VERSION ""

NS_ :

BS_:

BU_: WPC2 PSB SHVU_RR vHS_B2 FCS EMCU SLB GW_APSU GW_DLBCU RCM ARS CGW_CCU vDummy_HS_B GW_RLPSU ATS RLHV SGU PFSU GW_RRPSU ALBCU DSAU SWRC SHVU_FR RCS GW_DPSU BLTN_CAM SCM OHCL RWPC RRHV WPC HOD ASAU

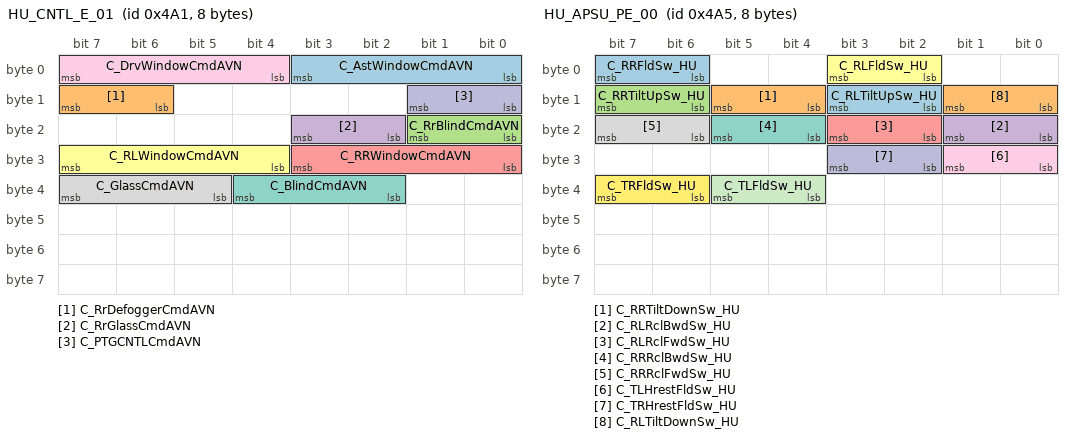
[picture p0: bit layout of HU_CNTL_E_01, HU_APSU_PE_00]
BO_ 1185 HU_CNTL_E_01: 8 CGW_CCU
 SG_ C_AstWindowCmdAVN : 0|4@1+ (1,0) [0|0] ""  Vector__XXX
 SG_ C_RrDefoggerCmdAVN : 14|2@1+ (1,0) [0|0] ""  Vector__XXX
 SG_ C_RrBlindCmdAVN : 16|2@1+ (1,0) [0|0] ""  RCM
 SG_ C_RrGlassCmdAVN : 18|2@1+ (1,0) [0|0] ""  RCM
 SG_ C_RRWindowCmdAVN : 24|4@1+ (1,0) [0|0] ""  Vector__XXX
 SG_ C_RLWindowCmdAVN : 28|4@1+ (1,0) [0|0] ""  Vector__XXX
 SG_ C_BlindCmdAVN : 34|3@1+ (1,0) [0|0] ""  RCM
 SG_ C_GlassCmdAVN : 37|3@1+ (1,0) [0|0] ""  RCM
 SG_ C_DrvWindowCmdAVN : 4|4@1+ (1,0) [0|0] ""  Vector__XXX
 SG_ C_PTGCNTLCmdAVN : 8|2@1+ (1,0) [0|0] ""  Vector__XXX

BO_ 1189 HU_APSU_PE_00: 8 CGW_CCU
 SG_ C_RLTiltUpSw_HU : 10|2@1+ (1,0) [0|0] ""  GW_APSU,GW_RLPSU,GW_RRPSU
 SG_ C_RRTiltDownSw_HU : 12|2@1+ (1,0) [0|0] ""  GW_APSU,GW_RRPSU
 SG_ C_RRTiltUpSw_HU : 14|2@1+ (1,0) [0|0] ""  GW_APSU,GW_RRPSU
 SG_ C_RLRclBwdSw_HU : 16|2@1+ (1,0) [0|0] ""  GW_APSU,GW_RLPSU,GW_RRPSU
 SG_ C_RLRclFwdSw_HU : 18|2@1+ (1,0) [0|0] ""  GW_APSU,GW_RLPSU,GW_RRPSU
 SG_ C_RLFldSw_HU : 2|2@1+ (1,0) [0|0] ""  GW_RLPSU
 SG_ C_RRRclBwdSw_HU : 20|2@1+ (1,0) [0|0] ""  GW_APSU,GW_RRPSU
 SG_ C_RRRclFwdSw_HU : 22|2@1+ (1,0) [0|0] ""  GW_APSU,GW_RRPSU
 SG_ C_TLHrestFldSw_HU : 24|2@1+ (1,0) [0|0] ""  PFSU
 SG_ C_TRHrestFldSw_HU : 26|2@1+ (1,0) [0|0] ""  PFSU
 SG_ C_TLFldSw_HU : 36|2@1+ (1,0) [0|0] ""  PFSU
 SG_ C_TRFldSw_HU : 38|2@1+ (1,0) [0|0] ""  PFSU
 SG_ C_RRFldSw_HU : 6|2@1+ (1,0) [0|0] ""  GW_RRPSU
 SG_ C_RLTiltDownSw_HU : 8|2@1+ (1,0) [0|0] ""  GW_APSU,GW_RLPSU,GW_RRPSU

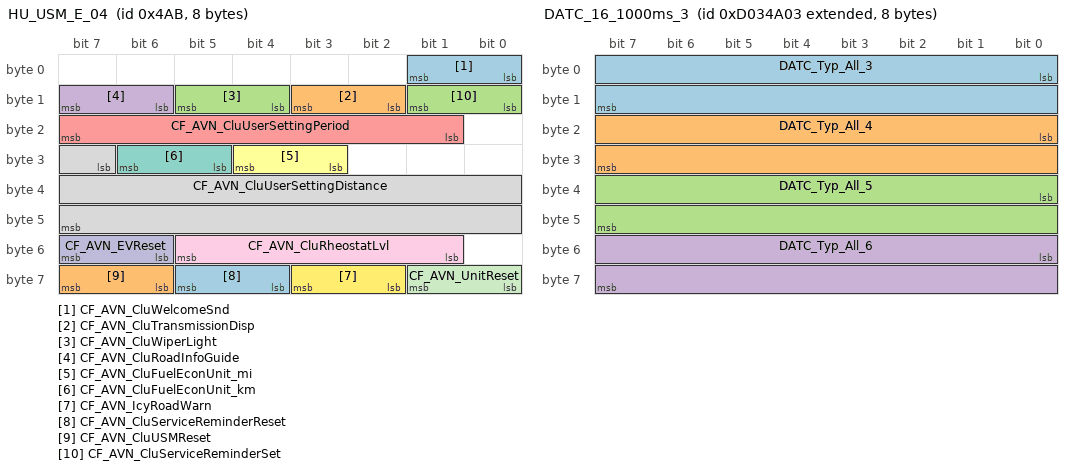
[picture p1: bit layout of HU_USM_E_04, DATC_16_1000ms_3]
BO_ 1195 HU_USM_E_04: 8 CGW_CCU
 SG_ CF_AVN_CluWelcomeSnd : 0|2@1+ (1,0) [0|0] ""  Vector__XXX
 SG_ CF_AVN_CluTransmissionDisp : 10|2@1+ (1,0) [0|0] ""  Vector__XXX
 SG_ CF_AVN_CluWiperLight : 12|2@1+ (1,0) [0|0] ""  Vector__XXX
 SG_ CF_AVN_CluRoadInfoGuide : 14|2@1+ (1,0) [0|0] ""  Vector__XXX
 SG_ CF_AVN_CluUserSettingPeriod : 17|7@1+ (1,0) [0|0] ""  Vector__XXX
 SG_ CF_AVN_CluFuelEconUnit_mi : 27|2@1+ (1,0) [0|0] ""  Vector__XXX
 SG_ CF_AVN_CluFuelEconUnit_km : 29|2@1+ (1,0) [0|0] ""  Vector__XXX
 SG_ CF_AVN_CluUserSettingDistance : 31|17@1+ (1,0) [0|0] ""  Vector__XXX
 SG_ CF_AVN_CluRheostatLvl : 49|5@1+ (1,0) [0|0] ""  Vector__XXX
 SG_ CF_AVN_EVReset : 54|2@1+ (1,0) [0|0] ""  Vector__XXX
 SG_ CF_AVN_UnitReset : 56|2@1+ (1,0) [0|0] ""  Vector__XXX
 SG_ CF_AVN_IcyRoadWarn : 58|2@1+ (1,0) [0|0] ""  Vector__XXX
 SG_ CF_AVN_CluServiceReminderReset : 60|2@1+ (1,0) [0|0] ""  Vector__XXX
 SG_ CF_AVN_CluUSMReset : 62|2@1+ (1,0) [0|0] ""  ALBCU,ARS,ASAU,ATS,BLTN_CAM,DSAU,GW_APSU,GW_DLBCU,GW_DPSU,GW_RLPSU,GW_RRPSU,PFSU,RCM,RLHV,RRHV,RWPC,SGU,SHVU_FR,SHVU_RR,SLB,WPC,WPC2
 SG_ CF_AVN_CluServiceReminderSet : 8|2@1+ (1,0) [0|0] ""  Vector__XXX

BO_ 1193 HU_USM_E_02: 8 CGW_CCU
 SG_ C_PTGMNValueSet : 0|2@1+ (1,0) [0|0] ""  Vector__XXX
 SG_ CF_AVN_PSMNValueSet : 10|3@1+ (1,0) [0|0] ""  GW_DPSU
 SG_ C_HfreeTrunkTgNValueSet : 13|3@1+ (1,0) [0|0] ""  Vector__XXX
 SG_ CF_AVN_TrfChgSet : 17|2@1+ (1,0) [0|0] ""  Vector__XXX
 SG_ CF_AVN_SCMNValueSet : 19|2@1+ (1,0) [0|0] ""  Vector__XXX
 SG_ CF_AVN_ADrUNValueSet : 2|3@1+ (1,0) [0|0] ""  Vector__XXX
 SG_ CF_AVN_OTTurnNValueSet : 21|3@1+ (1,0) [0|0] ""  Vector__XXX
 SG_ CF_Gway_WPCNValueSet : 24|2@1+ (1,0) [0|0] ""  WPC,WPC2
 SG_ C_AVN_RearWiperNValueSet : 26|2@1+ (1,0) [0|0] ""  Vector__XXX
 SG_ C_UnlockWelocomeNValueSet : 28|2@1+ (1,0) [0|0] ""  Vector__XXX
 SG_ C_SmartWelocomeNValueSet : 30|2@1+ (1,0) [0|0] ""  Vector__XXX
 SG_ CF_AVN_PTGSpeedNValueSet : 32|2@1+ (1,0) [0|0] ""  Vector__XXX
 SG_ CR_Datc_DRSeatWheel_USM_Set : 34|2@1+ (1,0) [0|0] ""  Vector__XXX
 SG_ CF_AVN_TTUnlockNValueSet : 38|2@1+ (1,0) [0|0] ""  Vector__XXX
 SG_ CF_Gway_RWPCNValueSet : 40|2@1+ (1,0) [0|0] ""  RWPC
 SG_ CF_Avn_HAPTICWARNINGNValueSet : 49|3@1+ (1,0) [0|0] ""  Vector__XXX
 SG_ CR_Datc_DRSeatHeat_USM_Set : 52|2@1+ (1,0) [0|0] ""  Vector__XXX
 SG_ C_WALNValueSet : 54|2@1+ (1,0) [0|0] ""  Vector__XXX
 SG_ C_ApprUnlockNValue : 56|2@1+ (1,0) [0|0] ""  Vector__XXX
 SG_ CF_AVN_EscortHLNValueSet : 8|2@1+ (1,0) [0|0] ""  Vector__XXX

BO_ 2365803012 DATC_16_1000ms_4: 8 CGW_CCU
 SG_ DATC_Opt_Sys : 0|32@1+ (1,0) [0|0] ""  Vector__XXX
 SG_ DATC_Opt_Func : 32|32@1+ (1,0) [0|0] ""  Vector__XXX

BO_ 2365803011 DATC_16_1000ms_3: 8 CGW_CCU
 SG_ DATC_Typ_All_3 : 0|16@1+ (1,0) [0|0] ""  Vector__XXX
 SG_ DATC_Typ_All_4 : 16|16@1+ (1,0) [0|0] ""  Vector__XXX
 SG_ DATC_Typ_All_5 : 32|16@1+ (1,0) [0|0] ""  Vector__XXX
 SG_ DATC_Typ_All_6 : 48|16@1+ (1,0) [0|0] ""  Vector__XXX

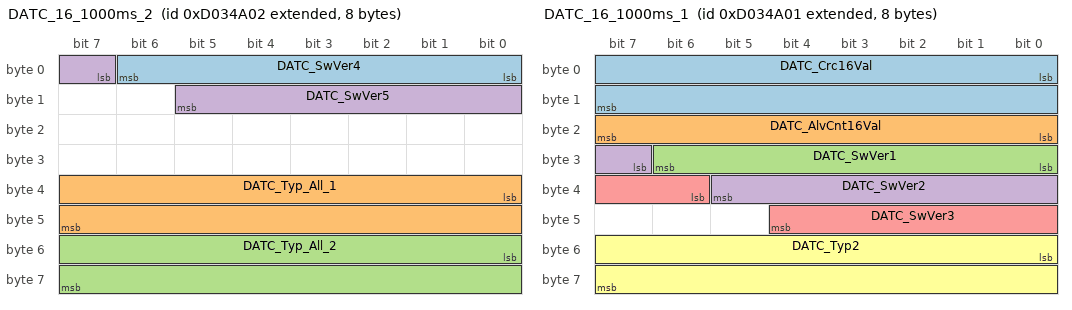
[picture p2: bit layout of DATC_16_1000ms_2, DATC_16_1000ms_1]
BO_ 2365803010 DATC_16_1000ms_2: 8 CGW_CCU
 SG_ DATC_SwVer4 : 0|7@1+ (1,0) [0|0] ""  Vector__XXX
 SG_ DATC_Typ_All_1 : 32|16@1+ (1,0) [0|0] ""  Vector__XXX
 SG_ DATC_Typ_All_2 : 48|16@1+ (1,0) [0|0] ""  Vector__XXX
 SG_ DATC_SwVer5 : 7|7@1+ (1,0) [0|0] ""  Vector__XXX

BO_ 2365803009 DATC_16_1000ms_1: 8 CGW_CCU
 SG_ DATC_Crc16Val : 0|16@1+ (1,0) [0|0] ""  Vector__XXX
 SG_ DATC_AlvCnt16Val : 16|8@1+ (1,0) [0|0] ""  Vector__XXX
 SG_ DATC_SwVer1 : 24|7@1+ (1,0) [0|0] ""  Vector__XXX
 SG_ DATC_SwVer2 : 31|7@1+ (1,0) [0|0] ""  Vector__XXX
 SG_ DATC_SwVer3 : 38|7@1+ (1,0) [0|0] ""  Vector__XXX
 SG_ DATC_Typ2 : 48|16@1+ (1,0) [0|0] ""  ATS

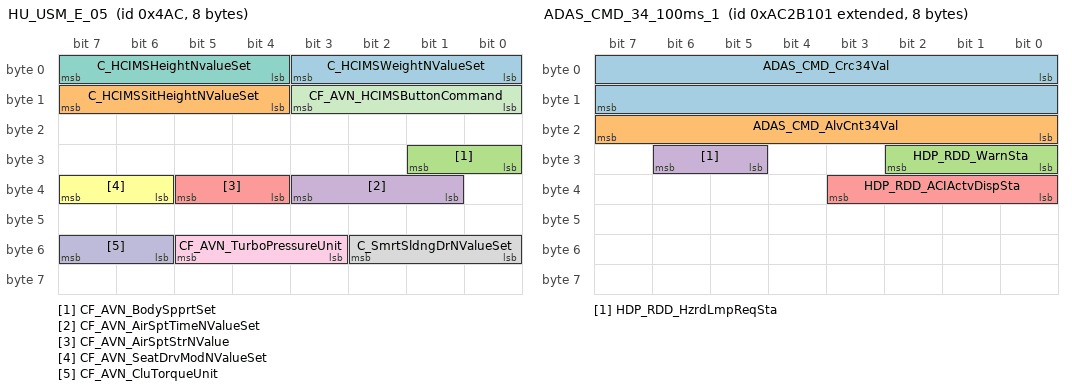
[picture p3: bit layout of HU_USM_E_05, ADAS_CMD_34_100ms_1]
BO_ 1196 HU_USM_E_05: 8 CGW_CCU
 SG_ C_HCIMSWeightNValueSet : 0|4@1+ (1,0) [0|0] ""  GW_DPSU
 SG_ C_HCIMSSitHeightNValueSet : 12|4@1+ (1,0) [0|0] ""  GW_DPSU
 SG_ CF_AVN_BodySpprtSet : 24|2@1+ (1,0) [0|0] ""  DSAU,GW_DLBCU,GW_DPSU
 SG_ CF_AVN_AirSptTimeNValueSet : 33|3@1+ (1,0) [0|0] ""  GW_DLBCU
 SG_ CF_AVN_AirSptStrNValue : 36|2@1+ (1,0) [0|0] ""  GW_DLBCU
 SG_ CF_AVN_SeatDrvModNValueSet : 38|2@1+ (1,0) [0|0] ""  DSAU,GW_DLBCU,GW_DPSU
 SG_ C_HCIMSHeightNvalueSet : 4|4@1+ (1,0) [0|0] ""  GW_DPSU
 SG_ C_SmrtSldngDrNValueSet : 48|3@1+ (1,0) [0|0] ""  Vector__XXX
 SG_ CF_AVN_TurboPressureUnit : 51|3@1+ (1,0) [0|0] ""  Vector__XXX
 SG_ CF_AVN_CluTorqueUnit : 54|2@1+ (1,0) [0|0] ""  Vector__XXX
 SG_ CF_AVN_HCIMSButtonCommand : 8|4@1+ (1,0) [0|0] ""  GW_DPSU

BO_ 2328015108 ADAS_CMD_34_100ms_4: 8 CGW_CCU

BO_ 255 BCM_20_200ms: 8 CGW_CCU
 SG_ BCM_Crc20Val : 0|8@1+ (1,0) [0|0] ""  RCM
 SG_ Window_BuffetRdctnActvSta : 10|2@1+ (1,0) [0|0] ""  Vector__XXX
 SG_ BCM_AlvCnt20Val : 12|4@1+ (1,0) [0|0] ""  RCM
 SG_ BckGls_RrGlsHtdOnCmd : 16|2@1+ (1,0) [0|0] ""  Vector__XXX
 SG_ Wndshld_FrtGlsHtdOnCmd : 18|2@1+ (1,0) [0|0] ""  Vector__XXX
 SG_ Mirror_MirFldOpt : 20|2@1+ (1,0) [0|0] ""  Vector__XXX
 SG_ Window_AsstPwrWdwSunroofEnblSta : 22|2@1+ (1,0) [0|0] ""  RCM
 SG_ Window_RrPwrWdwEnblSta : 24|2@1+ (1,0) [0|0] ""  RCM
 SG_ Window_RrPwrWdwLkInd : 26|2@1+ (1,0) [0|0] ""  Vector__XXX
 SG_ Window_DrvPwrWdwCmd : 28|2@1+ (1,0) [0|0] ""  Vector__XXX
 SG_ Window_AsstPwrWdwCmd : 30|2@1+ (1,0) [0|0] ""  Vector__XXX
 SG_ Window_RrLftPwrWdwCmd : 32|2@1+ (1,0) [0|0] ""  Vector__XXX
 SG_ Window_RrRtPwrWdwCmd : 34|2@1+ (1,0) [0|0] ""  Vector__XXX
 SG_ Mirror_FldUnfldCmd : 36|2@1+ (1,0) [0|0] ""  Vector__XXX
 SG_ Mirror_FldCtrlSta : 38|2@1+ (1,0) [0|0] ""  Vector__XXX
 SG_ Mirror_UnFldCtrlSta : 40|2@1+ (1,0) [0|0] ""  Vector__XXX
 SG_ Mirror_PosMnlCmd : 42|3@1+ (1,0) [0|0] ""  Vector__XXX
 SG_ Mirror_SelSwIndCmd : 45|3@1+ (1,0) [0|0] ""  Vector__XXX
 SG_ BCM_SafetyWdwOptTyp2 : 49|3@1+ (1,0) [0|0] ""  Vector__XXX
 SG_ Mirror_LHOSMirPlyBckSta : 52|4@1+ (1,0) [0|0] ""  GW_DPSU
 SG_ Mirror_RHOSMirPlyBckSta : 56|4@1+ (1,0) [0|0] ""  GW_DPSU
 SG_ Mirror_SelSwSta : 60|3@1+ (1,0) [0|0] ""  Vector__XXX
 SG_ BckGls_RrGlsHtdOpt : 8|2@1+ (1,0) [0|0] ""  Vector__XXX

BO_ 2328015105 ADAS_CMD_34_100ms_1: 8 CGW_CCU
 SG_ ADAS_CMD_Crc34Val : 0|16@1+ (1,0) [0|0] ""  Vector__XXX
 SG_ ADAS_CMD_AlvCnt34Val : 16|8@1+ (1,0) [0|0] ""  Vector__XXX
 SG_ HDP_RDD_WarnSta : 24|3@1+ (1,0) [0|0] ""  HOD,PSB
 SG_ HDP_RDD_HzrdLmpReqSta : 29|2@1+ (1,0) [0|0] ""  Vector__XXX
 SG_ HDP_RDD_ACIActvDispSta : 32|4@1+ (1,0) [0|0] ""  Vector__XXX

BO_ 2328015106 ADAS_CMD_34_100ms_2: 8 CGW_CCU
 SG_ HDP_RDD_EMStbltActvReqSta : 8|3@1+ (1,0) [0|0] ""  PSB

BO_ 2328015107 ADAS_CMD_34_100ms_3: 8 CGW_CCU

BO_ 273 ARS_04_00ms: 8 ARS
 SG_ ARS_RrCurtainBtn : 0|2@1+ (1,0) [0|0] ""  Vector__XXX

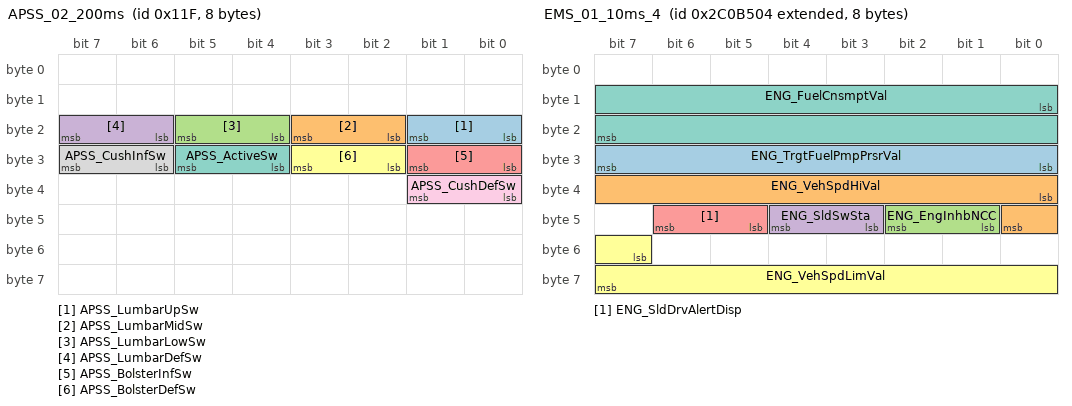
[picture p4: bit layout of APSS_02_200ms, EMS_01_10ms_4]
BO_ 287 APSS_02_200ms: 8 GW_APSU
 SG_ APSS_LumbarUpSw : 16|2@1+ (1,0) [0|0] ""  ALBCU,CGW_CCU
 SG_ APSS_LumbarMidSw : 18|2@1+ (1,0) [0|0] ""  ALBCU,CGW_CCU
 SG_ APSS_LumbarLowSw : 20|2@1+ (1,0) [0|0] ""  ALBCU,CGW_CCU
 SG_ APSS_LumbarDefSw : 22|2@1+ (1,0) [0|0] ""  ALBCU,CGW_CCU
 SG_ APSS_BolsterInfSw : 24|2@1+ (1,0) [0|0] ""  ALBCU,CGW_CCU
 SG_ APSS_BolsterDefSw : 26|2@1+ (1,0) [0|0] ""  ALBCU,CGW_CCU
 SG_ APSS_ActiveSw : 28|2@1+ (1,0) [0|0] ""  ALBCU
 SG_ APSS_CushInfSw : 30|2@1+ (1,0) [0|0] ""  ALBCU
 SG_ APSS_CushDefSw : 32|2@1+ (1,0) [0|0] ""  ALBCU

BO_ 2193667332 EMS_01_10ms_4: 8 CGW_CCU
 SG_ ENG_TrgtFuelPmpPrsrVal : 24|8@1+ (3.137254902,0) [0|0] "kPa"  Vector__XXX
 SG_ ENG_VehSpdHiVal : 32|9@1+ (1,0) [0|0] "km/h"  Vector__XXX
 SG_ ENG_EngInhbNCC : 41|2@1+ (1,0) [0|0] ""  Vector__XXX
 SG_ ENG_SldSwSta : 43|2@1+ (1,0) [0|0] ""  Vector__XXX
 SG_ ENG_SldDrvAlertDisp : 45|2@1+ (1,0) [0|0] ""  Vector__XXX
 SG_ ENG_VehSpdLimVal : 55|9@1+ (1,0) [0|0] "km/h"  Vector__XXX
 SG_ ENG_FuelCnsmptVal : 8|16@1+ (0.128,0) [0|0] "ul"  Vector__XXX

BO_ 2193667331 EMS_01_10ms_3: 8 CGW_CCU
 SG_ ENG_TrgtIdleRpmVal : 0|8@1+ (10,0) [0|0] "rpm"  Vector__XXX
 SG_ ENG_GearShftDnDis : 10|2@1+ (1,0) [0|0] ""  Vector__XXX
 SG_ ENG_DsrGearPosDis : 12|4@1+ (1,0) [0|0] ""  Vector__XXX
 SG_ ENG_SldFuncSta : 16|2@1+ (1,0) [0|0] ""  Vector__XXX
 SG_ ENG_SldActnSta : 18|2@1+ (1,0) [0|0] ""  Vector__XXX
 SG_ ENG_FuelTnkPrsrSta : 20|2@1+ (1,0) [0|0] ""  Vector__XXX
 SG_ ENG_IsgBzrReq : 22|2@1+ (1,0) [0|0] ""  Vector__XXX
 SG_ ENG_IsgFuelCnsmptDis : 24|2@1+ (1,0) [0|0] ""  Vector__XXX
 SG_ ENG_FuelCapOpnSta : 26|2@1+ (1,0) [0|0] ""  Vector__XXX
 SG_ ENG_EcoDrvActvSta : 28|2@1+ (1,0) [0|0] ""  Vector__XXX
 SG_ ENG_EngRunSta : 30|2@1+ (1,0) [0|0] ""  Vector__XXX
 SG_ ENG_Isg2Sta : 32|2@1+ (2,0) [0|0] ""  Vector__XXX
 SG_ ENG_IgnOnSta : 34|2@1+ (1,0) [0|0] ""  Vector__XXX
 SG_ ENG_Ack4TcsSta : 36|2@1+ (1,0) [0|0] ""  Vector__XXX
 SG_ ENG_FuelCutOffSta : 38|2@1+ (1,0) [0|0] ""  Vector__XXX
 SG_ ENG_CrctTqSta : 40|2@1+ (1,0) [0|0] ""  Vector__XXX
 SG_ ENG_AirCompRlySta : 42|2@1+ (1,0) [0|0] ""  Vector__XXX
 SG_ ENG_LnchCntrlSta : 45|3@1+ (1,0) [0|0] ""  Vector__XXX
 SG_ ENG_EngSpdVal : 48|16@1+ (0.25,0) [0|0] "rpm"  EMCU
 SG_ ENG_GearShftUpDis : 8|2@1+ (1,0) [0|0] ""  Vector__XXX

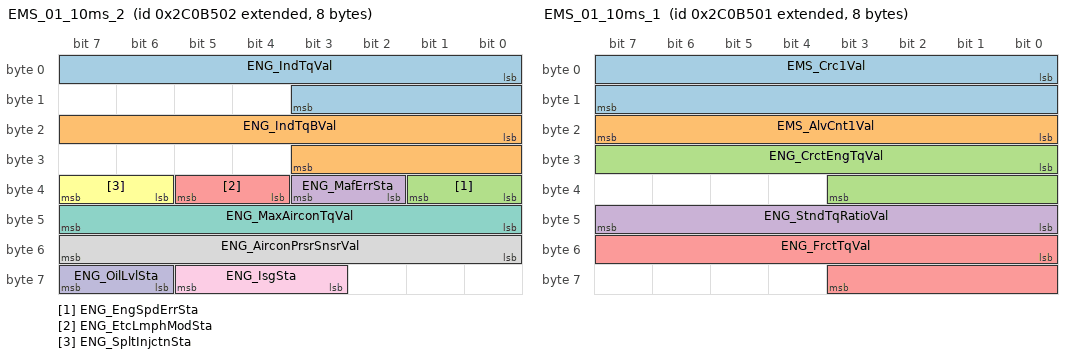
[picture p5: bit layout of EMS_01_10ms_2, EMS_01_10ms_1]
BO_ 2193667330 EMS_01_10ms_2: 8 CGW_CCU
 SG_ ENG_IndTqVal : 0|12@1- (1,0) [0|0] "Nm"  Vector__XXX
 SG_ ENG_IndTqBVal : 16|12@1- (1,0) [0|0] "Nm"  Vector__XXX
 SG_ ENG_EngSpdErrSta : 32|2@1+ (1,0) [0|0] ""  Vector__XXX
 SG_ ENG_MafErrSta : 34|2@1+ (1,0) [0|0] ""  Vector__XXX
 SG_ ENG_EtcLmphModSta : 36|2@1+ (1,0) [0|0] ""  Vector__XXX
 SG_ ENG_SpltInjctnSta : 38|2@1+ (1,0) [0|0] ""  Vector__XXX
 SG_ ENG_MaxAirconTqVal : 40|8@1+ (0.2,0) [0|0] "Nm"  Vector__XXX
 SG_ ENG_AirconPrsrSnsrVal : 48|8@1+ (125,0) [0|0] "hPa"  Vector__XXX
 SG_ ENG_IsgSta : 59|3@1+ (1,0) [0|0] ""  EMCU,GW_APSU,GW_DPSU,GW_RLPSU,GW_RRPSU,RLHV,RRHV,SHVU_FR,SHVU_RR
 SG_ ENG_OilLvlSta : 62|2@1+ (1,0) [0|0] ""  Vector__XXX

BO_ 2193667329 EMS_01_10ms_1: 8 CGW_CCU
 SG_ EMS_Crc1Val : 0|16@1+ (1,0) [0|0] ""  Vector__XXX
 SG_ EMS_AlvCnt1Val : 16|8@1+ (1,0) [0|0] ""  Vector__XXX
 SG_ ENG_CrctEngTqVal : 24|12@1- (1,0) [0|0] "Nm"  Vector__XXX
 SG_ ENG_StndTqRatioVal : 40|8@1+ (0.0078,0) [0|0] ""  Vector__XXX
 SG_ ENG_FrctTqVal : 48|12@1- (1,0) [0|0] "Nm"  Vector__XXX

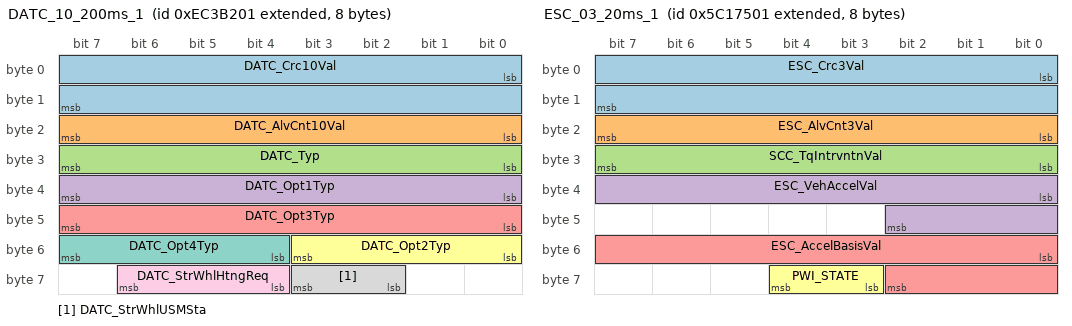
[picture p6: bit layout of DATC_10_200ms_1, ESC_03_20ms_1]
BO_ 2395189761 DATC_10_200ms_1: 8 CGW_CCU
 SG_ DATC_Crc10Val : 0|16@1+ (1,0) [0|0] ""  Vector__XXX
 SG_ DATC_AlvCnt10Val : 16|8@1+ (1,0) [0|0] ""  Vector__XXX
 SG_ DATC_Typ : 24|8@1+ (1,0) [0|0] ""  ATS,RLHV,RRHV,SHVU_FR,SHVU_RR
 SG_ DATC_Opt1Typ : 32|8@1+ (1,0) [0|0] ""  ATS
 SG_ DATC_Opt3Typ : 40|8@1+ (1,0) [0|0] ""  ATS
 SG_ DATC_Opt2Typ : 48|4@1+ (1,0) [0|0] ""  ATS
 SG_ DATC_Opt4Typ : 52|4@1+ (1,0) [0|0] ""  ATS
 SG_ DATC_StrWhlUSMSta : 58|2@1+ (1,0) [0|0] ""  GW_APSU
 SG_ DATC_StrWhlHtngReq : 60|3@1+ (1,0) [0|0] ""  Vector__XXX

BO_ 2244048129 ESC_03_20ms_1: 8 CGW_CCU
 SG_ ESC_Crc3Val : 0|16@1+ (1,0) [0|0] ""  Vector__XXX
 SG_ ESC_AlvCnt3Val : 16|8@1+ (1,0) [0|0] ""  Vector__XXX
 SG_ SCC_TqIntrvntnVal : 24|8@1+ (0.390625,0) [0|0] "%"  Vector__XXX
 SG_ ESC_VehAccelVal : 32|11@1+ (0.01,-10.23) [0|0] "m/s^2"  Vector__XXX
 SG_ ESC_AccelBasisVal : 48|11@1+ (0.01,-10.23) [0|0] "m/s^2"  Vector__XXX
 SG_ PWI_STATE : 59|2@1+ (1,0) [0|0] ""  Vector__XXX

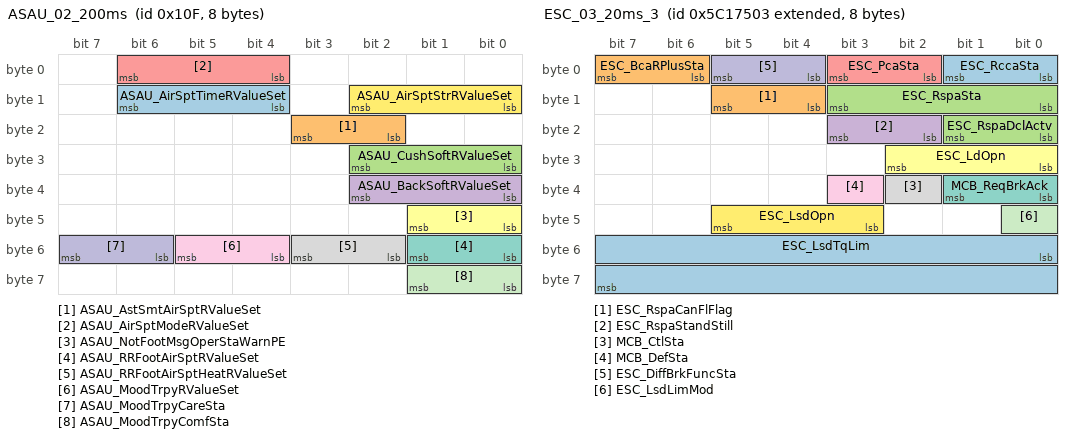
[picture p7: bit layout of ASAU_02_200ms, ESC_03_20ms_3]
BO_ 271 ASAU_02_200ms: 8 ASAU
 SG_ ASAU_AirSptTimeRValueSet : 12|3@1+ (1,0) [0|0] ""  CGW_CCU
 SG_ ASAU_AstSmtAirSptRValueSet : 18|2@1+ (1,0) [0|0] ""  CGW_CCU
 SG_ ASAU_CushSoftRValueSet : 24|3@1+ (1,0) [0|0] ""  CGW_CCU
 SG_ ASAU_BackSoftRValueSet : 32|3@1+ (1,0) [0|0] ""  Vector__XXX
 SG_ ASAU_AirSptModeRValueSet : 4|3@1+ (1,0) [0|0] ""  CGW_CCU
 SG_ ASAU_NotFootMsgOperStaWarnPE : 40|2@1+ (1,0) [0|0] ""  ATS
 SG_ ASAU_RRFootAirSptRValueSet : 48|2@1+ (1,0) [0|0] ""  ATS
 SG_ ASAU_RRFootAirSptHeatRValueSet : 50|2@1+ (1,0) [0|0] ""  ATS
 SG_ ASAU_MoodTrpyRValueSet : 52|2@1+ (1,0) [0|0] ""  CGW_CCU
 SG_ ASAU_MoodTrpyCareSta : 54|2@1+ (1,0) [0|0] ""  CGW_CCU
 SG_ ASAU_MoodTrpyComfSta : 56|2@1+ (1,0) [0|0] ""  CGW_CCU
 SG_ ASAU_AirSptStrRValueSet : 8|3@1+ (1,0) [0|0] ""  CGW_CCU

BO_ 2244048131 ESC_03_20ms_3: 8 CGW_CCU
 SG_ ESC_RccaSta : 0|2@1+ (1,0) [0|0] ""  Vector__XXX
 SG_ ESC_RspaCanFlFlag : 12|2@1+ (1,0) [0|0] ""  Vector__XXX
 SG_ ESC_RspaDclActv : 16|2@1+ (1,0) [0|0] ""  Vector__XXX
 SG_ ESC_RspaStandStill : 18|2@1+ (1,0) [0|0] ""  Vector__XXX
 SG_ ESC_PcaSta : 2|2@1+ (1,0) [0|0] ""  Vector__XXX
 SG_ ESC_LdOpn : 24|3@1+ (1,0) [0|0] ""  Vector__XXX
 SG_ MCB_ReqBrkAck : 32|2@1+ (1,0) [0|0] ""  Vector__XXX
 SG_ MCB_CtlSta : 34|1@1+ (1,0) [0|0] ""  Vector__XXX
 SG_ MCB_DefSta : 35|1@1+ (1,0) [0|0] ""  Vector__XXX
 SG_ ESC_DiffBrkFuncSta : 4|2@1+ (1,0) [0|0] ""  Vector__XXX
 SG_ ESC_LsdLimMod : 40|1@1+ (1,0) [0|0] ""  Vector__XXX
 SG_ ESC_LsdOpn : 43|3@1+ (1,0) [0|0] ""  Vector__XXX
 SG_ ESC_LsdTqLim : 48|16@1+ (1,0) [0|0] "Nm"  Vector__XXX
 SG_ ESC_BcaRPlusSta : 6|2@1+ (1,0) [0|0] ""  Vector__XXX
 SG_ ESC_RspaSta : 8|4@1+ (1,0) [0|0] ""  Vector__XXX

BO_ 2244048130 ESC_03_20ms_2: 8 CGW_CCU
 SG_ SCC_OptTyp : 0|2@1+ (1,0) [0|0] ""  Vector__XXX
 SG_ ESC_BrkLtReq : 10|2@1+ (1,0) [0|0] ""  Vector__XXX
 SG_ ESC_DclEnblReq : 12|2@1+ (1,0) [0|0] ""  Vector__XXX
 SG_ ESC_DrvOvrdSta : 16|2@1+ (1,0) [0|0] ""  Vector__XXX
 SG_ ESC_DrvBrkSta : 18|2@1+ (1,0) [0|0] ""  Vector__XXX
 SG_ SCC_EnblReq : 2|2@1+ (1,0) [0|0] ""  Vector__XXX
 SG_ ESC_DrvBrkActvSta : 20|2@1+ (1,0) [0|0] ""  Vector__XXX
 SG_ ESC_PrkBrkActvSta : 22|2@1+ (1,0) [0|0] ""  Vector__XXX
 SG_ ESC_HDP_FltMonSta : 24|3@1+ (1,0) [0|0] ""  PSB
 SG_ ESC_HDPSpprtSWVer : 27|5@1+ (1,0) [0|0] ""  Vector__XXX
 SG_ FCA_EquipSta : 32|2@1+ (1,0) [0|0] ""  Vector__XXX
 SG_ FCA_AvlblSta : 34|2@1+ (1,0) [0|0] ""  Vector__XXX
 SG_ ESC_FCA_ActvSta : 36|2@1+ (1,0) [0|0] ""  Vector__XXX
 SG_ ESC_DBS_ActvSta : 38|2@1+ (1,0) [0|0] ""  Vector__XXX
 SG_ SCC_TqReq : 4|2@1+ (1,0) [0|0] ""  Vector__XXX
 SG_ ESC_HDP_EgSta : 40|3@1+ (1,0) [0|0] ""  PSB
 SG_ ESC_HDP_EnblReq : 43|3@1+ (1,0) [0|0] ""  Vector__XXX
 SG_ CSC_Sta : 48|2@1+ (1,0) [0|0] ""  Vector__XXX
 SG_ CSC_WrngSta : 50|2@1+ (1,0) [0|0] ""  Vector__XXX
 SG_ ESC_BrkdFltStndstill : 56|2@1+ (1,0) [0|0] ""  Vector__XXX
 SG_ SCC_ReqLimSta : 6|2@1+ (1,0) [0|0] ""  Vector__XXX
 SG_ ESC_StdStillVal : 8|2@1+ (1,0) [0|0] ""  Vector__XXX

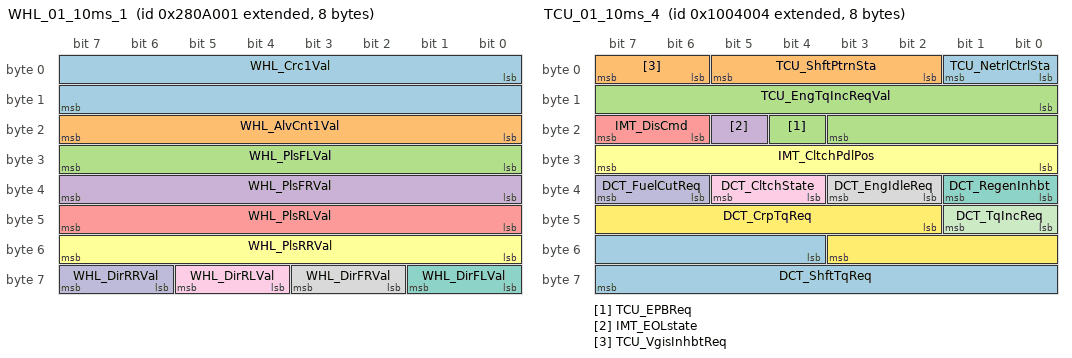
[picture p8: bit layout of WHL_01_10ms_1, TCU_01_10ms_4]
BO_ 2189467649 WHL_01_10ms_1: 8 CGW_CCU
 SG_ WHL_Crc1Val : 0|16@1+ (1,0) [0|0] ""  Vector__XXX
 SG_ WHL_AlvCnt1Val : 16|8@1+ (1,0) [0|0] ""  Vector__XXX
 SG_ WHL_PlsFLVal : 24|8@1+ (0.5,0) [0|0] "pulse count"  Vector__XXX
 SG_ WHL_PlsFRVal : 32|8@1+ (0.5,0) [0|0] "pulse count"  Vector__XXX
 SG_ WHL_PlsRLVal : 40|8@1+ (0.5,0) [0|0] "pulse count"  Vector__XXX
 SG_ WHL_PlsRRVal : 48|8@1+ (0.5,0) [0|0] "pulse count"  Vector__XXX
 SG_ WHL_DirFLVal : 56|2@1+ (1,0) [0|0] ""  Vector__XXX
 SG_ WHL_DirFRVal : 58|2@1+ (1,0) [0|0] ""  Vector__XXX
 SG_ WHL_DirRLVal : 60|2@1+ (1,0) [0|0] ""  Vector__XXX
 SG_ WHL_DirRRVal : 62|2@1+ (1,0) [0|0] ""  Vector__XXX

BO_ 2164277252 TCU_01_10ms_4: 8 CGW_CCU
 SG_ TCU_NetrlCtrlSta : 0|2@1+ (1,0) [0|0] ""  Vector__XXX
 SG_ TCU_ShftPtrnSta : 2|4@1+ (1,0) [0|0] ""  Vector__XXX
 SG_ TCU_EPBReq : 20|1@1+ (1,0) [0|0] ""  Vector__XXX
 SG_ IMT_EOLstate : 21|1@1+ (1,0) [0|0] ""  Vector__XXX
 SG_ IMT_DisCmd : 22|2@1+ (1,0) [0|0] ""  Vector__XXX
 SG_ IMT_CltchPdlPos : 24|8@1+ (0.390625,0) [0|0] "%"  Vector__XXX
 SG_ DCT_RegenInhbt : 32|2@1+ (1,0) [0|0] ""  Vector__XXX
 SG_ DCT_EngIdleReq : 34|2@1+ (1,0) [0|0] ""  Vector__XXX
 SG_ DCT_CltchState : 36|2@1+ (1,0) [0|0] ""  Vector__XXX
 SG_ DCT_FuelCutReq : 38|2@1+ (1,0) [0|0] ""  Vector__XXX
 SG_ DCT_TqIncReq : 40|2@1+ (1,0) [0|0] ""  Vector__XXX
 SG_ DCT_CrpTqReq : 42|10@1+ (1,-512) [0|0] "Nm"  Vector__XXX
 SG_ DCT_ShftTqReq : 52|12@1- (1,0) [0|0] "Nm"  Vector__XXX
 SG_ TCU_VgisInhbtReq : 6|2@1+ (1,0) [0|0] ""  Vector__XXX
 SG_ TCU_EngTqIncReqVal : 8|12@1- (1,0) [0|0] "Nm"  Vector__XXX

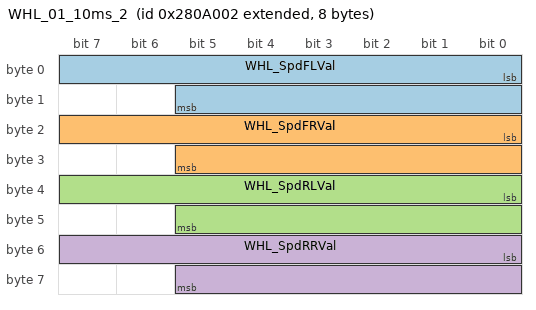
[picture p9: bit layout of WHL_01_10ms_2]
BO_ 2189467650 WHL_01_10ms_2: 8 CGW_CCU
 SG_ WHL_SpdFLVal : 0|14@1+ (0.03125,0) [0|0] "km^h"  PSB
 SG_ WHL_SpdFRVal : 16|14@1+ (0.03125,0) [0|0] "km^h"  PSB
 SG_ WHL_SpdRLVal : 32|14@1+ (0.03125,0) [0|0] "km^h"  GW_APSU,PSB
 SG_ WHL_SpdRRVal : 48|14@1+ (0.03125,0) [0|0] "km^h"  GW_APSU,PSB

BO_ 2189467651 WHL_01_10ms_3: 8 CGW_CCU
 SG_ WHL_SpdCalParmtr : 8|9@1+ (0.5,200) [0|0] "mm"  Vector__XXX

CM_ BO_ 2328015105 "[P] Periodic";
CM_ SG_ 2328015105 ADAS_CMD_Crc34Val "ADAS_CMD_CyclicRedundancyCheck34Value";
CM_ SG_ 2328015105 ADAS_CMD_AlvCnt34Val "ADAS_CMD_AliveCounter34Value";
CM_ SG_ 2328015105 HDP_RDD_WarnSta "HDP_RDD Warning State";
CM_ SG_ 2328015105 HDP_RDD_HzrdLmpReqSta "HDP_RDD Hazard Lamp Request State";
CM_ SG_ 2328015105 HDP_RDD_ACIActvDispSta "HDP_RDD AngleControlInterface Active Display State";
CM_ BO_ 2328015106 "[P] Periodic";
CM_ SG_ 2328015106 HDP_RDD_EMStbltActvReqSta "HDP_RDD EM Seatbelt Activate Request State";
CM_ BO_ 2328015107 "[P] Periodic";
CM_ BO_ 2328015108 "[P] Periodic";
CM_ BO_ 287 "[PE] Periodic and On Event";
CM_ SG_ 287 APSS_LumbarUpSw "APSS_LumbarUpMoveSwitch";
CM_ SG_ 287 APSS_LumbarMidSw "APSS_LumbarMiddleSwitch";
CM_ SG_ 287 APSS_LumbarLowSw "APSS_LumbarLowerSwitch";
CM_ SG_ 287 APSS_LumbarDefSw "APSS_LumbarDeflationSwitch";
CM_ SG_ 287 APSS_BolsterInfSw "APSS_BolsterInflationSwitch";
CM_ SG_ 287 APSS_BolsterDefSw "APSS_BolsterDeflationSwitch";
CM_ SG_ 287 APSS_ActiveSw "APSS_ActiveSwitch";
CM_ SG_ 287 APSS_CushInfSw "APSS_Cush Support Inflation Switch";
CM_ SG_ 287 APSS_CushDefSw "APSS_Cush Support Deflation Switch";
CM_ BO_ 273 "[EC] On Event and On Change";
CM_ SG_ 273 ARS_RrCurtainBtn "Rear Curtain Button";
CM_ BO_ 271 "[PE] Periodic and On Event";
CM_ SG_ 271 ASAU_AirSptTimeRValueSet "Air Support Time(Massage Time) USM R Value";
CM_ SG_ 271 ASAU_AstSmtAirSptRValueSet "Seat Smart Air Support Function USM R Value";
CM_ SG_ 271 ASAU_CushSoftRValueSet "Cushion Soft R Value";
CM_ SG_ 271 ASAU_BackSoftRValueSet "Back Soft USM R Value";
CM_ SG_ 271 ASAU_AirSptModeRValueSet "Air Support Mode(Massage Mode) USM R Value";
CM_ SG_ 271 ASAU_NotFootMsgOperStaWarnPE "Passenger Foot Massage Operation Disable Mode";
CM_ SG_ 271 ASAU_RRFootAirSptRValueSet "Foot Air Support USM R Value";
CM_ SG_ 271 ASAU_RRFootAirSptHeatRValueSet "Foot Air Support Heat USM R Value";
CM_ SG_ 271 ASAU_MoodTrpyRValueSet "Passenger Seat Mood Therapy R Value";
CM_ SG_ 271 ASAU_MoodTrpyCareSta "Passenger Seat Mood Therapy Care Mode R Value";
CM_ SG_ 271 ASAU_MoodTrpyComfSta "Passenger Seat Mood Therapy Comfort Mode R Value";
CM_ SG_ 271 ASAU_AirSptStrRValueSet "Air Support Strenth(Massage Strenth) USM R Value";
CM_ BO_ 255 "[PE] Periodic and On Event";
CM_ SG_ 255 BCM_Crc20Val "BCM_CyclicRedundancyCheck20Value";
CM_ SG_ 255 BCM_AlvCnt20Val "BCM_AliveCounter20Value";
CM_ SG_ 255 Mirror_MirFldOpt "Outside Mirror Electric Fold Option Signal";
CM_ SG_ 255 Mirror_FldUnfldCmd "Mirror Folding Unfolding Command";
CM_ SG_ 255 Mirror_FldCtrlSta "Mirror Fold and Folding Control State";
CM_ SG_ 255 Mirror_UnFldCtrlSta "Mirror Unfold and Unfolding Control State";
CM_ SG_ 255 Mirror_PosMnlCmd "Mirror Positioning Command";
CM_ SG_ 255 Mirror_SelSwIndCmd "Mirror Select Switch Indicator Command";
CM_ SG_ 255 Mirror_LHOSMirPlyBckSta "This siganl indicates Left O/S Mirror moving state for IMS From BDC";
CM_ SG_ 255 Mirror_RHOSMirPlyBckSta "This siganl indicates Right O/S Mirror moving state for IMS From BDC";
CM_ SG_ 255 Mirror_SelSwSta "Outside Mirror Select Button Status";
CM_ SG_ 255 BckGls_RrGlsHtdOpt "Back Glass_Rear Glass Heated Option Signal";
CM_ BO_ 2395189761 "[PE] Periodic and On Event";
CM_ SG_ 2395189761 DATC_Crc10Val "DATC_CyclicRedundancyCheck10Value";
CM_ SG_ 2395189761 DATC_AlvCnt10Val "DATC_AliveCounter10Value";
CM_ SG_ 2395189761 DATC_Typ "DATC_Type";
CM_ SG_ 2395189761 DATC_Opt1Typ "DATC_Option1Type";
CM_ SG_ 2395189761 DATC_Opt3Typ "DATC_Option3Type";
CM_ SG_ 2395189761 DATC_Opt2Typ "DATC_Option2Type";
CM_ SG_ 2395189761 DATC_Opt4Typ "HTR CONTROL OPTION";
CM_ SG_ 2395189761 DATC_StrWhlUSMSta "DATC_SteeringWheelUSMState";
CM_ SG_ 2395189761 DATC_StrWhlHtngReq "DATC_SteeringWheelHeatReq";
CM_ BO_ 2365803009 "[P] Periodic";
CM_ SG_ 2365803009 DATC_Crc16Val "DATC_CyclicRedundancyCheck16Value";
CM_ SG_ 2365803009 DATC_AlvCnt16Val "DATC_AliveCounter16Value";
CM_ SG_ 2365803009 DATC_SwVer1 "this signal indicates DATC Software Version to display on H_U";
CM_ SG_ 2365803009 DATC_SwVer2 "This signal indicates DATC software vertion to display on H_U";
CM_ SG_ 2365803009 DATC_Typ2 "DATC_Type2";
CM_ BO_ 2365803010 "[P] Periodic";
CM_ SG_ 2365803010 DATC_SwVer4 "this signal indicates DATC Detail Software Version";
CM_ SG_ 2365803010 DATC_Typ_All_1 "This signal indicate Climate Control System Type information. (Replace of DATC_Typ/Typ2, DATC_Opt1~5Typ signal)";
CM_ SG_ 2365803010 DATC_Typ_All_2 "This signal indicate Climate Control System Type information  (Replace of DATC_Typ/Typ2, DATC_Opt1~5Typ signal)";
CM_ SG_ 2365803010 DATC_SwVer5 "this signal indicates DATC Detail Software Version";
CM_ BO_ 2365803011 "[P] Periodic";
CM_ SG_ 2365803011 DATC_Typ_All_3 "This signal indicate Climate Control System Type information  (Replace of DATC_Typ/Typ2, DATC_Opt1~5Typ signal)";
CM_ SG_ 2365803011 DATC_Typ_All_4 "This signal indicate Climate Control System Type information. (Replace of DATC_Typ/Typ2, DATC_Opt1~5Typ signal)";
CM_ SG_ 2365803011 DATC_Typ_All_5 "This signal indicate Climate Control System Type information. (Replace of DATC_Typ/Typ2, DATC_Opt1~5Typ signal)";
CM_ SG_ 2365803011 DATC_Typ_All_6 "This signal indicate Climate Control System Type information. (Replace of DATC_Typ/Typ2, DATC_Opt1~5Typ signal)";
CM_ BO_ 2365803012 "[P] Periodic";
CM_ SG_ 2365803012 DATC_Opt_Sys "This signal indicate System Option information for Climate Control. (Replace of DATC_Typ/Typ2, DATC_Opt1~5Typ signal)";
CM_ SG_ 2365803012 DATC_Opt_Func "This signal indicate Function Option for Climate Control. (Replace of DATC_Typ/Typ2, DATC_Opt1~5Typ signal)";
CM_ BO_ 2193667329 "[P] Periodic";
CM_ SG_ 2193667329 EMS_Crc1Val "EMS_CyclicRedundancyCheck1Value";
CM_ SG_ 2193667329 EMS_AlvCnt1Val "EMS_AliveCounter1Value";
CM_ SG_ 2193667329 ENG_CrctEngTqVal "ENG_CorrectedEngineTorqueValue ##2G##EMS - EMS11 - TQI_ACOR";
CM_ SG_ 2193667329 ENG_StndTqRatioVal "ENG_StandardTorqueRatioValue ##2G##EMS - EMS11 - RATIO_TQI_BAS_MAX_STND";
CM_ SG_ 2193667329 ENG_FrctTqVal "ENG_FrictionTorqueValue ##2G##EMS - EMS11 - TQFR";
CM_ BO_ 2193667330 "[P] Periodic";
CM_ SG_ 2193667330 ENG_IndTqVal "ENG_IndicatedTorqueValue ##2G##EMS - EMS11 - TQI";
CM_ SG_ 2193667330 ENG_IndTqBVal "ENG_IndicatedTorqueBValue ##2G##EMS - EMS_H12 - TQI_B";
CM_ SG_ 2193667330 ENG_EngSpdErrSta "ENG_EngineSpeedErrorStatus ##2G##EMS - EMS11 - F_N_ENG";
CM_ SG_ 2193667330 ENG_MafErrSta "ENG_MassAirFlowErrorStatus ##2G##EMS - EMS11 - F_SUB_TQI";
CM_ SG_ 2193667330 ENG_EtcLmphModSta "ENG_EtcLimphomeModeStatus ##2G##EMS - EMS_H12 - CF_Ems_EtcLimpMod";
CM_ SG_ 2193667330 ENG_SpltInjctnSta "ENG_SplitInjectionStatus";
CM_ SG_ 2193667330 ENG_MaxAirconTqVal "ENG_MaximumAirconTorqueValue ##2G##EMS - EMS_H12 - R_TqAcnApvC";
CM_ SG_ 2193667330 ENG_AirconPrsrSnsrVal "ENG_AirconPressureSensorValue ##2G##EMS - EMS_H12 - R_PAcnC";
CM_ SG_ 2193667330 ENG_IsgSta "ENG_IsgStatus ##2G##EMS - EMS_H12 - CF_Ems_IsgStat";
CM_ SG_ 2193667330 ENG_OilLvlSta "ENG_OilLevelStatus ##2G##EMS - EMS_H12 - CF_Ems_OilChg";
CM_ BO_ 2193667331 "[P] Periodic";
CM_ SG_ 2193667331 ENG_TrgtIdleRpmVal "ENG_TargetIdleRpmValue ##2G##EMS - EMS_H12 - R_NEngIdlTgC";
CM_ SG_ 2193667331 ENG_GearShftDnDis "ENG_GearShiftDownDisplay ##2G##EMS - EMS_H12 - CF_Ems_DownTarGr";
CM_ SG_ 2193667331 ENG_DsrGearPosDis "ENG_DesirableGearPositionDisplay ##2G##EMS - EMS_H12 - CF_Ems_DesCurGr";
CM_ SG_ 2193667331 ENG_SldFuncSta "ENG_SpeedLimitFunctionStatus ##2G##EMS - EMS_H12 - CF_Ems_SldAct";
CM_ SG_ 2193667331 ENG_SldActnSta "ENG_SpeedLimitActionStatus ##2G##EMS - EMS_H12 - CF_Ems_SldPosAct";
CM_ SG_ 2193667331 ENG_FuelTnkPrsrSta "ENG_FuelTankPressureStatus ##2G##EMS - EMS_H12 - CF_Ems_HPresStat";
CM_ SG_ 2193667331 ENG_IsgBzrReq "ENG_IsgBuzzerRequest ##2G##EMS - EMS_H12 - CF_Ems_IsgBuz";
CM_ SG_ 2193667331 ENG_IsgFuelCnsmptDis "ENG_IsgFuelConsumptionDisplay ##2G##EMS - EMS_H12 - CF_Ems_IdlStpFCO";
CM_ SG_ 2193667331 ENG_FuelCapOpnSta "ENG_FuelCapOpenStatus ##2G##EMS - EMS_H12 - CF_Ems_FCopen";
CM_ SG_ 2193667331 ENG_EcoDrvActvSta "ENG_EcoDriveActiveStatus ##2G##EMS - EMS_H12 - CF_Ems_ActEcoAct";
CM_ SG_ 2193667331 ENG_EngRunSta "ENG_EngineRunningStatus ##2G##EMS - EMS_H12 - CF_Ems_EngRunNorm";
CM_ SG_ 2193667331 ENG_Isg2Sta "ENG_Isg2Status ##2G##EMS - EMS_H12 - CF_Ems_IsgStat2";
CM_ SG_ 2193667331 ENG_IgnOnSta "ENG_IgnitionOnStatus ##2G##EMS - EMS11 - SWI_IGK";
CM_ SG_ 2193667331 ENG_Ack4TcsSta "ENG_AcknowledgeForTcsStatus ##2G##EMS - EMS11 - ACK_TCS";
CM_ SG_ 2193667331 ENG_FuelCutOffSta "ENG_FuelCutOffStatus ##2G##EMS - EMS11 - PUC_STAT";
CM_ SG_ 2193667331 ENG_CrctTqSta "ENG_CorrectedTorqueStatus ##2G##EMS - EMS11 - TQ_COR_STAT";
CM_ SG_ 2193667331 ENG_AirCompRlySta "ENG_AirCompressorRelayStatus ##2G##EMS - EMS11 - RLY_AC";
CM_ SG_ 2193667331 ENG_LnchCntrlSta "ENG_LaunchControlStatus";
CM_ SG_ 2193667331 ENG_EngSpdVal "ENG_EngineSpeedValue ##2G##EMS - EMS11 - N";
CM_ SG_ 2193667331 ENG_GearShftUpDis "ENG_GearShiftUpDisplay ##2G##EMS - EMS_H12 - CF_Ems_UpTarGr";
CM_ BO_ 2193667332 "[P] Periodic";
CM_ SG_ 2193667332 ENG_TrgtFuelPmpPrsrVal "ENG_TargetFuelPumpPressureValue ##2G##EMS - EMS20 - CF_Ems_PumpTPres";
CM_ SG_ 2193667332 ENG_VehSpdHiVal "ENG_VehicleSpeedHighValue";
CM_ SG_ 2193667332 ENG_EngInhbNCC "This signal indicates the Inhibition of NCC MODE";
CM_ SG_ 2193667332 ENG_SldSwSta "The status of Speed limiter function.";
CM_ SG_ 2193667332 ENG_SldDrvAlertDisp "The status of No Sld Engaged or Sld Disengaged.";
CM_ SG_ 2193667332 ENG_VehSpdLimVal "ENG_VehicleSpeedLimitValue ##2G##EMS - EMS_H12 - SLD_VS, EMS20-SLD_VS_EXT";
CM_ SG_ 2193667332 ENG_FuelCnsmptVal "ENG_FuelConsumptionValue ##2G##EMS - EMS20 - FCO";
CM_ BO_ 2244048129 "[P] Periodic";
CM_ SG_ 2244048129 ESC_Crc3Val "ESC_CyclicRedundancyCheck3Value";
CM_ SG_ 2244048129 ESC_AlvCnt3Val "ESC_AliveCounter3Value";
CM_ SG_ 2244048129 SCC_TqIntrvntnVal "SCC_TorqueInterventionValue ##2G##ESC - TCS13 - TQI_ACC";
CM_ SG_ 2244048129 ESC_VehAccelVal "ESC_VehicleAccelerationValue ##2G##ESC - TCS13 - ACCEL_REF_ACC";
CM_ SG_ 2244048129 ESC_AccelBasisVal "ESC_AccelerationBasisValue ##2G##ESC - TCS13 - aBasis";
CM_ BO_ 2244048130 "[P] Periodic";
CM_ SG_ 2244048130 SCC_OptTyp "SCC_OptionType ##2G##ESC - TCS13 - ACC_EQUIP";
CM_ SG_ 2244048130 ESC_BrkLtReq "ESC_BrakeLightRequest ##2G##ESC - TCS13 - BrakeLight";
CM_ SG_ 2244048130 ESC_DclEnblReq "ESC_DecelerationEnableRequest ##2G##ESC - TCS13 - DCEnable";
CM_ SG_ 2244048130 ESC_DrvOvrdSta "ESC_OverrideRequest ##2G##ESC - TCS13 - DriverOverride";
CM_ SG_ 2244048130 ESC_DrvBrkSta "ESC_DriverBrakingStatus ##2G##ESC - TCS13 - CF_DriBkeStat";
CM_ SG_ 2244048130 SCC_EnblReq "SCC_EnableRequest ##2G##ESC - TCS13 - ACCEnable";
CM_ SG_ 2244048130 ESC_DrvBrkActvSta "ESC_DriverBrakingActiveStatus ##2G##ESC - TCS13 - DriverBraking";
CM_ SG_ 2244048130 ESC_PrkBrkActvSta "ESC_ParkingBrakeActiveStatus ##2G##ESC - TCS13 - PBRAKE_ACT";
CM_ SG_ 2244048130 ESC_HDP_FltMonSta "ESC_HDP_FaultStatus";
CM_ SG_ 2244048130 ESC_HDPSpprtSWVer "IEB/RCU - HDP Support Software Version";
CM_ SG_ 2244048130 FCA_EquipSta "FCA_EquipmentStatus ##2G##ESC - TCS13 - FCA_EQUIP";
CM_ SG_ 2244048130 FCA_AvlblSta "VSM_AvailableStatus ##2G##ESC - TCS13 - CF_VSM_Avail";
CM_ SG_ 2244048130 ESC_FCA_ActvSta "Status of control for FCA control request flag";
CM_ SG_ 2244048130 ESC_DBS_ActvSta "ESC_DBS_ActvSta ##2G## ESC - TCS11 - DBS_ACK";
CM_ SG_ 2244048130 SCC_TqReq "SCC_TorqueRequest ##2G##ESC - TCS13 - ACC_REQ";
CM_ SG_ 2244048130 ESC_HDP_EgSta "ESC_HDP_EngagedStatus";
CM_ SG_ 2244048130 ESC_HDP_EnblReq "ESC_HDP_EnableRequest";
CM_ SG_ 2244048130 ESC_BrkdFltStndstill "Detect Indication of braked, flatland and standstill state";
CM_ SG_ 2244048130 SCC_ReqLimSta "SCC_RequestLimitedStatus ##2G##ESC - TCS13 - ACCReqLim";
CM_ SG_ 2244048130 ESC_StdStillVal "ESC_StandStillValue ##2G##ESC - TCS13 - StandStill";
CM_ BO_ 2244048131 "[P] Periodic";
CM_ SG_ 2244048131 ESC_RccaSta "ESC_RccaStatus ##2G##ESC - ESP11 - ESP_RCCA_STAT";
CM_ SG_ 2244048131 ESC_RspaCanFlFlag "##2G##ESC - ESP11 - ESC_RspaCanfailflag";
CM_ SG_ 2244048131 ESC_RspaDclActv "##2G##ESC - ESP11 - ESC_RSPA_DEC_ACT";
CM_ SG_ 2244048131 ESC_RspaStandStill "##2G##ESC - ESP11 - ESC_RSPA_STANDSTILL";
CM_ SG_ 2244048131 ESC_PcaSta "ESC_PcaStatus";
CM_ SG_ 2244048131 ESC_LdOpn "This signal indicates the command for eLD lock/unlock mode.";
CM_ SG_ 2244048131 MCB_ReqBrkAck "Acknowledge Status for MCB Brake Request";
CM_ SG_ 2244048131 MCB_CtlSta "Status for MCB Activation";
CM_ SG_ 2244048131 MCB_DefSta "Status for MCB defect";
CM_ SG_ 2244048131 ESC_DiffBrkFuncSta "ESC_DifferentialBrakeFunctionStatus ##2G##ESC - TCS13 - DF_BF_STAT";
CM_ SG_ 2244048131 ESC_LsdLimMod "eLSD torque limit mode ##2G##ESC - ESP_LSD11 - LSD_LIM_MODE";
CM_ SG_ 2244048131 ESC_LsdOpn "eLSD clutch open mode ##2G##ESC - ESP_LSD11 - LSD_OPEN";
CM_ SG_ 2244048131 ESC_LsdTqLim "value of the torquel limit of eLSD ##2G##ESC - ESP_LSD11 - LSD_TQC_LIM";
CM_ SG_ 2244048131 ESC_BcaRPlusSta "ESC_BcaRPlusStatus";
CM_ SG_ 2244048131 ESC_RspaSta "ESC_RspaStatus ##2G##ESC - ESP11 - ESP_RSPA_STAT";
CM_ BO_ 1189 "[PE] Periodic and On Event";
CM_ SG_ 1189 C_RLTiltUpSw_HU "2nd Left side seat Moving control : Tilt Up";
CM_ SG_ 1189 C_RRTiltDownSw_HU "2nd Right side seat Moving control : Tilt Down";
CM_ SG_ 1189 C_RRTiltUpSw_HU "2nd Right side seat Moving control : Tilt Up";
CM_ SG_ 1189 C_RLRclBwdSw_HU "2nd Left side seat Moving control :Recline Backward";
CM_ SG_ 1189 C_RLRclFwdSw_HU "2nd Left side seat Moving control : Recline Forward";
CM_ SG_ 1189 C_RLFldSw_HU "2nd Left side seat folding control : Folding";
CM_ SG_ 1189 C_RRRclBwdSw_HU "2nd Right side seat Moving control :Recline Backward";
CM_ SG_ 1189 C_RRRclFwdSw_HU "2nd Right side seat Moving control :Recline Forward";
CM_ SG_ 1189 C_TLHrestFldSw_HU "3rdLeft side seat Headrest folding control : Folding";
CM_ SG_ 1189 C_TRHrestFldSw_HU "3rd Right side seat Headrest folding control : Folding";
CM_ SG_ 1189 C_TLFldSw_HU "3rd Left side seat folding control : Folding";
CM_ SG_ 1189 C_TRFldSw_HU "3rd Right side seat folding control : Folding";
CM_ SG_ 1189 C_RRFldSw_HU "2nd Right side seat folding control : Folding";
CM_ SG_ 1189 C_RLTiltDownSw_HU "2nd Left side seat Moving control : Tilt Down";
CM_ BO_ 1185 "[EC] On Event and On Change";
CM_ SG_ 1185 C_AstWindowCmdAVN "This signal indicates AST Window Open/Close Command";
CM_ SG_ 1185 C_RrDefoggerCmdAVN "This signal indicates Rear Defogger Button Command";
CM_ SG_ 1185 C_RRWindowCmdAVN "This signal indicates RR Window Open/Close Command";
CM_ SG_ 1185 C_RLWindowCmdAVN "This signal indicates RL Window Open/Close Command";
CM_ SG_ 1185 C_BlindCmdAVN "This signal indicates Sunroof Blind Open/Close Command";
CM_ SG_ 1185 C_GlassCmdAVN "This signal indicates Sunroof Glass Open/Close Command";
CM_ SG_ 1185 C_DrvWindowCmdAVN "This signal indicates DRV Window Open/Close Command";
CM_ SG_ 1185 C_PTGCNTLCmdAVN "This signal indicates PowerTailgate Open/Close  Command";
CM_ BO_ 1193 "[EC] On Event and On Change";
CM_ SG_ 1193 C_PTGMNValueSet "Request to set PTGM Mode";
CM_ SG_ 1193 CF_AVN_PSMNValueSet "This signal is used for a request to set the value of UMS Menus. This signal requests to set Seat Easy Access Mode. When this signal change, the message is sent 3 times.";
CM_ SG_ 1193 C_HfreeTrunkTgNValueSet "Request to set Smart Trunk/Tailgate Mode";
CM_ SG_ 1193 CF_AVN_TrfChgSet "This signal is used for a request to set the value of UMS Menus. This signal requests to set Traffic Change Mode. When this signal change, the message is sent 3 times.";
CM_ SG_ 1193 CF_AVN_SCMNValueSet "Request to set Steering Easy Access mode";
CM_ SG_ 1193 CF_AVN_ADrUNValueSet "Request to set Auto Door Unlock Mode";
CM_ SG_ 1193 CF_AVN_OTTurnNValueSet "This signal is used for a request current setting value of USM Menus. When this signal change, the message is sent 3 times.";
CM_ SG_ 1193 CF_Gway_WPCNValueSet "Request to set Wireless Phone Charging mode";
CM_ SG_ 1193 C_AVN_RearWiperNValueSet "Request to set Rear Wiper operation in reverse";
CM_ SG_ 1193 C_UnlockWelocomeNValueSet "Request to set Door Unlock Welcome Setting Option";
CM_ SG_ 1193 C_SmartWelocomeNValueSet "Request to set Smart Key Welcome Setting Option";
CM_ SG_ 1193 CF_AVN_PTGSpeedNValueSet "Setting Value For Power Tailgate Speed";
CM_ SG_ 1193 CR_Datc_DRSeatWheel_USM_Set "SteeringWheel USM Set";
CM_ SG_ 1193 CF_AVN_TTUnlockNValueSet "Setting Value for Two Turn Unlock";
CM_ SG_ 1193 CF_Gway_RWPCNValueSet "Rear Wireless Phone Charger ON/OFF Request";
CM_ SG_ 1193 CF_Avn_HAPTICWARNINGNValueSet "USM request for Steering Wheel Haptic Warning";
CM_ SG_ 1193 CR_Datc_DRSeatHeat_USM_Set "Driver Seat Heat/Ventl USM Set";
CM_ SG_ 1193 C_WALNValueSet "USM Function for Walk Away Lock(WAL)";
CM_ SG_ 1193 C_ApprUnlockNValue "USM request for Approach Unlock";
CM_ SG_ 1193 CF_AVN_EscortHLNValueSet "Request to set Head Lamp Escort Option";
CM_ BO_ 1195 "[EC] On Event and On Change";
CM_ SG_ 1195 CF_AVN_CluWelcomeSnd "Request to set CLU welcome soun";
CM_ SG_ 1195 CF_AVN_CluTransmissionDisp "Request to set CLU transmission display";
CM_ SG_ 1195 CF_AVN_CluWiperLight "Request to set CLU wiper & light mode";
CM_ SG_ 1195 CF_AVN_CluRoadInfoGuide "Request to set CLU road info guidance";
CM_ SG_ 1195 CF_AVN_CluUserSettingPeriod "Request to set CLU sservice period set by user";
CM_ SG_ 1195 CF_AVN_CluFuelEconUnit_mi "Cluster setting status for cluster Fuel Economy Unit (mile)";
CM_ SG_ 1195 CF_AVN_CluFuelEconUnit_km "Cluster setting status for cluster Fuel Economy unit (km)";
CM_ SG_ 1195 CF_AVN_CluUserSettingDistance "Request to set CLU service distance set by user";
CM_ SG_ 1195 CF_AVN_CluRheostatLvl "Request to set CLU rheostat level";
CM_ SG_ 1195 CF_AVN_EVReset "Request to reset EV Service (0x1 : EV USM Reset)";
CM_ SG_ 1195 CF_AVN_UnitReset "Request to reset Unit setting";
CM_ SG_ 1195 CF_AVN_IcyRoadWarn "Request to set CLU icy road warning";
CM_ SG_ 1195 CF_AVN_CluServiceReminderReset "Request to reset CLU service reminder";
CM_ SG_ 1195 CF_AVN_CluUSMReset "Request to reset all USM service";
CM_ SG_ 1195 CF_AVN_CluServiceReminderSet "Request to set CLU service notification";
CM_ BO_ 1196 "[EC] On Event and On Change";
CM_ SG_ 1196 C_HCIMSWeightNValueSet "This signal is used for Healthcare IMS to input user's weight";
CM_ SG_ 1196 C_HCIMSSitHeightNValueSet "This signal is used for Healthcare IMS to input user's sitting height";
CM_ SG_ 1196 CF_AVN_BodySpprtSet "This signal is for the seat body support USM";
CM_ SG_ 1196 CF_AVN_AirSptTimeNValueSet "This signal is for the seat massage function time setting";
CM_ SG_ 1196 CF_AVN_AirSptStrNValue "This signal is for the seat massage intensity USM";
CM_ SG_ 1196 CF_AVN_SeatDrvModNValueSet "This signal is for the auto seat-drivemode user setting menu";
CM_ SG_ 1196 C_HCIMSHeightNvalueSet "This signal is used for Healthcare IMS to input user's height";
CM_ SG_ 1196 CF_AVN_HCIMSButtonCommand "User's input value in healthcare IMS mode";
CM_ BO_ 2164277252 "[P] Periodic";
CM_ SG_ 2164277252 TCU_NetrlCtrlSta "TCU_NeutralControlStatus";
CM_ SG_ 2164277252 TCU_ShftPtrnSta "TCU_ShiftPatternStatus";
CM_ SG_ 2164277252 TCU_EPBReq "EPB Request signal for prevent P-D Shock on hill";
CM_ SG_ 2164277252 IMT_EOLstate "Gear Display for EOL mode to cluster. This signal is for IMT system only.";
CM_ SG_ 2164277252 IMT_DisCmd "Gear Display type command to cluster . this signal is for IMT system only.";
CM_ SG_ 2164277252 IMT_CltchPdlPos "Clutch Pedal Position. This signal is for IMT system only.";
CM_ SG_ 2164277252 DCT_RegenInhbt "The regen inhibit request from TCU";
CM_ SG_ 2164277252 DCT_EngIdleReq "Engine Idle Request";
CM_ SG_ 2164277252 DCT_CltchState "DCT clutch status";
CM_ SG_ 2164277252 DCT_FuelCutReq "TCU require ECU to perform ¡®Fuel Cut¡¯";
CM_ SG_ 2164277252 DCT_TqIncReq "Request for Torque Increase";
CM_ SG_ 2164277252 DCT_CrpTqReq "Pre-control torque for creeping";
CM_ SG_ 2164277252 DCT_ShftTqReq "Pre-control torque for shifting";
CM_ SG_ 2164277252 TCU_VgisInhbtReq "TCU_VgisInhibitionRequest";
CM_ SG_ 2164277252 TCU_EngTqIncReqVal "TCU_EngineTorqueIncreaseReqValue";
CM_ BO_ 2189467649 "[P] Periodic";
CM_ SG_ 2189467649 WHL_Crc1Val "WHL_CyclicRedundancyCheck1Value";
CM_ SG_ 2189467649 WHL_AlvCnt1Val "WHL_AliveCounter1Value";
CM_ SG_ 2189467649 WHL_PlsFLVal "WHL_PulseFrontLeftValue ##2G##ESC - WHL_PUL11 - WHL_PUL_FL";
CM_ SG_ 2189467649 WHL_PlsFRVal "WHL_PulseFrontRightValue ##2G##ESC - WHL_PUL11 - WHL_PUL_FR";
CM_ SG_ 2189467649 WHL_PlsRLVal "WHL_PulseRearLeftValue ##2G##ESC - WHL_PUL11 - WHL_PUL_RL";
CM_ SG_ 2189467649 WHL_PlsRRVal "WHL_PulseRearRightValue ##2G##ESC - WHL_PUL11 - WHL_PUL_RR";
CM_ SG_ 2189467649 WHL_DirFLVal "WHL_DirectionFrontLeftValue ##2G##ESC - WHL_PUL11 - WHL_DIR_FL";
CM_ SG_ 2189467649 WHL_DirFRVal "WHL_DirectionFrontRightValue ##2G##ESC - WHL_PUL11 - WHL_DIR_FR";
CM_ SG_ 2189467649 WHL_DirRLVal "WHL_DirectionRearLeftValue ##2G##ESC - WHL_PUL11 - WHL_DIR_RL";
CM_ SG_ 2189467649 WHL_DirRRVal "WHL_DirectionRearRightValue ##2G##ESC - WHL_PUL11 - WHL_DIR_RR";
CM_ BO_ 2189467650 "[P] Periodic";
CM_ SG_ 2189467650 WHL_SpdFLVal "WHL_SpeedFrontLeftValue ##2G##ESC - WHL_SPD11 - WHL_SPD_FL";
CM_ SG_ 2189467650 WHL_SpdFRVal "WHL_SpeedFrontRightValue ##2G##ESC - WHL_SPD11 - WHL_SPD_FR";
CM_ SG_ 2189467650 WHL_SpdRLVal "WHL_SpeedRearLeftValue ##2G##ESC - WHL_SPD11 - WHL_SPD_RL";
CM_ SG_ 2189467650 WHL_SpdRRVal "WHL_SpeedRearRightValue ##2G##ESC - WHL_SPD11 - WHL_SPD_RR";
CM_ BO_ 2189467651 "[P] Periodic";
CM_ SG_ 2189467651 WHL_SpdCalParmtr "WHL_SpeedCalculationParameter";
BA_DEF_ BO_ "DiagState" ENUM "No","Yes" ;
BA_DEF_ BO_ "DiagResponse" ENUM "No","Yes" ;
BA_DEF_ BO_ "DiagRequest" ENUM "No","Yes" ;
BA_DEF_ BO_ "TpMessage" ENUM "No","Yes" ;
BA_DEF_ BO_ "UsrMsgIDSforwardDeviation" INT 0 100 ;
BA_DEF_ BO_ "UsrMsgIDSbackwardDeviation" INT 50 1000 ;
BA_DEF_ BO_ "GenMsgCycleTime" INT 0 2000 ;
BA_DEF_ BO_ "GenMsgStartDelayTime" INT 0 2000 ;
BA_DEF_ BO_ "GenMsgSendType" ENUM "Cyclic","NoMsgSendType" ;
BA_DEF_ BO_ "GenMsgCycleTimeFast" INT 0 500 ;
BA_DEF_ BO_ "GenMsgDelayTime" INT 0 20 ;
BA_DEF_ BO_ "GenMsgILSupport" ENUM "No","Yes" ;
BA_DEF_ BO_ "GenMsgNrOfRepetition" INT 0 3 ;
BA_DEF_ BO_ "NmMessage" ENUM "No","Yes" ;
BA_DEF_ BO_ "NWM-Botschaft" ENUM "No","Yes" ;
BA_DEF_ BO_ "TpTxIndex" INT 0 65535 ;
BA_DEF_ BO_ "VFrameFormat" ENUM "StandardCAN","ExtendedCAN","reserved","reserved","reserved","reserved","reserved","reserved","reserved","reserved","reserved","reserved","reserved","reserved","StandardCAN_FD","ExtendedCAN_FD" ;
BA_DEF_ SG_ "UserSigValidity" ENUM "B+","ACC","IG","IG1","IG2","IG3","IG1 or IG2","IG1 or IG3","Undef" ;
BA_DEF_ SG_ "TimeoutValue" STRING ;
BA_DEF_ SG_ "UsrSigPurpose" ENUM "Undef","FN","DIAG","DIAG(Req)","DIAG(Res)","DIAG(Phy)","DEV","CCP(Req)","CCP(Res)","NM","TP" ;
BA_DEF_ SG_ "GenSigStartValue" INT 0 1215752192 ;
BA_DEF_ SG_ "NetworkRequest" ENUM "Yes","No" ;
BA_DEF_ SG_ "NetworkRequestHoldingTime" INT 0 65535 ;
BA_DEF_ SG_ "Description" STRING ;
BA_DEF_ SG_ "Version" STRING ;
BA_DEF_ SG_ "GenSigEnvVarType" ENUM "Int","Float","Undef" ;
BA_DEF_ SG_ "GenSigSendType" ENUM "Cyclic","OnWrite","OnWriteWithRepetition","OnChange","OnChangeWithRepetition","IfActive","IfActiveWithRepetition","NoSigSendType","OnChangeAndIfActive","OnChangeAndIfActiveWithRepetition" ;
BA_DEF_ SG_ "GwSigLatencyTime" INT 0 65536 ;
BA_DEF_ SG_ "GwSigMissingSourceType" ENUM "Undef","OldValue","DefaultValue","InitialValue" ;
BA_DEF_ SG_ "NWM-WakeupAllowed" ENUM "<n.a.>" ;
BA_DEF_ SG_ "RoutingFactor" INT 1 1215752192 ;
BA_DEF_REL_ BU_SG_REL_ "GenSigTimeoutTime" INT 0 7000 ;
BA_DEF_DEF_ "DiagState" "No" ;
BA_DEF_DEF_ "DiagResponse" "No" ;
BA_DEF_DEF_ "DiagRequest" "No" ;
BA_DEF_DEF_ "TpMessage" "No" ;
BA_DEF_DEF_ "UsrMsgIDSforwardDeviation" 10 ;
BA_DEF_DEF_ "UsrMsgIDSbackwardDeviation" 100 ;
BA_DEF_DEF_ "GenMsgCycleTime" 200 ;
BA_DEF_DEF_ "GenMsgStartDelayTime" 0 ;
BA_DEF_DEF_ "GenMsgSendType" "NoMsgSendType" ;
BA_DEF_DEF_ "GenMsgCycleTimeFast" 40 ;
BA_DEF_DEF_ "GenMsgDelayTime" 20 ;
BA_DEF_DEF_ "GenMsgILSupport" "Yes" ;
BA_DEF_DEF_ "GenMsgNrOfRepetition" 3 ;
BA_DEF_DEF_ "NmMessage" "No" ;
BA_DEF_DEF_ "NWM-Botschaft" "No" ;
BA_DEF_DEF_ "TpTxIndex" 0 ;
BA_DEF_DEF_ "VFrameFormat" "StandardCAN" ;
BA_DEF_DEF_ "UserSigValidity" "IG" ;
BA_DEF_DEF_ "TimeoutValue" "" ;
BA_DEF_DEF_ "UsrSigPurpose" "FN" ;
BA_DEF_DEF_ "GenSigStartValue" 0 ;
BA_DEF_DEF_ "NetworkRequest" "No" ;
BA_DEF_DEF_ "NetworkRequestHoldingTime" 0 ;
BA_DEF_DEF_ "Description" "" ;
BA_DEF_DEF_ "Version" "" ;
BA_DEF_DEF_ "GenSigEnvVarType" "Undef" ;
BA_DEF_DEF_ "GenSigSendType" "NoSigSendType" ;
BA_DEF_DEF_ "GwSigLatencyTime" 40 ;
BA_DEF_DEF_ "GwSigMissingSourceType" "Undef" ;
BA_DEF_DEF_ "NWM-WakeupAllowed" "<n.a.>" ;
BA_DEF_DEF_ "RoutingFactor" 1 ;
BA_DEF_DEF_REL_ "GenSigTimeoutTime" 500 ;
BA_ "GenMsgSendType" BO_ 2328015105 0;
BA_ "GenMsgCycleTimeFast" BO_ 2328015105 0;
BA_ "GenMsgNrOfRepetition" BO_ 2328015105 0;
BA_ "VFrameFormat" BO_ 2328015105 1;
BA_ "Description" SG_ 2328015105 ADAS_CMD_Crc34Val "The data area for CRC calculation is based on the data length (DLC) of the message DB.

The CRC shall be calculated over the entire data block (excluding the CRC bytes) including the user data, alive counter and Data ID



- CRC Polynomial (0x1021) , Initial Value : 0xFFFF, XOR value : 0x0000, Data ID : Message ID + 0xF800 

- The initial value is for CRC calculation and the message should be sent with the calculated result value. 

- The mathematical expression to 16 bit CRC polynomial is given here. G(x) = x16 + x12 + x5 + 1



<For CRC calculation of CAN-FD Msg for HS CAN domain ECUs>



- HS-CAN Messages that routed from CAN-FD domain are using 29 bit Extended CAN ID and splitted into 8 Byte Messages.

(from 1 to 4 Msgs, depending on source CAN-FD Msg¡¯s DLC)

- For splitted CAN-FD Msgs¡¯ CRC calculation, HS CAN ECUs should use source CAN-FD Msg¡¯s original STD ID. 

- The original STD ID can be read from Ext ID¡¯s 4~6th Byte.

Eg. STD 0x6AA : EXT SPLT 0x1A8[6AA]01 / 0x1A8[6AA]02 / 0x1A8[6AA]03 / 0x1A8[6AA]04 

(2~4th splitited Msgs can be omitted depending on source CAN-FD Msg¡¯s DLC)

- Aslo, HS-CAN ECUs should use merged data block (from whole splitted Msg) for CRC calculation.";
BA_ "GenSigStartValue" SG_ 2328015105 ADAS_CMD_Crc34Val 65535;
BA_ "UserSigValidity" SG_ 2328015105 ADAS_CMD_Crc34Val 3;
BA_ "RoutingFactor" SG_ 2328015105 ADAS_CMD_Crc34Val 2;
BA_ "Version" SG_ 2328015105 ADAS_CMD_Crc34Val "21.09.03";
BA_ "Description" SG_ 2328015105 ADAS_CMD_AlvCnt34Val "For the first transmission request for a data element the counter shall be initialized with 0 and shall be incremented by 1 for every subsequent send request. 

When the counter reaches the maximum value(0xFF), then it shall restart with 0 for the next send request";
BA_ "UserSigValidity" SG_ 2328015105 ADAS_CMD_AlvCnt34Val 3;
BA_ "RoutingFactor" SG_ 2328015105 ADAS_CMD_AlvCnt34Val 2;
BA_ "Version" SG_ 2328015105 ADAS_CMD_AlvCnt34Val "21.09.03";
BA_ "Description" SG_ 2328015105 HDP_RDD_WarnSta "Request CLU to activate the corresponding warning device(s) according to the HDP redundancy MRM warning level.";
BA_ "UserSigValidity" SG_ 2328015105 HDP_RDD_WarnSta 0;
BA_REL_ "GenSigTimeoutTime" BU_SG_REL_ HOD SG_ 2328015105 HDP_RDD_WarnSta 1500;
BA_REL_ "GenSigTimeoutTime" BU_SG_REL_ PSB SG_ 2328015105 HDP_RDD_WarnSta 1500;
BA_ "RoutingFactor" SG_ 2328015105 HDP_RDD_WarnSta 2;
BA_ "Version" SG_ 2328015105 HDP_RDD_WarnSta "22.05.00";
BA_ "Description" SG_ 2328015105 HDP_RDD_HzrdLmpReqSta "This signal indicates the requestion of the hazard lamp lightning from FR_CMR.";
BA_ "UserSigValidity" SG_ 2328015105 HDP_RDD_HzrdLmpReqSta 3;
BA_ "RoutingFactor" SG_ 2328015105 HDP_RDD_HzrdLmpReqSta 2;
BA_ "Version" SG_ 2328015105 HDP_RDD_HzrdLmpReqSta "21.04.02";
BA_ "Description" SG_ 2328015105 HDP_RDD_ACIActvDispSta "State for angle control";
BA_ "UserSigValidity" SG_ 2328015105 HDP_RDD_ACIActvDispSta 3;
BA_ "RoutingFactor" SG_ 2328015105 HDP_RDD_ACIActvDispSta 2;
BA_ "Version" SG_ 2328015105 HDP_RDD_ACIActvDispSta "21.04.00";
BA_ "GenMsgSendType" BO_ 2328015106 0;
BA_ "GenMsgCycleTimeFast" BO_ 2328015106 0;
BA_ "GenMsgNrOfRepetition" BO_ 2328015106 0;
BA_ "VFrameFormat" BO_ 2328015106 1;
BA_ "Description" SG_ 2328015106 HDP_RDD_EMStbltActvReqSta "Depending on the driving situation, EM tells PSB to release(no alert), retract or pull the seat belt for occupant protection or warning.";
BA_ "UserSigValidity" SG_ 2328015106 HDP_RDD_EMStbltActvReqSta 3;
BA_REL_ "GenSigTimeoutTime" BU_SG_REL_ PSB SG_ 2328015106 HDP_RDD_EMStbltActvReqSta 1500;
BA_ "RoutingFactor" SG_ 2328015106 HDP_RDD_EMStbltActvReqSta 2;
BA_ "Version" SG_ 2328015106 HDP_RDD_EMStbltActvReqSta "21.04.00";
BA_ "GenMsgSendType" BO_ 2328015107 0;
BA_ "GenMsgCycleTimeFast" BO_ 2328015107 0;
BA_ "GenMsgNrOfRepetition" BO_ 2328015107 0;
BA_ "VFrameFormat" BO_ 2328015107 1;
BA_ "GenMsgSendType" BO_ 2328015108 0;
BA_ "GenMsgCycleTimeFast" BO_ 2328015108 0;
BA_ "GenMsgNrOfRepetition" BO_ 2328015108 0;
BA_ "VFrameFormat" BO_ 2328015108 1;
BA_ "GenMsgSendType" BO_ 287 0;
BA_ "Description" SG_ 287 APSS_LumbarUpSw "APSS_LumbarUpMoveSwitch";
BA_ "GenSigSendType" SG_ 287 APSS_LumbarUpSw 4;
BA_ "UserSigValidity" SG_ 287 APSS_LumbarUpSw 0;
BA_REL_ "GenSigTimeoutTime" BU_SG_REL_ ALBCU SG_ 287 APSS_LumbarUpSw 1500;
BA_REL_ "GenSigTimeoutTime" BU_SG_REL_ CGW_CCU SG_ 287 APSS_LumbarUpSw 1500;
BA_ "NetworkRequest" SG_ 287 APSS_LumbarUpSw 0;
BA_ "NetworkRequestHoldingTime" SG_ 287 APSS_LumbarUpSw 5000;
BA_ "Version" SG_ 287 APSS_LumbarUpSw "19.11.06";
BA_ "Description" SG_ 287 APSS_LumbarMidSw "APSS_LumbarMiddleSwitch";
BA_ "GenSigSendType" SG_ 287 APSS_LumbarMidSw 4;
BA_ "UserSigValidity" SG_ 287 APSS_LumbarMidSw 0;
BA_REL_ "GenSigTimeoutTime" BU_SG_REL_ ALBCU SG_ 287 APSS_LumbarMidSw 1500;
BA_REL_ "GenSigTimeoutTime" BU_SG_REL_ CGW_CCU SG_ 287 APSS_LumbarMidSw 1500;
BA_ "NetworkRequest" SG_ 287 APSS_LumbarMidSw 0;
BA_ "NetworkRequestHoldingTime" SG_ 287 APSS_LumbarMidSw 5000;
BA_ "Version" SG_ 287 APSS_LumbarMidSw "19.11.06";
BA_ "Description" SG_ 287 APSS_LumbarLowSw "APSS_LumbarLowerSwitch";
BA_ "GenSigSendType" SG_ 287 APSS_LumbarLowSw 4;
BA_ "UserSigValidity" SG_ 287 APSS_LumbarLowSw 0;
BA_REL_ "GenSigTimeoutTime" BU_SG_REL_ ALBCU SG_ 287 APSS_LumbarLowSw 1500;
BA_REL_ "GenSigTimeoutTime" BU_SG_REL_ CGW_CCU SG_ 287 APSS_LumbarLowSw 1500;
BA_ "NetworkRequest" SG_ 287 APSS_LumbarLowSw 0;
BA_ "NetworkRequestHoldingTime" SG_ 287 APSS_LumbarLowSw 5000;
BA_ "Version" SG_ 287 APSS_LumbarLowSw "19.11.06";
BA_ "Description" SG_ 287 APSS_LumbarDefSw "APSS_LumbarDeflationSwitch";
BA_ "GenSigSendType" SG_ 287 APSS_LumbarDefSw 4;
BA_ "UserSigValidity" SG_ 287 APSS_LumbarDefSw 0;
BA_REL_ "GenSigTimeoutTime" BU_SG_REL_ ALBCU SG_ 287 APSS_LumbarDefSw 1500;
BA_REL_ "GenSigTimeoutTime" BU_SG_REL_ CGW_CCU SG_ 287 APSS_LumbarDefSw 1500;
BA_ "NetworkRequest" SG_ 287 APSS_LumbarDefSw 0;
BA_ "NetworkRequestHoldingTime" SG_ 287 APSS_LumbarDefSw 5000;
BA_ "Version" SG_ 287 APSS_LumbarDefSw "19.11.06";
BA_ "Description" SG_ 287 APSS_BolsterInfSw "APSS_BolsterInflationSwitch";
BA_ "GenSigSendType" SG_ 287 APSS_BolsterInfSw 4;
BA_ "UserSigValidity" SG_ 287 APSS_BolsterInfSw 0;
BA_REL_ "GenSigTimeoutTime" BU_SG_REL_ ALBCU SG_ 287 APSS_BolsterInfSw 1500;
BA_REL_ "GenSigTimeoutTime" BU_SG_REL_ CGW_CCU SG_ 287 APSS_BolsterInfSw 1500;
BA_ "NetworkRequest" SG_ 287 APSS_BolsterInfSw 0;
BA_ "NetworkRequestHoldingTime" SG_ 287 APSS_BolsterInfSw 5000;
BA_ "Version" SG_ 287 APSS_BolsterInfSw "19.11.06";
BA_ "Description" SG_ 287 APSS_BolsterDefSw "APSS_BolsterDeflationSwitch";
BA_ "GenSigSendType" SG_ 287 APSS_BolsterDefSw 4;
BA_ "UserSigValidity" SG_ 287 APSS_BolsterDefSw 0;
BA_REL_ "GenSigTimeoutTime" BU_SG_REL_ ALBCU SG_ 287 APSS_BolsterDefSw 1500;
BA_REL_ "GenSigTimeoutTime" BU_SG_REL_ CGW_CCU SG_ 287 APSS_BolsterDefSw 1500;
BA_ "NetworkRequest" SG_ 287 APSS_BolsterDefSw 0;
BA_ "NetworkRequestHoldingTime" SG_ 287 APSS_BolsterDefSw 5000;
BA_ "Version" SG_ 287 APSS_BolsterDefSw "19.11.06";
BA_ "Description" SG_ 287 APSS_ActiveSw "Passenger seat cushion bolster adjustment switch";
BA_ "GenSigSendType" SG_ 287 APSS_ActiveSw 4;
BA_ "UserSigValidity" SG_ 287 APSS_ActiveSw 0;
BA_REL_ "GenSigTimeoutTime" BU_SG_REL_ ALBCU SG_ 287 APSS_ActiveSw 1500;
BA_ "NetworkRequest" SG_ 287 APSS_ActiveSw 0;
BA_ "NetworkRequestHoldingTime" SG_ 287 APSS_ActiveSw 5000;
BA_ "Version" SG_ 287 APSS_ActiveSw "23.01.00";
BA_ "Description" SG_ 287 APSS_CushInfSw "Passenger seat cushion air cell inflation switch";
BA_ "GenSigSendType" SG_ 287 APSS_CushInfSw 4;
BA_ "UserSigValidity" SG_ 287 APSS_CushInfSw 0;
BA_REL_ "GenSigTimeoutTime" BU_SG_REL_ ALBCU SG_ 287 APSS_CushInfSw 1500;
BA_ "NetworkRequest" SG_ 287 APSS_CushInfSw 0;
BA_ "NetworkRequestHoldingTime" SG_ 287 APSS_CushInfSw 5000;
BA_ "Version" SG_ 287 APSS_CushInfSw "23.01.00";
BA_ "Description" SG_ 287 APSS_CushDefSw "Passenger seat cushion air cell deflation switch";
BA_ "GenSigSendType" SG_ 287 APSS_CushDefSw 4;
BA_ "UserSigValidity" SG_ 287 APSS_CushDefSw 0;
BA_REL_ "GenSigTimeoutTime" BU_SG_REL_ ALBCU SG_ 287 APSS_CushDefSw 1500;
BA_ "NetworkRequest" SG_ 287 APSS_CushDefSw 0;
BA_ "NetworkRequestHoldingTime" SG_ 287 APSS_CushDefSw 5000;
BA_ "Version" SG_ 287 APSS_CushDefSw "23.01.00";
BA_ "GenMsgCycleTime" BO_ 273 0;
BA_ "Description" SG_ 273 ARS_RrCurtainBtn "Rear Curtain Button";
BA_ "GenSigSendType" SG_ 273 ARS_RrCurtainBtn 4;
BA_ "UserSigValidity" SG_ 273 ARS_RrCurtainBtn 3;
BA_ "NetworkRequest" SG_ 273 ARS_RrCurtainBtn 0;
BA_ "NetworkRequestHoldingTime" SG_ 273 ARS_RrCurtainBtn 5000;
BA_ "Version" SG_ 273 ARS_RrCurtainBtn "22.02.05";
BA_ "GenMsgSendType" BO_ 271 0;
BA_ "Description" SG_ 271 ASAU_AirSptTimeRValueSet "Air Support Time(Massage Time) USM R Value";
BA_ "GenSigSendType" SG_ 271 ASAU_AirSptTimeRValueSet 4;
BA_ "UserSigValidity" SG_ 271 ASAU_AirSptTimeRValueSet 3;
BA_REL_ "GenSigTimeoutTime" BU_SG_REL_ CGW_CCU SG_ 271 ASAU_AirSptTimeRValueSet 1500;
BA_ "NetworkRequest" SG_ 271 ASAU_AirSptTimeRValueSet 0;
BA_ "NetworkRequestHoldingTime" SG_ 271 ASAU_AirSptTimeRValueSet 5000;
BA_ "Version" SG_ 271 ASAU_AirSptTimeRValueSet "19.11.06";
BA_ "Description" SG_ 271 ASAU_AstSmtAirSptRValueSet "Seat Smart Air Support Function USM R Value";
BA_ "GenSigSendType" SG_ 271 ASAU_AstSmtAirSptRValueSet 4;
BA_ "UserSigValidity" SG_ 271 ASAU_AstSmtAirSptRValueSet 3;
BA_REL_ "GenSigTimeoutTime" BU_SG_REL_ CGW_CCU SG_ 271 ASAU_AstSmtAirSptRValueSet 1500;
BA_ "NetworkRequest" SG_ 271 ASAU_AstSmtAirSptRValueSet 0;
BA_ "NetworkRequestHoldingTime" SG_ 271 ASAU_AstSmtAirSptRValueSet 5000;
BA_ "Version" SG_ 271 ASAU_AstSmtAirSptRValueSet "19.12.00";
BA_ "Description" SG_ 271 ASAU_CushSoftRValueSet "Cushion Soft R Value";
BA_ "GenSigSendType" SG_ 271 ASAU_CushSoftRValueSet 4;
BA_ "UserSigValidity" SG_ 271 ASAU_CushSoftRValueSet 3;
BA_REL_ "GenSigTimeoutTime" BU_SG_REL_ CGW_CCU SG_ 271 ASAU_CushSoftRValueSet 1500;
BA_ "NetworkRequest" SG_ 271 ASAU_CushSoftRValueSet 0;
BA_ "NetworkRequestHoldingTime" SG_ 271 ASAU_CushSoftRValueSet 5000;
BA_ "Version" SG_ 271 ASAU_CushSoftRValueSet "20.04.02";
BA_ "Description" SG_ 271 ASAU_BackSoftRValueSet "Back Soft USM R Value";
BA_ "GenSigSendType" SG_ 271 ASAU_BackSoftRValueSet 4;
BA_ "UserSigValidity" SG_ 271 ASAU_BackSoftRValueSet 3;
BA_ "NetworkRequest" SG_ 271 ASAU_BackSoftRValueSet 0;
BA_ "NetworkRequestHoldingTime" SG_ 271 ASAU_BackSoftRValueSet 5000;
BA_ "Version" SG_ 271 ASAU_BackSoftRValueSet "20.04.02";
BA_ "Description" SG_ 271 ASAU_AirSptModeRValueSet "Air Support Mode(Massage Mode) USM R Value";
BA_ "GenSigSendType" SG_ 271 ASAU_AirSptModeRValueSet 4;
BA_ "UserSigValidity" SG_ 271 ASAU_AirSptModeRValueSet 3;
BA_REL_ "GenSigTimeoutTime" BU_SG_REL_ CGW_CCU SG_ 271 ASAU_AirSptModeRValueSet 1500;
BA_ "NetworkRequest" SG_ 271 ASAU_AirSptModeRValueSet 0;
BA_ "NetworkRequestHoldingTime" SG_ 271 ASAU_AirSptModeRValueSet 5000;
BA_ "Version" SG_ 271 ASAU_AirSptModeRValueSet "19.11.06";
BA_ "Description" SG_ 271 ASAU_NotFootMsgOperStaWarnPE "Passenger Foot Massage Operation Disable Mode";
BA_ "GenSigSendType" SG_ 271 ASAU_NotFootMsgOperStaWarnPE 4;
BA_ "UserSigValidity" SG_ 271 ASAU_NotFootMsgOperStaWarnPE 3;
BA_REL_ "GenSigTimeoutTime" BU_SG_REL_ ATS SG_ 271 ASAU_NotFootMsgOperStaWarnPE 1500;
BA_ "NetworkRequest" SG_ 271 ASAU_NotFootMsgOperStaWarnPE 0;
BA_ "NetworkRequestHoldingTime" SG_ 271 ASAU_NotFootMsgOperStaWarnPE 5000;
BA_ "Version" SG_ 271 ASAU_NotFootMsgOperStaWarnPE "20.08.00";
BA_ "Description" SG_ 271 ASAU_RRFootAirSptRValueSet "Foot Air Support USM R Value";
BA_ "GenSigSendType" SG_ 271 ASAU_RRFootAirSptRValueSet 4;
BA_ "UserSigValidity" SG_ 271 ASAU_RRFootAirSptRValueSet 3;
BA_REL_ "GenSigTimeoutTime" BU_SG_REL_ ATS SG_ 271 ASAU_RRFootAirSptRValueSet 1500;
BA_ "NetworkRequest" SG_ 271 ASAU_RRFootAirSptRValueSet 0;
BA_ "NetworkRequestHoldingTime" SG_ 271 ASAU_RRFootAirSptRValueSet 5000;
BA_ "Version" SG_ 271 ASAU_RRFootAirSptRValueSet "19.12.00";
BA_ "Description" SG_ 271 ASAU_RRFootAirSptHeatRValueSet "Foot Air Support Heat USM R Value";
BA_ "GenSigSendType" SG_ 271 ASAU_RRFootAirSptHeatRValueSet 4;
BA_ "UserSigValidity" SG_ 271 ASAU_RRFootAirSptHeatRValueSet 3;
BA_REL_ "GenSigTimeoutTime" BU_SG_REL_ ATS SG_ 271 ASAU_RRFootAirSptHeatRValueSet 1500;
BA_ "NetworkRequest" SG_ 271 ASAU_RRFootAirSptHeatRValueSet 0;
BA_ "NetworkRequestHoldingTime" SG_ 271 ASAU_RRFootAirSptHeatRValueSet 5000;
BA_ "Version" SG_ 271 ASAU_RRFootAirSptHeatRValueSet "20.01.02";
BA_ "Description" SG_ 271 ASAU_MoodTrpyRValueSet "Passenger Seat Mood Therapy R Value";
BA_ "GenSigSendType" SG_ 271 ASAU_MoodTrpyRValueSet 4;
BA_ "UserSigValidity" SG_ 271 ASAU_MoodTrpyRValueSet 3;
BA_REL_ "GenSigTimeoutTime" BU_SG_REL_ CGW_CCU SG_ 271 ASAU_MoodTrpyRValueSet 1500;
BA_ "NetworkRequest" SG_ 271 ASAU_MoodTrpyRValueSet 0;
BA_ "NetworkRequestHoldingTime" SG_ 271 ASAU_MoodTrpyRValueSet 5000;
BA_ "Version" SG_ 271 ASAU_MoodTrpyRValueSet "20.07.03";
BA_ "Description" SG_ 271 ASAU_MoodTrpyCareSta "Passenger Seat Mood Therapy Care Mode R Value";
BA_ "GenSigSendType" SG_ 271 ASAU_MoodTrpyCareSta 4;
BA_ "UserSigValidity" SG_ 271 ASAU_MoodTrpyCareSta 3;
BA_REL_ "GenSigTimeoutTime" BU_SG_REL_ CGW_CCU SG_ 271 ASAU_MoodTrpyCareSta 1500;
BA_ "NetworkRequest" SG_ 271 ASAU_MoodTrpyCareSta 0;
BA_ "NetworkRequestHoldingTime" SG_ 271 ASAU_MoodTrpyCareSta 5000;
BA_ "Version" SG_ 271 ASAU_MoodTrpyCareSta "20.07.12";
BA_ "Description" SG_ 271 ASAU_MoodTrpyComfSta "Passenger Seat Mood Therapy Comfort Mode R Value";
BA_ "GenSigSendType" SG_ 271 ASAU_MoodTrpyComfSta 4;
BA_ "UserSigValidity" SG_ 271 ASAU_MoodTrpyComfSta 3;
BA_REL_ "GenSigTimeoutTime" BU_SG_REL_ CGW_CCU SG_ 271 ASAU_MoodTrpyComfSta 1500;
BA_ "NetworkRequest" SG_ 271 ASAU_MoodTrpyComfSta 0;
BA_ "NetworkRequestHoldingTime" SG_ 271 ASAU_MoodTrpyComfSta 5000;
BA_ "Version" SG_ 271 ASAU_MoodTrpyComfSta "20.07.12";
BA_ "Description" SG_ 271 ASAU_AirSptStrRValueSet "Air Support Strenth(Massage Strenth) USM R Value";
BA_ "GenSigSendType" SG_ 271 ASAU_AirSptStrRValueSet 4;
BA_ "UserSigValidity" SG_ 271 ASAU_AirSptStrRValueSet 3;
BA_REL_ "GenSigTimeoutTime" BU_SG_REL_ CGW_CCU SG_ 271 ASAU_AirSptStrRValueSet 1500;
BA_ "NetworkRequest" SG_ 271 ASAU_AirSptStrRValueSet 0;
BA_ "NetworkRequestHoldingTime" SG_ 271 ASAU_AirSptStrRValueSet 5000;
BA_ "Version" SG_ 271 ASAU_AirSptStrRValueSet "20.07.11";
BA_ "GenMsgSendType" BO_ 255 0;
BA_ "Description" SG_ 255 BCM_Crc20Val "The data area for CRC calculation is based on the data length (DLC) of the message DB.

The CRC shall be calculated over the entire data block (excluding the CRC bytes) including the user data, alive counter and Data ID 

 

- CRC Polynomial (0x1D) , Initial Value : 0x00, XOR value : 0xFF, Data ID Mode : Both, Data ID : Message ID + 0xF800 

- The initial value is for CRC calculation and the message should be sent with the calculated result value. 

The mathematical expression to 8 bit CRC polynomial is given here. G(x) = x8 + x4 + x3 + x2 + 1";
BA_ "GenSigSendType" SG_ 255 BCM_Crc20Val 4;
BA_ "UserSigValidity" SG_ 255 BCM_Crc20Val 0;
BA_REL_ "GenSigTimeoutTime" BU_SG_REL_ RCM SG_ 255 BCM_Crc20Val 1500;
BA_ "Version" SG_ 255 BCM_Crc20Val "21.09.03";
BA_ "Description" SG_ 255 Window_BuffetRdctnActvSta "Power Window Buffetting Reduction Logic Activated Status (MV)";
BA_ "GenSigSendType" SG_ 255 Window_BuffetRdctnActvSta 4;
BA_ "UserSigValidity" SG_ 255 Window_BuffetRdctnActvSta 3;
BA_ "NetworkRequest" SG_ 255 Window_BuffetRdctnActvSta 0;
BA_ "NetworkRequestHoldingTime" SG_ 255 Window_BuffetRdctnActvSta 5000;
BA_ "Version" SG_ 255 Window_BuffetRdctnActvSta "23.10.03";
BA_ "Description" SG_ 255 BCM_AlvCnt20Val "For the first transmission request for a data element the counter shall be initialized with 0 and shall be incremented by 1

for every subsequent send request. When the counter reaches the maximum value(0xE), then it shall restart with 0 for the next send request";
BA_ "GenSigSendType" SG_ 255 BCM_AlvCnt20Val 4;
BA_ "UserSigValidity" SG_ 255 BCM_AlvCnt20Val 0;
BA_REL_ "GenSigTimeoutTime" BU_SG_REL_ RCM SG_ 255 BCM_AlvCnt20Val 1500;
BA_ "Version" SG_ 255 BCM_AlvCnt20Val "21.09.03";
BA_ "Description" SG_ 255 BckGls_RrGlsHtdOnCmd "Rear Glass Heated Command";
BA_ "GenSigSendType" SG_ 255 BckGls_RrGlsHtdOnCmd 4;
BA_ "UserSigValidity" SG_ 255 BckGls_RrGlsHtdOnCmd 0;
BA_ "NetworkRequest" SG_ 255 BckGls_RrGlsHtdOnCmd 0;
BA_ "NetworkRequestHoldingTime" SG_ 255 BckGls_RrGlsHtdOnCmd 5000;
BA_ "Version" SG_ 255 BckGls_RrGlsHtdOnCmd "21.09.05";
BA_ "Description" SG_ 255 Wndshld_FrtGlsHtdOnCmd "Front Heated Glass Command";
BA_ "GenSigSendType" SG_ 255 Wndshld_FrtGlsHtdOnCmd 4;
BA_ "UserSigValidity" SG_ 255 Wndshld_FrtGlsHtdOnCmd 0;
BA_ "NetworkRequest" SG_ 255 Wndshld_FrtGlsHtdOnCmd 0;
BA_ "NetworkRequestHoldingTime" SG_ 255 Wndshld_FrtGlsHtdOnCmd 5000;
BA_ "Version" SG_ 255 Wndshld_FrtGlsHtdOnCmd "20.08.02";
BA_ "Description" SG_ 255 Mirror_MirFldOpt "Outside Mirror Electric Fold Option Signal";
BA_ "GenSigSendType" SG_ 255 Mirror_MirFldOpt 4;
BA_ "UserSigValidity" SG_ 255 Mirror_MirFldOpt 0;
BA_ "NetworkRequest" SG_ 255 Mirror_MirFldOpt 0;
BA_ "NetworkRequestHoldingTime" SG_ 255 Mirror_MirFldOpt 5000;
BA_ "Version" SG_ 255 Mirror_MirFldOpt "21.04.00";
BA_ "Description" SG_ 255 Window_AsstPwrWdwSunroofEnblSta "Assist Power Window And Sunroof Enable";
BA_ "GenSigSendType" SG_ 255 Window_AsstPwrWdwSunroofEnblSta 4;
BA_ "UserSigValidity" SG_ 255 Window_AsstPwrWdwSunroofEnblSta 0;
BA_REL_ "GenSigTimeoutTime" BU_SG_REL_ RCM SG_ 255 Window_AsstPwrWdwSunroofEnblSta 1500;
BA_ "NetworkRequest" SG_ 255 Window_AsstPwrWdwSunroofEnblSta 0;
BA_ "NetworkRequestHoldingTime" SG_ 255 Window_AsstPwrWdwSunroofEnblSta 5000;
BA_ "Version" SG_ 255 Window_AsstPwrWdwSunroofEnblSta "20.08.02";
BA_ "Description" SG_ 255 Window_RrPwrWdwEnblSta "Rear Power Window Enable";
BA_ "GenSigSendType" SG_ 255 Window_RrPwrWdwEnblSta 4;
BA_ "UserSigValidity" SG_ 255 Window_RrPwrWdwEnblSta 0;
BA_REL_ "GenSigTimeoutTime" BU_SG_REL_ RCM SG_ 255 Window_RrPwrWdwEnblSta 1500;
BA_ "NetworkRequest" SG_ 255 Window_RrPwrWdwEnblSta 0;
BA_ "NetworkRequestHoldingTime" SG_ 255 Window_RrPwrWdwEnblSta 5000;
BA_ "Version" SG_ 255 Window_RrPwrWdwEnblSta "20.08.02";
BA_ "Description" SG_ 255 Window_RrPwrWdwLkInd "RearPpower Window Lock Indicator Command";
BA_ "GenSigSendType" SG_ 255 Window_RrPwrWdwLkInd 4;
BA_ "UserSigValidity" SG_ 255 Window_RrPwrWdwLkInd 0;
BA_ "NetworkRequest" SG_ 255 Window_RrPwrWdwLkInd 0;
BA_ "NetworkRequestHoldingTime" SG_ 255 Window_RrPwrWdwLkInd 5000;
BA_ "Version" SG_ 255 Window_RrPwrWdwLkInd "20.08.02";
BA_ "Description" SG_ 255 Window_DrvPwrWdwCmd "Driver Power Window Command";
BA_ "GenSigSendType" SG_ 255 Window_DrvPwrWdwCmd 4;
BA_ "UserSigValidity" SG_ 255 Window_DrvPwrWdwCmd 0;
BA_ "NetworkRequest" SG_ 255 Window_DrvPwrWdwCmd 0;
BA_ "NetworkRequestHoldingTime" SG_ 255 Window_DrvPwrWdwCmd 5000;
BA_ "Version" SG_ 255 Window_DrvPwrWdwCmd "21.01.06";
BA_ "Description" SG_ 255 Window_AsstPwrWdwCmd "Assist Power Window Command";
BA_ "GenSigSendType" SG_ 255 Window_AsstPwrWdwCmd 4;
BA_ "UserSigValidity" SG_ 255 Window_AsstPwrWdwCmd 0;
BA_ "NetworkRequest" SG_ 255 Window_AsstPwrWdwCmd 0;
BA_ "NetworkRequestHoldingTime" SG_ 255 Window_AsstPwrWdwCmd 5000;
BA_ "Version" SG_ 255 Window_AsstPwrWdwCmd "21.03.00";
BA_ "Description" SG_ 255 Window_RrLftPwrWdwCmd "Rear Left Power Window Command";
BA_ "GenSigSendType" SG_ 255 Window_RrLftPwrWdwCmd 4;
BA_ "UserSigValidity" SG_ 255 Window_RrLftPwrWdwCmd 0;
BA_ "NetworkRequest" SG_ 255 Window_RrLftPwrWdwCmd 0;
BA_ "NetworkRequestHoldingTime" SG_ 255 Window_RrLftPwrWdwCmd 5000;
BA_ "Version" SG_ 255 Window_RrLftPwrWdwCmd "21.03.00";
BA_ "Description" SG_ 255 Window_RrRtPwrWdwCmd "Rear Right Power Window Command";
BA_ "GenSigSendType" SG_ 255 Window_RrRtPwrWdwCmd 4;
BA_ "UserSigValidity" SG_ 255 Window_RrRtPwrWdwCmd 0;
BA_ "NetworkRequest" SG_ 255 Window_RrRtPwrWdwCmd 0;
BA_ "NetworkRequestHoldingTime" SG_ 255 Window_RrRtPwrWdwCmd 5000;
BA_ "Version" SG_ 255 Window_RrRtPwrWdwCmd "21.03.00";
BA_ "Description" SG_ 255 Mirror_FldUnfldCmd "Mirror Folding Unfolding Command";
BA_ "GenSigSendType" SG_ 255 Mirror_FldUnfldCmd 4;
BA_ "UserSigValidity" SG_ 255 Mirror_FldUnfldCmd 0;
BA_ "NetworkRequest" SG_ 255 Mirror_FldUnfldCmd 0;
BA_ "NetworkRequestHoldingTime" SG_ 255 Mirror_FldUnfldCmd 5000;
BA_ "Version" SG_ 255 Mirror_FldUnfldCmd "21.03.00";
BA_ "Description" SG_ 255 Mirror_FldCtrlSta "Mirror Fold and Folding Control State";
BA_ "GenSigSendType" SG_ 255 Mirror_FldCtrlSta 4;
BA_ "UserSigValidity" SG_ 255 Mirror_FldCtrlSta 0;
BA_ "NetworkRequest" SG_ 255 Mirror_FldCtrlSta 0;
BA_ "NetworkRequestHoldingTime" SG_ 255 Mirror_FldCtrlSta 5000;
BA_ "Version" SG_ 255 Mirror_FldCtrlSta "21.03.00";
BA_ "Description" SG_ 255 Mirror_UnFldCtrlSta "Mirror Unfold and Unfolding Control State";
BA_ "GenSigSendType" SG_ 255 Mirror_UnFldCtrlSta 4;
BA_ "UserSigValidity" SG_ 255 Mirror_UnFldCtrlSta 0;
BA_ "NetworkRequest" SG_ 255 Mirror_UnFldCtrlSta 0;
BA_ "NetworkRequestHoldingTime" SG_ 255 Mirror_UnFldCtrlSta 5000;
BA_ "Version" SG_ 255 Mirror_UnFldCtrlSta "21.03.00";
BA_ "Description" SG_ 255 Mirror_PosMnlCmd "Mirror Positioning Command";
BA_ "GenSigSendType" SG_ 255 Mirror_PosMnlCmd 4;
BA_ "UserSigValidity" SG_ 255 Mirror_PosMnlCmd 0;
BA_ "NetworkRequest" SG_ 255 Mirror_PosMnlCmd 0;
BA_ "NetworkRequestHoldingTime" SG_ 255 Mirror_PosMnlCmd 5000;
BA_ "Version" SG_ 255 Mirror_PosMnlCmd "21.10.04";
BA_ "Description" SG_ 255 Mirror_SelSwIndCmd "Mirror Select Switch Indicator Command";
BA_ "GenSigSendType" SG_ 255 Mirror_SelSwIndCmd 4;
BA_ "UserSigValidity" SG_ 255 Mirror_SelSwIndCmd 0;
BA_ "NetworkRequest" SG_ 255 Mirror_SelSwIndCmd 0;
BA_ "NetworkRequestHoldingTime" SG_ 255 Mirror_SelSwIndCmd 5000;
BA_ "Version" SG_ 255 Mirror_SelSwIndCmd "21.03.00";
BA_ "Description" SG_ 255 BCM_SafetyWdwOptTyp2 "Option Signal for Safety Window System";
BA_ "GenSigSendType" SG_ 255 BCM_SafetyWdwOptTyp2 4;
BA_ "UserSigValidity" SG_ 255 BCM_SafetyWdwOptTyp2 0;
BA_ "NetworkRequest" SG_ 255 BCM_SafetyWdwOptTyp2 0;
BA_ "NetworkRequestHoldingTime" SG_ 255 BCM_SafetyWdwOptTyp2 5000;
BA_ "Version" SG_ 255 BCM_SafetyWdwOptTyp2 "20.08.05";
BA_ "Description" SG_ 255 Mirror_LHOSMirPlyBckSta "This siganl indicates Left O/S Mirror moving state for IMS From BDC";
BA_ "GenSigSendType" SG_ 255 Mirror_LHOSMirPlyBckSta 4;
BA_ "UserSigValidity" SG_ 255 Mirror_LHOSMirPlyBckSta 0;
BA_REL_ "GenSigTimeoutTime" BU_SG_REL_ GW_DPSU SG_ 255 Mirror_LHOSMirPlyBckSta 1500;
BA_ "NetworkRequest" SG_ 255 Mirror_LHOSMirPlyBckSta 0;
BA_ "NetworkRequestHoldingTime" SG_ 255 Mirror_LHOSMirPlyBckSta 5000;
BA_ "Version" SG_ 255 Mirror_LHOSMirPlyBckSta "21.03.00";
BA_ "Description" SG_ 255 Mirror_RHOSMirPlyBckSta "This siganl indicates Right O/S Mirror moving state for IMS From BDC";
BA_ "GenSigSendType" SG_ 255 Mirror_RHOSMirPlyBckSta 4;
BA_ "UserSigValidity" SG_ 255 Mirror_RHOSMirPlyBckSta 0;
BA_REL_ "GenSigTimeoutTime" BU_SG_REL_ GW_DPSU SG_ 255 Mirror_RHOSMirPlyBckSta 1500;
BA_ "NetworkRequest" SG_ 255 Mirror_RHOSMirPlyBckSta 0;
BA_ "NetworkRequestHoldingTime" SG_ 255 Mirror_RHOSMirPlyBckSta 5000;
BA_ "Version" SG_ 255 Mirror_RHOSMirPlyBckSta "21.03.00";
BA_ "Description" SG_ 255 Mirror_SelSwSta "Outside Mirror Select Button Status";
BA_ "GenSigSendType" SG_ 255 Mirror_SelSwSta 4;
BA_ "UserSigValidity" SG_ 255 Mirror_SelSwSta 0;
BA_ "NetworkRequest" SG_ 255 Mirror_SelSwSta 0;
BA_ "NetworkRequestHoldingTime" SG_ 255 Mirror_SelSwSta 5000;
BA_ "Version" SG_ 255 Mirror_SelSwSta "20.12.00";
BA_ "Description" SG_ 255 BckGls_RrGlsHtdOpt "Back Glass_Rear Glass Heated Option Signal";
BA_ "GenSigSendType" SG_ 255 BckGls_RrGlsHtdOpt 4;
BA_ "UserSigValidity" SG_ 255 BckGls_RrGlsHtdOpt 0;
BA_ "Version" SG_ 255 BckGls_RrGlsHtdOpt "21.06.08";
BA_ "GenMsgSendType" BO_ 2395189761 0;
BA_ "VFrameFormat" BO_ 2395189761 1;
BA_ "Description" SG_ 2395189761 DATC_Crc10Val "The data area for CRC calculation is based on the data length (DLC) of the message DB.

The CRC shall be calculated over the entire data block (excluding the CRC bytes) including the user data, alive counter and Data ID



- CRC Polynomial (0x1021) , Initial Value : 0xFFFF, XOR value : 0x0000, Data ID : Message ID + 0xF800 

- The initial value is for CRC calculation and the message should be sent with the calculated result value. 

- The mathematical expression to 16 bit CRC polynomial is given here. G(x) = x16 + x12 + x5 + 1



<For CRC calculation of CAN-FD Msg for HS CAN domain ECUs>



- HS-CAN Messages that routed from CAN-FD domain are using 29 bit Extended CAN ID and splitted into 8 Byte Messages.

(from 1 to 4 Msgs, depending on source CAN-FD Msg¡¯s DLC)

- For splitted CAN-FD Msgs¡¯ CRC calculation, HS CAN ECUs should use source CAN-FD Msg¡¯s original STD ID. 

- The original STD ID can be read from Ext ID¡¯s 4~6th Byte.

Eg. STD 0x6AA : EXT SPLT 0x1A8[6AA]01 / 0x1A8[6AA]02 / 0x1A8[6AA]03 / 0x1A8[6AA]04 

(2~4th splitited Msgs can be omitted depending on source CAN-FD Msg¡¯s DLC)

- Aslo, HS-CAN ECUs should use merged data block (from whole splitted Msg) for CRC calculation.";
BA_ "GenSigSendType" SG_ 2395189761 DATC_Crc10Val 4;
BA_ "GenSigStartValue" SG_ 2395189761 DATC_Crc10Val 65535;
BA_ "UserSigValidity" SG_ 2395189761 DATC_Crc10Val 3;
BA_ "Version" SG_ 2395189761 DATC_Crc10Val "21.09.03";
BA_ "Description" SG_ 2395189761 DATC_AlvCnt10Val "For the first transmission request for a data element the counter shall be initialized with 0 and shall be incremented by 1 for every subsequent send request. 

When the counter reaches the maximum value(0xFF), then it shall restart with 0 for the next send request";
BA_ "GenSigSendType" SG_ 2395189761 DATC_AlvCnt10Val 4;
BA_ "UserSigValidity" SG_ 2395189761 DATC_AlvCnt10Val 3;
BA_ "Version" SG_ 2395189761 DATC_AlvCnt10Val "21.09.03";
BA_ "Description" SG_ 2395189761 DATC_Typ "HTR CONTROL TYPE

Bit0 (FR Control) : 0 ? ATC / 1 ? MTC

Bit1~2 (Temp) : 0 ? Single / 1 ? Dual / 2 ? 3Zone / 3 ? 4Zone

Bit3~4 (Mode) : 0 ? Single / 1 ? Dual / 2 ? 3Zone / 3 ? 4Zone

Bit5 (Rear Control) : 0 ? None or MTC / 1- ATC

Bit6 (RHD) : 0 ? LHD / 1 ? RHD

Bit7 (EU) : 0 ? Others / 1 ? EU";
BA_ "GenSigSendType" SG_ 2395189761 DATC_Typ 4;
BA_ "UserSigValidity" SG_ 2395189761 DATC_Typ 3;
BA_REL_ "GenSigTimeoutTime" BU_SG_REL_ ATS SG_ 2395189761 DATC_Typ 1500;
BA_REL_ "GenSigTimeoutTime" BU_SG_REL_ RLHV SG_ 2395189761 DATC_Typ 1500;
BA_REL_ "GenSigTimeoutTime" BU_SG_REL_ RRHV SG_ 2395189761 DATC_Typ 1500;
BA_REL_ "GenSigTimeoutTime" BU_SG_REL_ SHVU_FR SG_ 2395189761 DATC_Typ 1500;
BA_REL_ "GenSigTimeoutTime" BU_SG_REL_ SHVU_RR SG_ 2395189761 DATC_Typ 1500;
BA_ "Version" SG_ 2395189761 DATC_Typ "20.03.01";
BA_ "Description" SG_ 2395189761 DATC_Opt1Typ "Bit0 : (ADS) : 0 - Non ADS / 1 - ADS

Bit1 : (AQS) : 0 - Non AQS / 1 ? AQS

Bit2 : (MAX AC) : 0 - Non MAX AC / 1 - MAX AC

Bit3 : (SYNC) : 0 - Non SYNC / 1 - SYNC

Bit4 : (DUST) : 0 - Non AIR PURIFIER / 1 - AIR PURIFIER

Bit5 : (Smart_Vent) : 0 - Non SMART VENT / 1 ? SMART VENT

Bit6 : (CO2) : 0 - Non CO2 / 1 - CO2

Bit7 : (REAR LOCK) : 0 - NON REAR LOCK / 1 - REAR LOCK

HTR CONTROL OPTION";
BA_ "GenSigSendType" SG_ 2395189761 DATC_Opt1Typ 4;
BA_ "UserSigValidity" SG_ 2395189761 DATC_Opt1Typ 3;
BA_REL_ "GenSigTimeoutTime" BU_SG_REL_ ATS SG_ 2395189761 DATC_Opt1Typ 1500;
BA_ "Version" SG_ 2395189761 DATC_Opt1Typ "18.05.00";
BA_ "Description" SG_ 2395189761 DATC_Opt3Typ "This signal indicates Option of HTR Control.



Bit0~1 (Button Type)  : 0 ? Not Display in AVN /

                              1 ? Single (Blower-Temp-Mode) /

                              2 ? Single (Temp-Mode-Blower) / 

                              3 ? Dual ¡¤ 3zone ¡¤ 4zone / 

Bit2 : 0 - Defogging USM Not Apply / 1 - Defogging USM Apply 

Bit3 : 0 - Automatic Ventilation USM Not Apply / 1 - Automatic Ventilation USM Apply

Bit4 : 0 ? Auto AirCleaningSystem USM Not Apply / 1 - Auto AirCleaningSystem USM Apply

Bit5 : 0 ? Washer fluid Control USM Not Apply / 1 - Washer fluid Control USM Apply

Bit6~7 : 0 - Haptic Intensity USM Not Apply 

              1 - Haptic Intensity USM Apply (3-Level)

              2 - Haptic Intensity USM Apply (5-Level)

              3 - Reserved

0xFF : Invalid";
BA_ "GenSigSendType" SG_ 2395189761 DATC_Opt3Typ 4;
BA_ "UserSigValidity" SG_ 2395189761 DATC_Opt3Typ 3;
BA_REL_ "GenSigTimeoutTime" BU_SG_REL_ ATS SG_ 2395189761 DATC_Opt3Typ 1500;
BA_ "Version" SG_ 2395189761 DATC_Opt3Typ "18.11.00";
BA_ "Description" SG_ 2395189761 DATC_Opt2Typ "Bit0 : (FRONT BLOWER) : 0 - SINGLE BLOWER / 1 ? DUAL BLOWER

Bit1 : (FRONT AUTO ZONE) : 0 - SINGLE AUTO / 1 - DUAL AUTO

Bit2 : (LCD / NON LCD TYPE) : 0 - NON LCD /  1 - LCD TYPE

Bit3 : (INDIRECT VENT) : 0 - NON INDIRECT VENT /  1 - INDIRECT VENT

HTR CONTROL OPTION";
BA_ "GenSigSendType" SG_ 2395189761 DATC_Opt2Typ 4;
BA_ "UserSigValidity" SG_ 2395189761 DATC_Opt2Typ 3;
BA_REL_ "GenSigTimeoutTime" BU_SG_REL_ ATS SG_ 2395189761 DATC_Opt2Typ 1500;
BA_ "Version" SG_ 2395189761 DATC_Opt2Typ "19.04.06";
BA_ "Description" SG_ 2395189761 DATC_Opt4Typ "This signal indicates Option of HTR Control.



Bit0 (Driver Only Button) :  0 ? NOT Apply / 1 ? Apply

Bit1 (HEAT Button) :  0 ? NOT Apply / 1 ? Apply

Bit2 (Multi-Air Mode) : 0 ? Not Apply / 1 - Apply

Bit3 : (Scheduled Ventilation) : 0 ? Not Apply / 1 ? Apply

0xF : invalid";
BA_ "GenSigSendType" SG_ 2395189761 DATC_Opt4Typ 4;
BA_ "UserSigValidity" SG_ 2395189761 DATC_Opt4Typ 7;
BA_REL_ "GenSigTimeoutTime" BU_SG_REL_ ATS SG_ 2395189761 DATC_Opt4Typ 1500;
BA_ "Version" SG_ 2395189761 DATC_Opt4Typ "19.08.08";
BA_ "Description" SG_ 2395189761 DATC_StrWhlUSMSta "DATC and Steering Wheel heat Control Display request signal";
BA_ "GenSigSendType" SG_ 2395189761 DATC_StrWhlUSMSta 4;
BA_ "UserSigValidity" SG_ 2395189761 DATC_StrWhlUSMSta 3;
BA_REL_ "GenSigTimeoutTime" BU_SG_REL_ GW_APSU SG_ 2395189761 DATC_StrWhlUSMSta 1500;
BA_ "Version" SG_ 2395189761 DATC_StrWhlUSMSta "18.03.05";
BA_ "Description" SG_ 2395189761 DATC_StrWhlHtngReq "Steering Wheel heat function on/off request";
BA_ "GenSigSendType" SG_ 2395189761 DATC_StrWhlHtngReq 4;
BA_ "UserSigValidity" SG_ 2395189761 DATC_StrWhlHtngReq 3;
BA_ "Version" SG_ 2395189761 DATC_StrWhlHtngReq "18.01.07";
BA_ "GenMsgSendType" BO_ 2365803009 0;
BA_ "GenMsgCycleTime" BO_ 2365803009 1000;
BA_ "GenMsgCycleTimeFast" BO_ 2365803009 0;
BA_ "GenMsgNrOfRepetition" BO_ 2365803009 0;
BA_ "VFrameFormat" BO_ 2365803009 1;
BA_ "Description" SG_ 2365803009 DATC_Crc16Val "The data area for CRC calculation is based on the data length (DLC) of the message DB.

The CRC shall be calculated over the entire data block (excluding the CRC bytes) including the user data, alive counter and Data ID



- CRC Polynomial (0x1021) , Initial Value : 0xFFFF, XOR value : 0x0000, Data ID : Message ID + 0xF800 

- The initial value is for CRC calculation and the message should be sent with the calculated result value. 

- The mathematical expression to 16 bit CRC polynomial is given here. G(x) = x16 + x12 + x5 + 1



<For CRC calculation of CAN-FD Msg for HS CAN domain ECUs>



- HS-CAN Messages that routed from CAN-FD domain are using 29 bit Extended CAN ID and splitted into 8 Byte Messages.

(from 1 to 4 Msgs, depending on source CAN-FD Msg¡¯s DLC)

- For splitted CAN-FD Msgs¡¯ CRC calculation, HS CAN ECUs should use source CAN-FD Msg¡¯s original STD ID. 

- The original STD ID can be read from Ext ID¡¯s 4~6th Byte.

Eg. STD 0x6AA : EXT SPLT 0x1A8[6AA]01 / 0x1A8[6AA]02 / 0x1A8[6AA]03 / 0x1A8[6AA]04 

(2~4th splitited Msgs can be omitted depending on source CAN-FD Msg¡¯s DLC)

- Aslo, HS-CAN ECUs should use merged data block (from whole splitted Msg) for CRC calculation.";
BA_ "GenSigStartValue" SG_ 2365803009 DATC_Crc16Val 65535;
BA_ "UserSigValidity" SG_ 2365803009 DATC_Crc16Val 7;
BA_ "Version" SG_ 2365803009 DATC_Crc16Val "21.09.03";
BA_ "Description" SG_ 2365803009 DATC_AlvCnt16Val "For the first transmission request for a data element the counter shall be initialized with 0 and shall be incremented by 1 for every subsequent send request. 

When the counter reaches the maximum value(0xFF), then it shall restart with 0 for the next send request";
BA_ "UserSigValidity" SG_ 2365803009 DATC_AlvCnt16Val 7;
BA_ "Version" SG_ 2365803009 DATC_AlvCnt16Val "21.09.03";
BA_ "Description" SG_ 2365803009 DATC_SwVer1 "This signal idnicates DATC Software Version to display on H_U



Change it to an ASCII code value.";
BA_ "GenSigStartValue" SG_ 2365803009 DATC_SwVer1 127;
BA_ "UserSigValidity" SG_ 2365803009 DATC_SwVer1 7;
BA_ "Version" SG_ 2365803009 DATC_SwVer1 "19.09.02";
BA_ "Description" SG_ 2365803009 DATC_SwVer2 "This signal indicates DATC Software Version to display on H_U



Change it to an ASCII code value.";
BA_ "GenSigStartValue" SG_ 2365803009 DATC_SwVer2 127;
BA_ "UserSigValidity" SG_ 2365803009 DATC_SwVer2 7;
BA_ "Version" SG_ 2365803009 DATC_SwVer2 "19.09.02";
BA_ "Description" SG_ 2365803009 DATC_SwVer3 "This signal indicates DATC Software Version to display on H_U



Change it to an ASCII code value.";
BA_ "GenSigStartValue" SG_ 2365803009 DATC_SwVer3 127;
BA_ "UserSigValidity" SG_ 2365803009 DATC_SwVer3 7;
BA_ "Version" SG_ 2365803009 DATC_SwVer3 "19.09.02";
BA_ "Description" SG_ 2365803009 DATC_Typ2 "Bit0: (AVN Controllable) :  0 ? NOT Apply / 1 ? Apply

Bit1~2 (Multi Auto Indicator) : 0 ? Front & Rear Not Applied (F/R 1step) / 1 ? Front 3 Step & Rear Not Applied (F 3step & R 1step) / 2 ? Front 3 Step & Rear 3 Step (F/R 3step)  / 3 ? Reserved

Bit3~5 (Front Mode Type) : 0 ? 4 MODE / 1 ? 6MODE / 2 ? 7MODE  / 3 ~ 7 ? Reserved

Bit6 (Fine Dust Sensor) : 0 - Fine Dust Sensor Not Applied / 1 - Fine Dust Sensor Applied.

Bit7~8 (Multi Auto Text) : 0 - Multi Auto State Text Not Applied / 1 - Multi Auto State Text Display Only Applied / 2 - Multi Auto State Text Display & Control Applied / 3 ? Reserved

Bit9 (Mode Def Type) : 0 ? Symbol Type / 1 ? Arrow Type

Bit10 : (AIR PURIFIER Button Type) : 0 ? According to the ¡®Controllable(H_U)¡¯ or ¡®Air Purify (Phone App)¡¯  Bit / 1 ? Air Purifier Button Not Applied

Bit11~15 : Reserved";
BA_ "UserSigValidity" SG_ 2365803009 DATC_Typ2 7;
BA_REL_ "GenSigTimeoutTime" BU_SG_REL_ ATS SG_ 2365803009 DATC_Typ2 5000;
BA_ "Version" SG_ 2365803009 DATC_Typ2 "22.02.02";
BA_ "GenMsgSendType" BO_ 2365803010 0;
BA_ "GenMsgCycleTime" BO_ 2365803010 1000;
BA_ "GenMsgCycleTimeFast" BO_ 2365803010 0;
BA_ "GenMsgNrOfRepetition" BO_ 2365803010 0;
BA_ "VFrameFormat" BO_ 2365803010 1;
BA_ "Description" SG_ 2365803010 DATC_SwVer4 "This signal idnicates DATC Detail Software Version



Change it to an ASCII code value.";
BA_ "GenSigStartValue" SG_ 2365803010 DATC_SwVer4 127;
BA_ "UserSigValidity" SG_ 2365803010 DATC_SwVer4 7;
BA_ "Version" SG_ 2365803010 DATC_SwVer4 "21.10.05";
BA_ "Description" SG_ 2365803010 DATC_Typ_All_1 "This signal have to be used together with DATC_Typ_All_1~n signals.



Bit0~1 (Front Control Type) : 0 ? None / 1 ? MTC / 2 ? ATC / 3 ? (Reserved)

Bit2~3 (2nd Rear Control Type) : 0 ? None /  1 ? MTC / 2 ? ATC / 3 ? (Reserved)

Bit4~5 (3rd Rear Control Type) : 0 ? None /  1 ? MTC / 2 ? ATC / 3 ? (Reserved)

Bit6~9 (LCD TYPE) :   0- None / 1 - NON LCD /  2 - Mono SEG TYPE / 3 ? Color SEG TYPE / 4 - TFT LCD TYPE / 5~15 ? Reserved

Bit10 (Climate Controller Drive Type ) : 0 ? LHD Type  /  1 ? RHD Type

Bit11 (Mode Def Type) : 0 ? Symbol Type / 1 ? Arrow Type

Bit12~14 (Front Mode Type) : 0 ? 4 MODE / 1 ? 6MODE / 2 ? 7MODE  / 3 ~ 7 ? Reserved

Bit15 : Reserved";
BA_ "UserSigValidity" SG_ 2365803010 DATC_Typ_All_1 7;
BA_ "Version" SG_ 2365803010 DATC_Typ_All_1 "22.06.05";
BA_ "Description" SG_ 2365803010 DATC_Typ_All_2 "This signal have to be used together with DATC_Typ_All_1~n signals.



Bit0~1 (Front Mode Button Type) : 0 - 1button / 1 - 2button / 2 - 3button / 3 ? Reserved

Bit2 (Blower Button Type) : 0 - Blower down type / 1 - blower down off type

Bit3 (Front SYNC Button): 0 ? None / 1 ? Apply

Bit4 (2nd Rear SYNC Button): 0 ? None / 1 ? Apply

Bit5 (3rd Rear SYNC Button): 0 ? None / 1 ? Apply

Bit6 (Driver Only Button) :  0 ? None / 1 ? Apply

Bit7 (HEAT Button) :  0 ? None / 1 ? Apply

Bit8 : (REAR LOCK Button) : 0 ? None / 1 ? Apply

Bit9 : (AirClean Button) : 0 ? According to the ¡®Controllable(H_U)¡¯ or ¡®Air Purify (Phone App)¡¯  Bit / 1 ? Air Purifier Button Deleted

Bit10 : (2nd A/C Button) : 0 - None / 1 - Apply 

Bit11 : (3rd A/C Button) : 0 - None / 1 - Apply 

Bit12 : (Front On Button) : 0 ? None / 1 ? Apply

Bit13 : (2nd Rear On Button) : 0 ? None / 1 ? Apply

Bit14 : (3rd Rear On Button) : 0 ? None / 1 ? Apply

Bit15 (Eco Zone Button) :? 0 ? None / 1 ? Apply";
BA_ "UserSigValidity" SG_ 2365803010 DATC_Typ_All_2 7;
BA_ "Version" SG_ 2365803010 DATC_Typ_All_2 "24.01.04";
BA_ "Description" SG_ 2365803010 DATC_SwVer5 "This signal idnicates DATC Detail Software Version



Change it to an ASCII code value.";
BA_ "GenSigStartValue" SG_ 2365803010 DATC_SwVer5 127;
BA_ "UserSigValidity" SG_ 2365803010 DATC_SwVer5 7;
BA_ "Version" SG_ 2365803010 DATC_SwVer5 "21.10.05";
BA_ "GenMsgSendType" BO_ 2365803011 0;
BA_ "GenMsgCycleTime" BO_ 2365803011 1000;
BA_ "GenMsgCycleTimeFast" BO_ 2365803011 0;
BA_ "GenMsgNrOfRepetition" BO_ 2365803011 0;
BA_ "VFrameFormat" BO_ 2365803011 1;
BA_ "Description" SG_ 2365803011 DATC_Typ_All_3 "This signal have to be used together with DATC_Typ_All_1~6 signals.



Bit0~1 (Front Mode Control): 0 ? None / 1 ? Single / 2 - Dual / 3 ? (Reserved) 

Bit2~3 (2nd Rear Mode Control): 0 ? None / 1 ? Single / 2 - Dual / 3 ? (Reserved) 

Bit4~5 (3rd Rear Mode Control): 0 ? None / 1 ? Single / 2 - Dual / 3 ? (Reserved) 

Bit6~7 (Front Blower Control): 0 ? None / 1 ? Single / 2 - Dual / 3 ? (Reserved)

Bit8~9 (2nd Rear Blower Control): 0 ? None / 1 ? Single / 2 - Dual / 3 ? (Reserved)

Bit10~11 (3rd Rear Blower Control): 0 ? None / 1 ? Single / 2 - Dual / 3 ? (Reserved)

Bit12~15 : Reserved";
BA_ "UserSigValidity" SG_ 2365803011 DATC_Typ_All_3 7;
BA_ "Version" SG_ 2365803011 DATC_Typ_All_3 "22.06.05";
BA_ "Description" SG_ 2365803011 DATC_Typ_All_4 "This signal have to be used together with DATC_Typ_All_1~6 signals.



Bit0~1 (Front Temp Control): 0 ? None / 1 ? Single / 2 - Dual / 3 ? (Reserved)

Bit2~3 (2nd Rear Temp Control): 0 ? None / 1 ? Single / 2 - Dual / 3 ? (Reserved) 

Bit4~5 (3rd Rear Temp Control): 0 ? None / 1 ? Single / 2 - Dual / 3 ? (Reserved) 

Bit6~7 (Front Auto Control): 0 ? None / 1 ? Single / 2 - Dual / 3 ? (Reserved) 

Bit8~9 (2nd Rear Auto Control): 0 ? None / 1 ? Single / 2 - Dual / 3 ? (Reserved)  

Bit10~11 (3rd Rear Auto Control): 0 ? None / 1 ? Single / 2 - Dual / 3 ? (Reserved) 

Bit12 (AVN Front Controllable): 0 ? None / 1 ? Controllable Apply

Bit13 (AVN 2nd Rear Controllable): 0 ? None / 1 ? Controllable Apply

Bit14 (AVN 3rd Rear Controllable): 0 ? None / 1 ? Controllable Apply

Bit15 : Reserved";
BA_ "UserSigValidity" SG_ 2365803011 DATC_Typ_All_4 7;
BA_ "Version" SG_ 2365803011 DATC_Typ_All_4 "22.07.02";
BA_ "Description" SG_ 2365803011 DATC_Typ_All_5 "This signal have to be used together with DATC_Typ_All_1~n signals.



Bit0~1 (FR DR Auto Step): 0 ? None / 1 ? Single(On/Off) / 2 ? 2 Step (High/Low/Off) / 3 ? 3 Step (High/Medium/Low/Off)

Bit2~3 (FR PS Auto Step): 0 ? None / 1 ? Single(On/Off) / 2 ? 2 Step (High/Low/Off) / 3 ? 3 Step (High/Medium/Low/Off)

Bit4~5 (2nd Rear Auto Step): 0 ? None / 1 ? Single(On/Off) / 2 ? 2 Step (High/Low/Off) / 3 ? 3 Step (High/Medium/Low/Off)

Bit6~7 (3rd Rear Auto Step): 0 ? None / 1 ? Single(On/Off) / 2 ? 2 Step (High/Low/Off) / 3 ? 3 Step (High/Medium/Low/Off)

Bit8~9 (FR DR Multi Auto Text) : 0 - Not Applied / 1 - Display Only / 2 - Display & Control / 3 ? Reserved

Bit10~11 (FR PS Multi Auto Text) : 0 - Not Applied / 1 - Display Only / 2 -Display & Control / 3 ? Reserved

Bit12~13 (2nd Multi Auto Text) : 0 - Not Applied / 1 - Display Only / 2 - Display & Control / 3 ? Reserved

Bit14~15 (3rd Multi Auto Text) : 0 - Not Applied / 1 - Display Only / 2 - Display & Control / 3 ? Reserved";
BA_ "UserSigValidity" SG_ 2365803011 DATC_Typ_All_5 7;
BA_ "Version" SG_ 2365803011 DATC_Typ_All_5 "22.06.05";
BA_ "Description" SG_ 2365803011 DATC_Typ_All_6 "This signal have to be used together with DATC_Typ_All_1~n signals.



Bit0~1 : (Climate OSD UI Type RQMT) : 0 ? None (Basic UI Type) / 1 ? (TEMP - Blower - Mode ? [Temp]) UI  / 2 ? (Temp - Mode - Blower ? [Temp]) UI / 3 ? Reserved ¡Ø If Dual Temp Type, [Temp] will be applied

Bit2~13 : Reserved

Bit14~15 (2nd Rear PS Auto Step): 0 ? None / 1 ? Single(On/Off) / 2 ? 2 Step (High/Low/Off) / 3 ? 3 Step (High/Medium/Low/Off)";
BA_ "UserSigValidity" SG_ 2365803011 DATC_Typ_All_6 7;
BA_ "Version" SG_ 2365803011 DATC_Typ_All_6 "23.11.06";
BA_ "GenMsgSendType" BO_ 2365803012 0;
BA_ "GenMsgCycleTime" BO_ 2365803012 1000;
BA_ "GenMsgCycleTimeFast" BO_ 2365803012 0;
BA_ "GenMsgNrOfRepetition" BO_ 2365803012 0;
BA_ "VFrameFormat" BO_ 2365803012 1;
BA_ "Description" SG_ 2365803012 DATC_Opt_Sys "Bit0 (ADS)  : 0 - Non ADS / 1 - ADS

Bit1 (Fine Dust Sensor) : 0 - Fine Dust Sensor Not Applied / 1 - Fine Dust Sensor Applied.

Bit2 : (INDIRECT VENT) :   0- NON INDIRECT VENT /  1- INDIRECT VENT

Bit3 : (Multi-Air Mode) : 0 ? Not Apply / 1 ? Apply

Bit4 : (Fragrance) : 0 ? Fragrance System Not Applied / 1 ? Fragrance System Applied

Bit5~6 (Haptic Intensity USM) : 0 ?Not Apply / 1 - Apply (3 Level) / 2 - Apply (5 Level) / 3 ? Reserved

Bit7 (Rear A/C) : 0 ? Rear A/C Not Applied / 1 ? Rear A/C Applied

Bit8 (Electric Vent, DR CTR) : 0 ? Not Apply / 1 ? Apply

Bit9 (Electric Vent, PS CTR) : 0 ? Not Apply / 1 ? Apply

Bit10 (Electric Vent, DR SD) : 0 ? Not Apply / 1 ? Apply

Bit11 (Electric Vent, PS SD) : 0 ? Not Apply / 1 ? Apply

Bit12 (Electric Vent, RL CTR) : 0 ? Not Apply / 1 ? Apply

Bit13 (Electric Vent, RR CTR) : 0 ? Not Apply / 1 ? Apply

Bit14 ~ 31  : Reserved";
BA_ "UserSigValidity" SG_ 2365803012 DATC_Opt_Sys 7;
BA_ "Version" SG_ 2365803012 DATC_Opt_Sys "23.10.11";
BA_ "Description" SG_ 2365803012 DATC_Opt_Func "Bit0 (AirPurify) : 0 - Non AIR PURIFIER /  1 - AIR PURIFIER 

Bit1 (Smart_Vent) : 0 - Non SMART VENT / 1 ? SMART VENT

Bit2 (Defaog USM) : 0 - Not Apply / 1 - Apply 

Bit3 (Auto Fresh USM) : 0 - Not Apply / 1 ? Apply

Bit4 (Auto AirClean USM - China) : 0 ? Not Apply / 1 -  Apply

Bit5 (Washer fluid Control USM) : 0 ?Not Apply / 1 ? Apply

Bit6 (Scheduled Blower) : 0 - Not Apply / 1 ? Apply

Bit7 (After Blow) : 0 - After Blow Not Applied / 1 - After Blow Applied

Bit8 (Rear Climate Auto Off) : 0 - Rear Climate Auto Off Not Applied / 1 - Rear Climate Auto Off Applied

Bit9 (AutoWashMode) : 0 - AutoWashMode Not Applied / 1 - AutoWashMode Applied

Bit10~31 : Reserved";
BA_ "UserSigValidity" SG_ 2365803012 DATC_Opt_Func 7;
BA_ "Version" SG_ 2365803012 DATC_Opt_Func "24.01.06";
BA_ "GenMsgSendType" BO_ 2193667329 0;
BA_ "GenMsgCycleTime" BO_ 2193667329 50;
BA_ "GenMsgCycleTimeFast" BO_ 2193667329 0;
BA_ "GenMsgNrOfRepetition" BO_ 2193667329 0;
BA_ "VFrameFormat" BO_ 2193667329 1;
BA_ "Description" SG_ 2193667329 EMS_Crc1Val "The data area for CRC calculation is based on the data length (DLC) of the message DB.

The CRC shall be calculated over the entire data block (excluding the CRC bytes) including the user data, alive counter and Data ID



- CRC Polynomial (0x1021) , Initial Value : 0xFFFF, XOR value : 0x0000, Data ID : Message ID + 0xF800 

- The initial value is for CRC calculation and the message should be sent with the calculated result value. 

- The mathematical expression to 16 bit CRC polynomial is given here. G(x) = x16 + x12 + x5 + 1



<For CRC calculation of CAN-FD Msg for HS CAN domain ECUs>



- HS-CAN Messages that routed from CAN-FD domain are using 29 bit Extended CAN ID and splitted into 8 Byte Messages.

(from 1 to 4 Msgs, depending on source CAN-FD Msg¡¯s DLC)

- For splitted CAN-FD Msgs¡¯ CRC calculation, HS CAN ECUs should use source CAN-FD Msg¡¯s original STD ID. 

- The original STD ID can be read from Ext ID¡¯s 4~6th Byte.

Eg. STD 0x6AA : EXT SPLT 0x1A8[6AA]01 / 0x1A8[6AA]02 / 0x1A8[6AA]03 / 0x1A8[6AA]04 

(2~4th splitited Msgs can be omitted depending on source CAN-FD Msg¡¯s DLC)

- Aslo, HS-CAN ECUs should use merged data block (from whole splitted Msg) for CRC calculation.";
BA_ "GenSigStartValue" SG_ 2193667329 EMS_Crc1Val 65535;
BA_ "UserSigValidity" SG_ 2193667329 EMS_Crc1Val 3;
BA_ "RoutingFactor" SG_ 2193667329 EMS_Crc1Val 5;
BA_ "Version" SG_ 2193667329 EMS_Crc1Val "21.09.03";
BA_ "Description" SG_ 2193667329 EMS_AlvCnt1Val "For the first transmission request for a data element the counter shall be initialized with 0 and shall be incremented by 1 for every subsequent send request. 

When the counter reaches the maximum value(0xFF), then it shall restart with 0 for the next send request";
BA_ "UserSigValidity" SG_ 2193667329 EMS_AlvCnt1Val 3;
BA_ "RoutingFactor" SG_ 2193667329 EMS_AlvCnt1Val 5;
BA_ "Version" SG_ 2193667329 EMS_AlvCnt1Val "21.09.03";
BA_ "Description" SG_ 2193667329 ENG_CrctEngTqVal "This signal comprises the actual indicated engine torque (determined by calculation within the engine management system) (lambda control, knock control, catalyst overheating prevention function, temperature influences, TCS, TCU torque intervention etc. being taken into account).



If MSB is 1, this signal is - value.

else, this signal is +value.

0~10bit is used for absolute value.";
BA_ "UserSigValidity" SG_ 2193667329 ENG_CrctEngTqVal 3;
BA_ "RoutingFactor" SG_ 2193667329 ENG_CrctEngTqVal 5;
BA_ "Version" SG_ 2193667329 ENG_CrctEngTqVal "18.01.03";
BA_ "Description" SG_ 2193667329 ENG_StndTqRatioVal "This factor is calculated inside the ECU to express the long-term changes of the engine torque capabilities due to special operating conditions. It takes into consideration mainly the ambient pressure, the ambient air temperature, and the fuel quality. It is defined as follows :



Torque reduction factor = Possible indicated torque for current conditions / Possible indicated torque at standard conditions 



It is used by the TCU to adapt the gearshift strategy.";
BA_ "GenSigStartValue" SG_ 2193667329 ENG_StndTqRatioVal 127;
BA_ "UserSigValidity" SG_ 2193667329 ENG_StndTqRatioVal 3;
BA_ "RoutingFactor" SG_ 2193667329 ENG_StndTqRatioVal 5;
BA_ "Version" SG_ 2193667329 ENG_StndTqRatioVal "17.12.00";
BA_ "Description" SG_ 2193667329 ENG_FrctTqVal "This signal identifies the current engine friction loss torque. It is stored as a function of 'EngClntTempVal' and 'EngSpdVal' (FrctTqVal = f(EngClntTempVal, EngSpdVal)) in terms of an index table.

The index table is corrected depending on the current load under idle conditions.

The signal comprises the following influencing variables:

- Engine friction = f(EngClntTempVal, EngSpdVal, m)

- m= friction coefficient = f(oil,...)

- Charge cycle work

- Valve actuator

- Air conditioner compressor - interference compensation (intermittent)

- Accessories (e.g. water pump, generator, power-steering pump).

The engine friction losses are dominant in conjunction with the following influencing variables.

Peak loads are not included in the calculation.

Consequently, the engine output torque (flywheel torque) is calculated as follows:

TQ = CrctEngTqVal - FrctTqVal



If MSB is 1, this signal is - value.

else, this signal is +value.

0~10bit is used for absolute value.";
BA_ "UserSigValidity" SG_ 2193667329 ENG_FrctTqVal 3;
BA_ "RoutingFactor" SG_ 2193667329 ENG_FrctTqVal 5;
BA_ "Version" SG_ 2193667329 ENG_FrctTqVal "18.01.01";
BA_ "GenMsgSendType" BO_ 2193667330 0;
BA_ "GenMsgCycleTime" BO_ 2193667330 50;
BA_ "GenMsgCycleTimeFast" BO_ 2193667330 0;
BA_ "GenMsgNrOfRepetition" BO_ 2193667330 0;
BA_ "VFrameFormat" BO_ 2193667330 1;
BA_ "Description" SG_ 2193667330 ENG_IndTqVal "1) In cars equipped with gasoline engines with ETC system, the signal TQI is determined on the driver¡¯s demand including cruise control and other functions and corresponds to the theoretical

engine torque. The signal comprises influences, such as the ambient temperature, the atmospheric pressure, knock control, the catalyst overheating prevention function and other corrections but it does not depend on TCS/ESC and TCU interventions realised due to reduction of airflow into the

engine cylinders and due to ignition angle adjustment or injection/cylinder shut off.



TQI = f (drivers demand [with the influence of cruise control and other functions without the

influence of TCS/ESC and TCU interventions], ignition angle [without the influence of TCS/

ESC and TCU interventions])



2) In cars equipped with gasoline engines without ETC system, the signal TQI is determined on the basis of the measured air mass flow (MAF) which corresponds to the theoretical engine. The signal comprises influences, such as the ambient temperature, atmospheric pressure, knock control, the catalyst overheating prevention function and other corrections but it does not depend on TCS/ESC and TCU interventions realised due to ignition angle adjustment or injection/cylinder shut off.



TQI = f (MAF, ignition angle [without the influence of TCS/ESC and TCU interventions])



3) In cars equipped with Diesel engines, the signal TQI is determined on the basis of the

driver¡¯s demanding injected Diesel amount including cruise control and other functions but does not including the influence of TCS/ESC and TCU interventions. It corresponds to the theoretical engine torque and comprises influences such as the ambient temperature, the atmospheric pressure and

other corrections.



TQI = f (injected Diesel amount [without TCS/ESC and TCU interventions])



In case of failures of the load signal (either MAF error or other errors depending on the system configuration), a backup value is generated from specific index tables. The backup value mode is identified by the signal F_SUB_TQI.



There is a specific phase relationship between the signals TQI and F_SUB_TQI.



If MSB is 1, this signal is - value.

else, this signal is +value.

0~10bit is used for absolute value.";
BA_ "UserSigValidity" SG_ 2193667330 ENG_IndTqVal 3;
BA_ "RoutingFactor" SG_ 2193667330 ENG_IndTqVal 5;
BA_ "Version" SG_ 2193667330 ENG_IndTqVal "18.01.01";
BA_ "Description" SG_ 2193667330 ENG_IndTqBVal "TQI_B = f (actual torque + with the influence of TCS/ESC [without the influence of TCU interventions])

In cars equipped with gasoline engines with ETC system, the signal TQI is determined on actual torque.

The signal comprises influences, such as the ambient temperature, the atmospheric pressure, knock control, the catalyst overheating prevention function and other corrections but it does not include TCU interventions realised due to reduction of airflow into the engine cylinders and due to ignition angle adjustment or injection/cylinder shut off. But the signal does include TCS/ESC interventions.



If MSB is 1, this signal is - value.

else, this signal is +value.

0~10bit is used for absolute value.";
BA_ "UserSigValidity" SG_ 2193667330 ENG_IndTqBVal 3;
BA_ "RoutingFactor" SG_ 2193667330 ENG_IndTqBVal 5;
BA_ "Version" SG_ 2193667330 ENG_IndTqBVal "18.01.01";
BA_ "Description" SG_ 2193667330 ENG_EngSpdErrSta "This signal identifies an error on searching for a long tooth or on engine speed sensing.

Note : in some cases a limp-home function can be activated in the ECU (the engine speed signal is then based on the camshaft signal), and the engine may run even if an error is present on the crankshaft signal.



There is a specific phase relationship between the signals EngSpdVal and EngSpdErrSta.";
BA_ "UserSigValidity" SG_ 2193667330 ENG_EngSpdErrSta 3;
BA_ "RoutingFactor" SG_ 2193667330 ENG_EngSpdErrSta 5;
BA_ "Version" SG_ 2193667330 ENG_EngSpdErrSta "17.12.00";
BA_ "Description" SG_ 2193667330 ENG_MafErrSta "This signal indicates error on MAF signal";
BA_ "UserSigValidity" SG_ 2193667330 ENG_MafErrSta 3;
BA_ "RoutingFactor" SG_ 2193667330 ENG_MafErrSta 5;
BA_ "Version" SG_ 2193667330 ENG_MafErrSta "17.12.00";
BA_ "Description" SG_ 2193667330 ENG_EtcLmphModSta "When ETC Mal-function occurred, EMS requests Cluster to indicate limphome mode driving and inform driver to go to AS center as soon as possible.

- In case of ETC malfunction, EMS finishes ETC control so that a vehicle goes to limphome mode driving (Forced idle). Since sudden vehicle speed decrease can cause uncomfortable feeling to driver, EMS needs to indicate limphome mode condition on Cluster to induce driver to go to AS center as soon as possible.";
BA_ "UserSigValidity" SG_ 2193667330 ENG_EtcLmphModSta 3;
BA_ "RoutingFactor" SG_ 2193667330 ENG_EtcLmphModSta 5;
BA_ "Version" SG_ 2193667330 ENG_EtcLmphModSta "17.12.00";
BA_ "Description" SG_ 2193667330 ENG_SpltInjctnSta "The signal Split_Stat identifies the split injection status. 

 * Note This message is for the GDI Delphi engine applied vehicle only.";
BA_ "UserSigValidity" SG_ 2193667330 ENG_SpltInjctnSta 3;
BA_ "RoutingFactor" SG_ 2193667330 ENG_SpltInjctnSta 5;
BA_ "Version" SG_ 2193667330 ENG_SpltInjctnSta "17.11.00";
BA_ "Description" SG_ 2193667330 ENG_MaxAirconTqVal "EMS defines the maximum allowed A/C compressor torque for drivability and engine safety.

This signal offered to A/C ECU unit only in case of the external variable A/C system installed vehicle.";
BA_ "UserSigValidity" SG_ 2193667330 ENG_MaxAirconTqVal 3;
BA_ "RoutingFactor" SG_ 2193667330 ENG_MaxAirconTqVal 5;
BA_ "Version" SG_ 2193667330 ENG_MaxAirconTqVal "17.12.00";
BA_ "Description" SG_ 2193667330 ENG_AirconPrsrSnsrVal "An EMS senses A/C pitot-tube pressure (between compressor & evaporator) directly with APT sensor.

This signal offered to A/C ECU only in case of the external variable A/C system installed vehicle.";
BA_ "UserSigValidity" SG_ 2193667330 ENG_AirconPrsrSnsrVal 3;
BA_ "RoutingFactor" SG_ 2193667330 ENG_AirconPrsrSnsrVal 5;
BA_ "Version" SG_ 2193667330 ENG_AirconPrsrSnsrVal "17.12.00";
BA_ "Description" SG_ 2193667330 ENG_IsgSta "1. ISG Status expressing CAN message divided by CF_EMS_IsgStat and CF_EMS_IsgStat2 

2. In EMS , CF_EMS_IsgStat and CF_EMS_IsgStat2 do not duplicate the output condition

(EX: If CF_EMS_IsgStat is 01h~07h, CF_EMS_IsgStat2 is 00h)



0x0:ISG is not operating Normal engine operating without ISG/0x1:Idle stop is activated Idle is stopped by ECU during driving/0x2:Automatically started by ECU Engine is automatically started by ECU regardless driver¡¯s volition during idle stop because the condition that ISG function to be prohibited is satisfied, for example SOC is too low./0x3:ISG is prohibited Driver prohibits to activate ISG in order to avoid start lag when he met traffic jam for example./0x4:Fault is existing in ISG There is fault, which is related with ISG. So, idle stop is prohibited and engine started automatically if it is idle stop condition. But for the vehicles that use CF_EMS_ISGStat2, the condition for not-activated battery sensor can be ignored./0x5:Idle stop is inhibited by system automatically for safety and  convenient condition related with battery SOC, brake vacuum pressure etc. ISG function check for EOL./0x6:Auto start is deactivated system automatically to keep safety, Such as door open, hood open and seat belt unlock./0x7:If driver shift gear N to D range without braking to make auto starting. (Economy ISG Only)";
BA_ "UserSigValidity" SG_ 2193667330 ENG_IsgSta 3;
BA_ "RoutingFactor" SG_ 2193667330 ENG_IsgSta 5;
BA_ "Version" SG_ 2193667330 ENG_IsgSta "17.12.02";
BA_ "Description" SG_ 2193667330 ENG_OilLvlSta "This signal indicates the replace time of engine oil.";
BA_ "UserSigValidity" SG_ 2193667330 ENG_OilLvlSta 3;
BA_ "RoutingFactor" SG_ 2193667330 ENG_OilLvlSta 5;
BA_ "Version" SG_ 2193667330 ENG_OilLvlSta "17.12.00";
BA_ "GenMsgSendType" BO_ 2193667331 0;
BA_ "GenMsgCycleTime" BO_ 2193667331 50;
BA_ "GenMsgCycleTimeFast" BO_ 2193667331 0;
BA_ "GenMsgNrOfRepetition" BO_ 2193667331 0;
BA_ "VFrameFormat" BO_ 2193667331 1;
BA_ "Description" SG_ 2193667331 ENG_TrgtIdleRpmVal "The stationary target speed depends principally of the engine coolant temperature.

There is a difference between the target speed for manual transmission MT and automatic transmission (AT) in ¡¯neutral¡¯ and AT in ¡¯drive¡¯. 

- Immediately after start the catalyst heating function may increase the target speed 

- The battery charge monitoring increase the target speed.

- For A/C use the target speed may be increased";
BA_ "UserSigValidity" SG_ 2193667331 ENG_TrgtIdleRpmVal 3;
BA_ "RoutingFactor" SG_ 2193667331 ENG_TrgtIdleRpmVal 5;
BA_ "Version" SG_ 2193667331 ENG_TrgtIdleRpmVal "17.12.00";
BA_ "Description" SG_ 2193667331 ENG_GearShftDnDis "This signal represents gear shift down display status. EMS transmits gear shift down status to the cluster.";
BA_ "UserSigValidity" SG_ 2193667331 ENG_GearShftDnDis 3;
BA_ "RoutingFactor" SG_ 2193667331 ENG_GearShftDnDis 5;
BA_ "Version" SG_ 2193667331 ENG_GearShftDnDis "17.12.00";
BA_ "Description" SG_ 2193667331 ENG_DsrGearPosDis "This signal represents desirable gear position of current driving condition.

EMS transmits desirable gear position to the cluster.";
BA_ "UserSigValidity" SG_ 2193667331 ENG_DsrGearPosDis 3;
BA_ "RoutingFactor" SG_ 2193667331 ENG_DsrGearPosDis 5;
BA_ "Version" SG_ 2193667331 ENG_DsrGearPosDis "17.12.00";
BA_ "Description" SG_ 2193667331 ENG_SldFuncSta "This signal indicates that if speed limiter function is active or not.

If the speed limiter function is activated then CF_Ems_SldAct = 1. Although ¡°SLD Main¡± switch is on, if the Speed limiter function is deactivated then CF_Ems_SldAct should be set to ¡®0¡¯.";
BA_ "UserSigValidity" SG_ 2193667331 ENG_SldFuncSta 3;
BA_ "RoutingFactor" SG_ 2193667331 ENG_SldFuncSta 5;
BA_ "Version" SG_ 2193667331 ENG_SldFuncSta "17.12.00";
BA_ "Description" SG_ 2193667331 ENG_SldActnSta "This signal indicates that if positive action of a driver at speed limiter function is active or not. If the positive action is activated then CF_Ems_SldPosAct = 1, which let the current vehicle speed to exceed the limit speed set from a driver.

If kick-down switch isn¡¯t connected to engine ECU directly, ECU can recognize the positive action of a driver from accel pedal position indirectly.

When current vehicle speed exceeds the limit speed, vehicle reaction should be distinguished (e.g. lamp reaction or audio warning signal reaction) depending on the status of ¡°CF_Ems_SldPosAct¡±";
BA_ "UserSigValidity" SG_ 2193667331 ENG_SldActnSta 3;
BA_ "RoutingFactor" SG_ 2193667331 ENG_SldActnSta 5;
BA_ "Version" SG_ 2193667331 ENG_SldActnSta "17.12.00";
BA_ "Description" SG_ 2193667331 ENG_FuelTnkPrsrSta "This signal indicates that if fuel tank is high Pressure or not.

If the fuel tank is in high pressure status then CF_Ems_HPresStat = ¡®1¡¯.

If the fuel tank isn¡¯t in high pressure status then CF_Ems_HPresStat should be set to ¡®0¡¯.";
BA_ "UserSigValidity" SG_ 2193667331 ENG_FuelTnkPrsrSta 3;
BA_ "RoutingFactor" SG_ 2193667331 ENG_FuelTnkPrsrSta 5;
BA_ "Version" SG_ 2193667331 ENG_FuelTnkPrsrSta "17.12.00";
BA_ "Description" SG_ 2193667331 ENG_IsgBzrReq "This signal is for Economy Type ISG. This signal is reminding for preventing sudden starting immediately just after engine restarted or driver shift gear N to D range without braking to make auto starting.

 It transfer first 3 times why if valid one is missing.



In the case of 0x1,

Cluster Action : Buzzer on";
BA_ "UserSigValidity" SG_ 2193667331 ENG_IsgBzrReq 3;
BA_ "RoutingFactor" SG_ 2193667331 ENG_IsgBzrReq 5;
BA_ "Version" SG_ 2193667331 ENG_IsgBzrReq "17.12.00";
BA_ "Description" SG_ 2193667331 ENG_IsgFuelCnsmptDis "This signal is the fuel consumption during Idle stop for display to cluster. 

It transfer first 3 times during 0.001L why if valid one is missing, other valid signals are used for extra signals. So, cluster displays 0.001L at only one among three signals.";
BA_ "UserSigValidity" SG_ 2193667331 ENG_IsgFuelCnsmptDis 3;
BA_ "RoutingFactor" SG_ 2193667331 ENG_IsgFuelCnsmptDis 5;
BA_ "Version" SG_ 2193667331 ENG_IsgFuelCnsmptDis "17.12.00";
BA_ "Description" SG_ 2193667331 ENG_FuelCapOpnSta "This signal indicates that if fuel cap is opened or not.

If the fuel cap is opened then CF_Ems_FCopen = 1.

If the fuel tank isn¡¯t opened then CF_Ems_FCopen should be set to ¡®0¡¯.";
BA_ "UserSigValidity" SG_ 2193667331 ENG_FuelCapOpnSta 3;
BA_ "RoutingFactor" SG_ 2193667331 ENG_FuelCapOpnSta 5;
BA_ "Version" SG_ 2193667331 ENG_FuelCapOpnSta "17.12.00";
BA_ "Description" SG_ 2193667331 ENG_EcoDrvActvSta "This signal indicates if Active Eco Drive function is active or not.

If Active Eco Drive function is active, then CF_Ems_ActEcoAct =1.";
BA_ "UserSigValidity" SG_ 2193667331 ENG_EcoDrvActvSta 3;
BA_ "RoutingFactor" SG_ 2193667331 ENG_EcoDrvActvSta 5;
BA_ "Version" SG_ 2193667331 ENG_EcoDrvActvSta "17.12.00";
BA_ "Description" SG_ 2193667331 ENG_EngRunSta "This signal is indicating normal engine running status. When engine is normal engine running state out of start, the signal turns to 1, otherwise 0 including engine stop & starting phase(cranking).";
BA_ "UserSigValidity" SG_ 2193667331 ENG_EngRunSta 3;
BA_ "RoutingFactor" SG_ 2193667331 ENG_EngRunSta 5;
BA_ "Version" SG_ 2193667331 ENG_EngRunSta "17.12.00";
BA_ "Description" SG_ 2193667331 ENG_Isg2Sta "1. ISG Status CAN message is divided by CF_EMS_IsgStat and CF_EMS_IsgStat2 

2. CF_EMS_IsgStat and CF_EMS_IsgStat2 do not duplicate the output condition

(EX: If CF_EMS_IsgStat2 is 01h~03h, CF_EMS_IsgStat is 00h)";
BA_ "UserSigValidity" SG_ 2193667331 ENG_Isg2Sta 3;
BA_ "RoutingFactor" SG_ 2193667331 ENG_Isg2Sta 5;
BA_ "Version" SG_ 2193667331 ENG_Isg2Sta "17.12.00";
BA_ "Description" SG_ 2193667331 ENG_IgnOnSta "Status of ignition lock.";
BA_ "GenSigStartValue" SG_ 2193667331 ENG_IgnOnSta 1;
BA_ "UserSigValidity" SG_ 2193667331 ENG_IgnOnSta 3;
BA_ "RoutingFactor" SG_ 2193667331 ENG_IgnOnSta 5;
BA_ "Version" SG_ 2193667331 ENG_IgnOnSta "17.12.00";
BA_ "Description" SG_ 2193667331 ENG_Ack4TcsSta "Monitoring of TCS message; the EMS checks whether at least one new message has been transferred within 500 ms, and whether there is no plausibility error in conjunction with a torque intervention. If this case occurs, the bit is set; otherwise it is reset.



Plausibility check - torque intervention:

- Test criteria:

TCS mode, criteria C1:

(TCS_REQ=1) & (TQI_TCS<FFH) & (MSR_C_REQ = 0) & (TQI_MSR = 00H)

MSR mode, criteria C2:

(TCS_REQ=0) & (TQI_TCS=1¡¯s complement of TQI_MSR) & (MSR_C_REQ = 1) & (TQI_MSR > 00H)

No intervention, criteria C3 :

(TCS_REQ=0) & (TQI_TCS=FFH) & (MSR_C_REQ = 0) & (TQI_MSR = 00H)



- Criterion for error setting:

C1 v C2 v C3 ¡Á 1 (none of C1,C2 and C3 is true) for n message transmissions TCS1 (n=10)



- Criterion for remedying an error:

Ignition OFF; transmission is re-started if plausibility is OK for at least one CAN transmission.";
BA_ "UserSigValidity" SG_ 2193667331 ENG_Ack4TcsSta 3;
BA_ "RoutingFactor" SG_ 2193667331 ENG_Ack4TcsSta 5;
BA_ "Version" SG_ 2193667331 ENG_Ack4TcsSta "17.12.00";
BA_ "Description" SG_ 2193667331 ENG_FuelCutOffSta "If the PUC_STAT - bit = 1 then the engine is in fuel cut off state, i.e. e. no injection is applied.";
BA_ "UserSigValidity" SG_ 2193667331 ENG_FuelCutOffSta 3;
BA_ "RoutingFactor" SG_ 2193667331 ENG_FuelCutOffSta 5;
BA_ "Version" SG_ 2193667331 ENG_FuelCutOffSta "17.12.00";
BA_ "Description" SG_ 2193667331 ENG_CrctTqSta "The information TQ_COR_STAT informs the TCS or the TCU whether and to which extent injection and ignition interventions are admitted.



0x0:The desired intervention regarding ignition angle retardation and cylinder shut-off is executed. (Default value)/0x1:The desired intervention regarding ignition angle retardation and cylinder shut-off is executed; however, the requested target torque can not be adjusted precisely (torque steps)/0x2:The torque reduction regarding the ignition angle retardation cannot be completely executed. A cylinder shut-off is not possible at this time. Therefore a remaining torque (as difference between TQI_ASR/GS_REQ and TQI_INTV) is present and cannot be reduced./0x3:Due to a failure detected by a diagnosis function of the engine management system, the desired torque intervention for TCS regarding the ignition angle and cylinder shut-off is no longer executed.The torque intervention is terminated, the engine management system resets the requested engine torque to the TQI value using a ramp.";
BA_ "UserSigValidity" SG_ 2193667331 ENG_CrctTqSta 3;
BA_ "RoutingFactor" SG_ 2193667331 ENG_CrctTqSta 5;
BA_ "Version" SG_ 2193667331 ENG_CrctTqSta "17.12.02";
BA_ "Description" SG_ 2193667331 ENG_AirCompRlySta "The signal RLY_AC identifies the activation of the air conditioner compressor relay.";
BA_ "UserSigValidity" SG_ 2193667331 ENG_AirCompRlySta 3;
BA_ "RoutingFactor" SG_ 2193667331 ENG_AirCompRlySta 5;
BA_ "Version" SG_ 2193667331 ENG_AirCompRlySta "17.12.00";
BA_ "Description" SG_ 2193667331 ENG_LnchCntrlSta "State of Launch Control";
BA_ "UserSigValidity" SG_ 2193667331 ENG_LnchCntrlSta 3;
BA_ "RoutingFactor" SG_ 2193667331 ENG_LnchCntrlSta 5;
BA_ "Version" SG_ 2193667331 ENG_LnchCntrlSta "17.11.00";
BA_ "Description" SG_ 2193667331 ENG_EngSpdVal "This signal is generated by crankshaft segment period measurement (in case of an six-cylinder engine, this corresponds to a crankshaft angle of 120¡Æ) and measured with a resolution of 4 us.

This signal is represented as a 16 bit value.



The signal is no";
BA_ "UserSigValidity" SG_ 2193667331 ENG_EngSpdVal 3;
BA_ "RoutingFactor" SG_ 2193667331 ENG_EngSpdVal 5;
BA_ "Version" SG_ 2193667331 ENG_EngSpdVal "17.12.00";
BA_ "Description" SG_ 2193667331 ENG_GearShftUpDis "This signal represents gear shift up display status. EMS transmits gear shift up status to the cluster.";
BA_ "UserSigValidity" SG_ 2193667331 ENG_GearShftUpDis 3;
BA_ "RoutingFactor" SG_ 2193667331 ENG_GearShftUpDis 5;
BA_ "Version" SG_ 2193667331 ENG_GearShftUpDis "17.12.00";
BA_ "GenMsgSendType" BO_ 2193667332 0;
BA_ "GenMsgCycleTime" BO_ 2193667332 50;
BA_ "GenMsgCycleTimeFast" BO_ 2193667332 0;
BA_ "GenMsgNrOfRepetition" BO_ 2193667332 0;
BA_ "VFrameFormat" BO_ 2193667332 1;
BA_ "Description" SG_ 2193667332 ENG_TrgtFuelPmpPrsrVal "This signal indicates the Target Pressure of Fuel Pump";
BA_ "UserSigValidity" SG_ 2193667332 ENG_TrgtFuelPmpPrsrVal 3;
BA_ "RoutingFactor" SG_ 2193667332 ENG_TrgtFuelPmpPrsrVal 5;
BA_ "Version" SG_ 2193667332 ENG_TrgtFuelPmpPrsrVal "17.12.00";
BA_ "Description" SG_ 2193667332 ENG_VehSpdHiVal "This signal provides the one wheel velocity with resolution of 1 km/h,

and have 9 bits lengh.

In case of failure of sheel speed sensor, the value 1FF is used as error identifier";
BA_ "UserSigValidity" SG_ 2193667332 ENG_VehSpdHiVal 3;
BA_ "RoutingFactor" SG_ 2193667332 ENG_VehSpdHiVal 5;
BA_ "Version" SG_ 2193667332 ENG_VehSpdHiVal "18.01.01";
BA_ "Description" SG_ 2193667332 ENG_EngInhbNCC "This signal indicates the Inhibition of NCC MODE";
BA_ "GenSigStartValue" SG_ 2193667332 ENG_EngInhbNCC 1;
BA_ "UserSigValidity" SG_ 2193667332 ENG_EngInhbNCC 3;
BA_ "RoutingFactor" SG_ 2193667332 ENG_EngInhbNCC 5;
BA_ "Version" SG_ 2193667332 ENG_EngInhbNCC "18.04.02";
BA_ "Description" SG_ 2193667332 ENG_SldSwSta "This signal indicates the status of Speed limiter function.";
BA_ "TimeoutValue" SG_ 2193667332 ENG_SldSwSta "0x0";
BA_ "UserSigValidity" SG_ 2193667332 ENG_SldSwSta 3;
BA_ "RoutingFactor" SG_ 2193667332 ENG_SldSwSta 5;
BA_ "Version" SG_ 2193667332 ENG_SldSwSta "19.12.08";
BA_ "Description" SG_ 2193667332 ENG_SldDrvAlertDisp "If EMS sends the No Sld engaged status or Sld Disengaged status, 

Cluster shall display the status of Sld.";
BA_ "TimeoutValue" SG_ 2193667332 ENG_SldDrvAlertDisp "0x0";
BA_ "UserSigValidity" SG_ 2193667332 ENG_SldDrvAlertDisp 3;
BA_ "RoutingFactor" SG_ 2193667332 ENG_SldDrvAlertDisp 5;
BA_ "Version" SG_ 2193667332 ENG_SldDrvAlertDisp "19.12.08";
BA_ "Description" SG_ 2193667332 ENG_VehSpdLimVal "The vehicle speed which is measured by the EMS has to be sent to CLUSTER. This value is used for limiting speed of EMS. 

EMS limite vehicle speed as this value.";
BA_ "UserSigValidity" SG_ 2193667332 ENG_VehSpdLimVal 3;
BA_ "RoutingFactor" SG_ 2193667332 ENG_VehSpdLimVal 5;
BA_ "Version" SG_ 2193667332 ENG_VehSpdLimVal "18.01.01";
BA_ "Description" SG_ 2193667332 ENG_FuelCnsmptVal "The EMS uses the signal 'FCO' (FUEL CONSUMPTION) to inform other ECUs about the current consumption.";
BA_ "UserSigValidity" SG_ 2193667332 ENG_FuelCnsmptVal 3;
BA_ "RoutingFactor" SG_ 2193667332 ENG_FuelCnsmptVal 5;
BA_ "Version" SG_ 2193667332 ENG_FuelCnsmptVal "17.12.00";
BA_ "GenMsgSendType" BO_ 2244048129 0;
BA_ "GenMsgCycleTime" BO_ 2244048129 100;
BA_ "GenMsgCycleTimeFast" BO_ 2244048129 0;
BA_ "GenMsgNrOfRepetition" BO_ 2244048129 0;
BA_ "VFrameFormat" BO_ 2244048129 1;
BA_ "Description" SG_ 2244048129 ESC_Crc3Val "The data area for CRC calculation is based on the data length (DLC) of the message DB.

The CRC shall be calculated over the entire data block (excluding the CRC bytes) including the user data, alive counter and Data ID



- CRC Polynomial (0x1021) , Initial Value : 0xFFFF, XOR value : 0x0000, Data ID : Message ID + 0xF800 

- The initial value is for CRC calculation and the message should be sent with the calculated result value. 

- The mathematical expression to 16 bit CRC polynomial is given here. G(x) = x16 + x12 + x5 + 1



<For CRC calculation of CAN-FD Msg for HS CAN domain ECUs>



- HS-CAN Messages that routed from CAN-FD domain are using 29 bit Extended CAN ID and splitted into 8 Byte Messages.

(from 1 to 4 Msgs, depending on source CAN-FD Msg¡¯s DLC)

- For splitted CAN-FD Msgs¡¯ CRC calculation, HS CAN ECUs should use source CAN-FD Msg¡¯s original STD ID. 

- The original STD ID can be read from Ext ID¡¯s 4~6th Byte.

Eg. STD 0x6AA : EXT SPLT 0x1A8[6AA]01 / 0x1A8[6AA]02 / 0x1A8[6AA]03 / 0x1A8[6AA]04 

(2~4th splitited Msgs can be omitted depending on source CAN-FD Msg¡¯s DLC)

- Aslo, HS-CAN ECUs should use merged data block (from whole splitted Msg) for CRC calculation.";
BA_ "GenSigStartValue" SG_ 2244048129 ESC_Crc3Val 65535;
BA_ "UserSigValidity" SG_ 2244048129 ESC_Crc3Val 3;
BA_ "RoutingFactor" SG_ 2244048129 ESC_Crc3Val 5;
BA_ "Version" SG_ 2244048129 ESC_Crc3Val "21.09.03";
BA_ "Description" SG_ 2244048129 ESC_AlvCnt3Val "For the first transmission request for a data element the counter shall be initialized with 0 and shall be incremented by 1 for every subsequent send request. 

When the counter reaches the maximum value(0xFF), then it shall restart with 0 for the next send request";
BA_ "UserSigValidity" SG_ 2244048129 ESC_AlvCnt3Val 3;
BA_ "RoutingFactor" SG_ 2244048129 ESC_AlvCnt3Val 5;
BA_ "Version" SG_ 2244048129 ESC_AlvCnt3Val "21.09.03";
BA_ "Description" SG_ 2244048129 SCC_TqIntrvntnVal "The indicated torque command TQI_ACC is the basic control path to the engine power control. This command has the same priority in the torque-structure than the driver¡¯s demand torque. The maximum value of either TQI_ACC or the driver torque is selected fo";
BA_ "UserSigValidity" SG_ 2244048129 SCC_TqIntrvntnVal 3;
BA_ "RoutingFactor" SG_ 2244048129 SCC_TqIntrvntnVal 5;
BA_ "Version" SG_ 2244048129 SCC_TqIntrvntnVal "17.12.00";
BA_ "Description" SG_ 2244048129 ESC_VehAccelVal "The vehicle acceleration ACCEL_REF_ACC displays the feedback signal for the inner acceleration control loop since it is the SCC-internal acceleration command value. In addition this signal is used to calculate the target object acceleration. If the requirements demanded from this signal can¡¯t be guaranteed then SCC must be informed and SCC has to be switched off.

Alternatively SCC may calculate the vehicle acceleration itself. Then the wheel speed vxvTyrexx (or the wheel speed row signals vxvTyreRawxx and the wheel tolerances radTolxx of below diagram) should be

transmitted by TCS or ESC.";
BA_ "UserSigValidity" SG_ 2244048129 ESC_VehAccelVal 3;
BA_ "RoutingFactor" SG_ 2244048129 ESC_VehAccelVal 5;
BA_ "Version" SG_ 2244048129 ESC_VehAccelVal "17.12.00";
BA_ "Description" SG_ 2244048129 ESC_AccelBasisVal "This value is used to initialize the acceleration control when SCC is engaged or after driver override.";
BA_ "UserSigValidity" SG_ 2244048129 ESC_AccelBasisVal 3;
BA_ "RoutingFactor" SG_ 2244048129 ESC_AccelBasisVal 5;
BA_ "Version" SG_ 2244048129 ESC_AccelBasisVal "17.12.00";
BA_ "Description" SG_ 2244048129 PWI_STATE "This signal indicates brake pad wear state. If the brake pad is worn to the designted amount, this signal is used to indicate the alarm on the cluster";
BA_ "UserSigValidity" SG_ 2244048129 PWI_STATE 3;
BA_ "RoutingFactor" SG_ 2244048129 PWI_STATE 5;
BA_ "Version" SG_ 2244048129 PWI_STATE "21.04.02";
BA_ "GenMsgSendType" BO_ 2244048130 0;
BA_ "GenMsgCycleTime" BO_ 2244048130 100;
BA_ "GenMsgCycleTimeFast" BO_ 2244048130 0;
BA_ "GenMsgNrOfRepetition" BO_ 2244048130 0;
BA_ "VFrameFormat" BO_ 2244048130 1;
BA_ "Description" SG_ 2244048130 SCC_OptTyp "This value is used for SCC is equipped or not.

Do not recognize 0x3(Not Coded) as failure.";
BA_ "UserSigValidity" SG_ 2244048130 SCC_OptTyp 3;
BA_ "RoutingFactor" SG_ 2244048130 SCC_OptTyp 5;
BA_ "Version" SG_ 2244048130 SCC_OptTyp "18.12.04";
BA_ "Description" SG_ 2244048130 ESC_BrkLtReq "Flag from TCS which activates the illumination of the brake lights during automatic braking.";
BA_ "UserSigValidity" SG_ 2244048130 ESC_BrkLtReq 3;
BA_ "RoutingFactor" SG_ 2244048130 ESC_BrkLtReq 5;
BA_ "Version" SG_ 2244048130 ESC_BrkLtReq "17.12.00";
BA_ "Description" SG_ 2244048130 ESC_DclEnblReq "This signal enables the deceleration control to accept command values axvCv from SCC. This flag is complementary to the ACC_REQ flag if SCC is in active mode.";
BA_ "UserSigValidity" SG_ 2244048130 ESC_DclEnblReq 3;
BA_ "RoutingFactor" SG_ 2244048130 ESC_DclEnblReq 5;
BA_ "Version" SG_ 2244048130 ESC_DclEnblReq "17.12.00";
BA_ "Description" SG_ 2244048130 ESC_DrvOvrdSta "This signal indicates that acceleration or deceleration value of driver¡¯s requirement is greater than SCC setting value.";
BA_ "UserSigValidity" SG_ 2244048130 ESC_DrvOvrdSta 3;
BA_ "RoutingFactor" SG_ 2244048130 ESC_DrvOvrdSta 5;
BA_ "Version" SG_ 2244048130 ESC_DrvOvrdSta "17.12.00";
BA_ "Description" SG_ 2244048130 ESC_DrvBrkSta "This signal indicates flag from ESC to SCC to indicate the driver braking state";
BA_ "UserSigValidity" SG_ 2244048130 ESC_DrvBrkSta 3;
BA_ "RoutingFactor" SG_ 2244048130 ESC_DrvBrkSta 5;
BA_ "Version" SG_ 2244048130 ESC_DrvBrkSta "17.12.00";
BA_ "Description" SG_ 2244048130 SCC_EnblReq "This signal is set by the safety logic in the TCS/ESC. The safety logic shall monitor the following:

1. A temporary failure in the vehicle does not allow SCC (Brakes are overheated, etc¡¦). 

SCC is disabled reversible.

2. SCC communication failure (timeout";
BA_ "UserSigValidity" SG_ 2244048130 SCC_EnblReq 3;
BA_ "RoutingFactor" SG_ 2244048130 SCC_EnblReq 5;
BA_ "Version" SG_ 2244048130 SCC_EnblReq "17.12.00";
BA_ "Description" SG_ 2244048130 ESC_DrvBrkActvSta "This signal indicates that a driver is pressing the brake pedal or not.";
BA_ "UserSigValidity" SG_ 2244048130 ESC_DrvBrkActvSta 3;
BA_ "RoutingFactor" SG_ 2244048130 ESC_DrvBrkActvSta 5;
BA_ "Version" SG_ 2244048130 ESC_DrvBrkActvSta "17.12.00";
BA_ "Description" SG_ 2244048130 ESC_PrkBrkActvSta "This signal indicates whether the parking brake is activated or not.";
BA_ "UserSigValidity" SG_ 2244048130 ESC_PrkBrkActvSta 3;
BA_ "RoutingFactor" SG_ 2244048130 ESC_PrkBrkActvSta 5;
BA_ "Version" SG_ 2244048130 ESC_PrkBrkActvSta "17.12.00";
BA_ "Description" SG_ 2244048130 ESC_HDP_FltMonSta "ÀÌ ½ÅÈ£´Â IEB (ESC)°¡ HDP Á¦¾î±â(Main/Sub)ÀÇ »óÅÂ¸¦ ¸ð´ÏÅÍ¸µÇÑ °á°úÀÌ´Ù.

This signal is the result of the IEB (ESC) monitoring the state of the HDP controller (Main/Sub).";
BA_ "UserSigValidity" SG_ 2244048130 ESC_HDP_FltMonSta 3;
BA_REL_ "GenSigTimeoutTime" BU_SG_REL_ PSB SG_ 2244048130 ESC_HDP_FltMonSta 1500;
BA_ "RoutingFactor" SG_ 2244048130 ESC_HDP_FltMonSta 5;
BA_ "Version" SG_ 2244048130 ESC_HDP_FltMonSta "21.04.00";
BA_ "Description" SG_ 2244048130 ESC_HDPSpprtSWVer "Software version of IEB/RCU that supports HDP function";
BA_ "UserSigValidity" SG_ 2244048130 ESC_HDPSpprtSWVer 3;
BA_ "RoutingFactor" SG_ 2244048130 ESC_HDPSpprtSWVer 5;
BA_ "Version" SG_ 2244048130 ESC_HDPSpprtSWVer "21.12.07";
BA_ "Description" SG_ 2244048130 FCA_EquipSta "FCA Equipment Status

Do not recognize 0x3(Not Coded) as failure.";
BA_ "UserSigValidity" SG_ 2244048130 FCA_EquipSta 3;
BA_ "RoutingFactor" SG_ 2244048130 FCA_EquipSta 5;
BA_ "Version" SG_ 2244048130 FCA_EquipSta "18.12.04";
BA_ "Description" SG_ 2244048130 FCA_AvlblSta "This signal indicates state signal from ESC to FCA which tells if ESC is 'Available', 'Temporarily not available', 'Permanently not available' or 'FCA Communication Error'.";
BA_ "UserSigValidity" SG_ 2244048130 FCA_AvlblSta 3;
BA_ "RoutingFactor" SG_ 2244048130 FCA_AvlblSta 5;
BA_ "Version" SG_ 2244048130 FCA_AvlblSta "18.02.00";
BA_ "Description" SG_ 2244048130 ESC_FCA_ActvSta "This signal specifies the status of control for FCA control request flag.

(FCA Á¦¾î ¿äÃ»¿¡ ´ëÇÑ Á¦µ¿ Á¦¾î±â ¼öÇà¿©ºÎ È®ÀÎÀ» À§ÇÑ Á¤º¸ ½ÅÈ£)";
BA_ "UserSigValidity" SG_ 2244048130 ESC_FCA_ActvSta 3;
BA_ "RoutingFactor" SG_ 2244048130 ESC_FCA_ActvSta 5;
BA_ "Version" SG_ 2244048130 ESC_FCA_ActvSta "19.11.02";
BA_ "Description" SG_ 2244048130 ESC_DBS_ActvSta "This signal specifies the status of control for DBS flag.

(DBS Á¦¾î ¿äÃ»¿¡ ´ëÇÑ Á¦µ¿ Á¦¾î±â ¼öÇà¿©ºÎ È®ÀÎ À§ÇÑ Á¤º¸ ½ÅÈ£)";
BA_ "UserSigValidity" SG_ 2244048130 ESC_DBS_ActvSta 3;
BA_ "RoutingFactor" SG_ 2244048130 ESC_DBS_ActvSta 5;
BA_ "Version" SG_ 2244048130 ESC_DBS_ActvSta "19.11.02";
BA_ "Description" SG_ 2244048130 SCC_TqReq "When it is set, the signal indicates that ESC requests engine torque control for SCC. When the signal is set, EMS should not conduct fuel-cut off control unless it is required to prevent the damage of the engine and the related components.";
BA_ "UserSigValidity" SG_ 2244048130 SCC_TqReq 3;
BA_ "RoutingFactor" SG_ 2244048130 SCC_TqReq 5;
BA_ "Version" SG_ 2244048130 SCC_TqReq "17.12.00";
BA_ "Description" SG_ 2244048130 ESC_HDP_EgSta "This signal is the information which of the HDP controllers (Main/Sub) the IEB (ESC)/RCU is engaged.";
BA_ "UserSigValidity" SG_ 2244048130 ESC_HDP_EgSta 0;
BA_REL_ "GenSigTimeoutTime" BU_SG_REL_ PSB SG_ 2244048130 ESC_HDP_EgSta 1500;
BA_ "RoutingFactor" SG_ 2244048130 ESC_HDP_EgSta 5;
BA_ "Version" SG_ 2244048130 ESC_HDP_EgSta "22.05.03";
BA_ "Description" SG_ 2244048130 ESC_HDP_EnblReq "This signal is a fault state of the IEB (ESC) for the HDP function.";
BA_ "UserSigValidity" SG_ 2244048130 ESC_HDP_EnblReq 3;
BA_ "RoutingFactor" SG_ 2244048130 ESC_HDP_EnblReq 5;
BA_ "Version" SG_ 2244048130 ESC_HDP_EnblReq "21.12.07";
BA_ "Description" SG_ 2244048130 CSC_Sta "This signal indicates whether the crosswind stability control(CSC) is active.";
BA_ "UserSigValidity" SG_ 2244048130 CSC_Sta 3;
BA_ "RoutingFactor" SG_ 2244048130 CSC_Sta 5;
BA_ "Version" SG_ 2244048130 CSC_Sta "22.01.06";
BA_ "Description" SG_ 2244048130 CSC_WrngSta "This signal is used to display warning message on cluster and hud about crosswind stability control(CSC) function.";
BA_ "UserSigValidity" SG_ 2244048130 CSC_WrngSta 3;
BA_ "RoutingFactor" SG_ 2244048130 CSC_WrngSta 5;
BA_ "Version" SG_ 2244048130 CSC_WrngSta "23.07.02";
BA_ "Description" SG_ 2244048130 ESC_BrkdFltStndstill "The signal indicates state when vehicle is braked, flatland and standstill";
BA_ "UserSigValidity" SG_ 2244048130 ESC_BrkdFltStndstill 3;
BA_ "RoutingFactor" SG_ 2244048130 ESC_BrkdFltStndstill 5;
BA_ "Version" SG_ 2244048130 ESC_BrkdFltStndstill "20.12.04";
BA_ "Description" SG_ 2244048130 SCC_ReqLimSta "Due to limitaion of the actuators the acceleration or deceleration request from SCC can not be processed or only partly. 



Examples:

1. SCC is requesting more acceleration than the engine can deliver.

2. SCC is requesting deceleration on a low ¥ì surface.";
BA_ "UserSigValidity" SG_ 2244048130 SCC_ReqLimSta 3;
BA_ "RoutingFactor" SG_ 2244048130 SCC_ReqLimSta 5;
BA_ "Version" SG_ 2244048130 SCC_ReqLimSta "17.12.00";
BA_ "Description" SG_ 2244048130 ESC_StdStillVal "If an ESC uses active wheel speed sensors, wheel speeds down to 0 Km/h can be measured. And at 0 Km/h a StandStill flag is set in the ESC. This signal is used in the offset determination of the yaw rate and shall indicate that the vehicle has come to a complete stop.";
BA_ "UserSigValidity" SG_ 2244048130 ESC_StdStillVal 3;
BA_ "RoutingFactor" SG_ 2244048130 ESC_StdStillVal 5;
BA_ "Version" SG_ 2244048130 ESC_StdStillVal "17.12.00";
BA_ "GenMsgSendType" BO_ 2244048131 0;
BA_ "GenMsgCycleTime" BO_ 2244048131 100;
BA_ "GenMsgCycleTimeFast" BO_ 2244048131 0;
BA_ "GenMsgNrOfRepetition" BO_ 2244048131 0;
BA_ "VFrameFormat" BO_ 2244048131 1;
BA_ "Description" SG_ 2244048131 ESC_RccaSta "RCCA Brake Function Status";
BA_ "UserSigValidity" SG_ 2244048131 ESC_RccaSta 3;
BA_ "RoutingFactor" SG_ 2244048131 ESC_RccaSta 5;
BA_ "Version" SG_ 2244048131 ESC_RccaSta "17.12.00";
BA_ "Description" SG_ 2244048131 ESC_RspaCanFlFlag "This signal indicates RSPA CAN failure value.

E.g. Timeout, CRC error, Alive counter error, out of range signal value¡¦";
BA_ "UserSigValidity" SG_ 2244048131 ESC_RspaCanFlFlag 3;
BA_ "RoutingFactor" SG_ 2244048131 ESC_RspaCanFlFlag 5;
BA_ "Version" SG_ 2244048131 ESC_RspaCanFlFlag "17.12.00";
BA_ "Description" SG_ 2244048131 ESC_RspaDclActv "This signal indicates the additional braking control is activated for RSPA.

ESC activate additional deceleration to minimize vehicle speed overshoot.";
BA_ "UserSigValidity" SG_ 2244048131 ESC_RspaDclActv 3;
BA_ "RoutingFactor" SG_ 2244048131 ESC_RspaDclActv 5;
BA_ "Version" SG_ 2244048131 ESC_RspaDclActv "17.12.00";
BA_ "Description" SG_ 2244048131 ESC_RspaStandStill "This signal indicates confirmation for standstill of the vehicle.";
BA_ "UserSigValidity" SG_ 2244048131 ESC_RspaStandStill 3;
BA_ "RoutingFactor" SG_ 2244048131 ESC_RspaStandStill 5;
BA_ "Version" SG_ 2244048131 ESC_RspaStandStill "17.12.00";
BA_ "Description" SG_ 2244048131 ESC_PcaSta "PCA-R Brake Status";
BA_ "UserSigValidity" SG_ 2244048131 ESC_PcaSta 3;
BA_ "RoutingFactor" SG_ 2244048131 ESC_PcaSta 5;
BA_ "Version" SG_ 2244048131 ESC_PcaSta "17.12.06";
BA_ "Description" SG_ 2244048131 ESC_LdOpn "This signal indicates the command for eLD lock/unlock mode.";
BA_ "UserSigValidity" SG_ 2244048131 ESC_LdOpn 3;
BA_ "RoutingFactor" SG_ 2244048131 ESC_LdOpn 5;
BA_ "Version" SG_ 2244048131 ESC_LdOpn "23.04.07";
BA_ "Description" SG_ 2244048131 MCB_ReqBrkAck "This signal is about communication with ACU. It is changed with ACU_ReqBrk_By_PCB signal value.

If ESC receive 0x1 or 0x2 value of ACU_ReqBrk_By_PCB, signal value of MCB_ReqBrkAck change to 0x1.

If ESC receive 0x0 value of ACU_ReqBrk_By_PCB, signal value of MCB_ReqBrkAck change to 0x0.";
BA_ "UserSigValidity" SG_ 2244048131 MCB_ReqBrkAck 3;
BA_ "RoutingFactor" SG_ 2244048131 MCB_ReqBrkAck 5;
BA_ "Version" SG_ 2244048131 MCB_ReqBrkAck "18.12.05";
BA_ "Description" SG_ 2244048131 MCB_CtlSta "This signal indicate MCB activation status.";
BA_ "UserSigValidity" SG_ 2244048131 MCB_CtlSta 3;
BA_ "RoutingFactor" SG_ 2244048131 MCB_CtlSta 5;
BA_ "Version" SG_ 2244048131 MCB_CtlSta "19.05.02";
BA_ "Description" SG_ 2244048131 MCB_DefSta "This signal indicate MCB defective status.";
BA_ "UserSigValidity" SG_ 2244048131 MCB_DefSta 3;
BA_ "RoutingFactor" SG_ 2244048131 MCB_DefSta 5;
BA_ "Version" SG_ 2244048131 MCB_DefSta "19.05.02";
BA_ "Description" SG_ 2244048131 ESC_DiffBrkFuncSta "This is ESC status for Differential brake function.";
BA_ "UserSigValidity" SG_ 2244048131 ESC_DiffBrkFuncSta 3;
BA_ "RoutingFactor" SG_ 2244048131 ESC_DiffBrkFuncSta 5;
BA_ "Version" SG_ 2244048131 ESC_DiffBrkFuncSta "17.12.00";
BA_ "Description" SG_ 2244048131 ESC_LsdLimMod "This signal indicates the request for eLSD torque limit mode.

0x0:Maximum limitation mode

0x1:Minimum limitation mode";
BA_ "UserSigValidity" SG_ 2244048131 ESC_LsdLimMod 3;
BA_ "RoutingFactor" SG_ 2244048131 ESC_LsdLimMod 5;
BA_ "Version" SG_ 2244048131 ESC_LsdLimMod "18.05.02";
BA_ "Description" SG_ 2244048131 ESC_LsdOpn "This signal indicates the command for eLSD clutch open mode.";
BA_ "UserSigValidity" SG_ 2244048131 ESC_LsdOpn 3;
BA_ "RoutingFactor" SG_ 2244048131 ESC_LsdOpn 5;
BA_ "Version" SG_ 2244048131 ESC_LsdOpn "20.08.05";
BA_ "Description" SG_ 2244048131 ESC_LsdTqLim "This signal indicates the request for the value of the torquel limit of eLSD.

0xFFFF : Error";
BA_ "GenSigStartValue" SG_ 2244048131 ESC_LsdTqLim 64255;
BA_ "UserSigValidity" SG_ 2244048131 ESC_LsdTqLim 3;
BA_ "RoutingFactor" SG_ 2244048131 ESC_LsdTqLim 5;
BA_ "Version" SG_ 2244048131 ESC_LsdTqLim "18.05.02";
BA_ "Description" SG_ 2244048131 ESC_BcaRPlusSta "BCA-R+ Brake Function Status";
BA_ "UserSigValidity" SG_ 2244048131 ESC_BcaRPlusSta 3;
BA_ "RoutingFactor" SG_ 2244048131 ESC_BcaRPlusSta 5;
BA_ "Version" SG_ 2244048131 ESC_BcaRPlusSta "17.12.07";
BA_ "Description" SG_ 2244048131 ESC_RspaSta "This signal indicates RSPA assistant control mode of ESC";
BA_ "GenSigStartValue" SG_ 2244048131 ESC_RspaSta 1;
BA_ "UserSigValidity" SG_ 2244048131 ESC_RspaSta 3;
BA_ "RoutingFactor" SG_ 2244048131 ESC_RspaSta 5;
BA_ "Version" SG_ 2244048131 ESC_RspaSta "17.12.00";
BA_ "GenMsgSendType" BO_ 1189 0;
BA_ "GenMsgStartDelayTime" BO_ 1189 80;
BA_ "GenSigSendType" SG_ 1189 C_RLTiltUpSw_HU 4;
BA_ "UserSigValidity" SG_ 1189 C_RLTiltUpSw_HU 0;
BA_REL_ "GenSigTimeoutTime" BU_SG_REL_ GW_APSU SG_ 1189 C_RLTiltUpSw_HU 1500;
BA_REL_ "GenSigTimeoutTime" BU_SG_REL_ GW_RLPSU SG_ 1189 C_RLTiltUpSw_HU 1500;
BA_REL_ "GenSigTimeoutTime" BU_SG_REL_ GW_RRPSU SG_ 1189 C_RLTiltUpSw_HU 1500;
BA_ "Version" SG_ 1189 C_RLTiltUpSw_HU "22.06.01";
BA_ "GenSigSendType" SG_ 1189 C_RRTiltDownSw_HU 4;
BA_ "UserSigValidity" SG_ 1189 C_RRTiltDownSw_HU 0;
BA_REL_ "GenSigTimeoutTime" BU_SG_REL_ GW_APSU SG_ 1189 C_RRTiltDownSw_HU 1500;
BA_REL_ "GenSigTimeoutTime" BU_SG_REL_ GW_RRPSU SG_ 1189 C_RRTiltDownSw_HU 1500;
BA_ "Version" SG_ 1189 C_RRTiltDownSw_HU "22.06.01";
BA_ "GenSigSendType" SG_ 1189 C_RRTiltUpSw_HU 4;
BA_ "UserSigValidity" SG_ 1189 C_RRTiltUpSw_HU 0;
BA_REL_ "GenSigTimeoutTime" BU_SG_REL_ GW_APSU SG_ 1189 C_RRTiltUpSw_HU 1500;
BA_REL_ "GenSigTimeoutTime" BU_SG_REL_ GW_RRPSU SG_ 1189 C_RRTiltUpSw_HU 1500;
BA_ "Version" SG_ 1189 C_RRTiltUpSw_HU "22.06.01";
BA_ "GenSigSendType" SG_ 1189 C_RLRclBwdSw_HU 4;
BA_ "UserSigValidity" SG_ 1189 C_RLRclBwdSw_HU 0;
BA_REL_ "GenSigTimeoutTime" BU_SG_REL_ GW_APSU SG_ 1189 C_RLRclBwdSw_HU 1500;
BA_REL_ "GenSigTimeoutTime" BU_SG_REL_ GW_RLPSU SG_ 1189 C_RLRclBwdSw_HU 1500;
BA_REL_ "GenSigTimeoutTime" BU_SG_REL_ GW_RRPSU SG_ 1189 C_RLRclBwdSw_HU 1500;
BA_ "Version" SG_ 1189 C_RLRclBwdSw_HU "22.06.01";
BA_ "GenSigSendType" SG_ 1189 C_RLRclFwdSw_HU 4;
BA_ "UserSigValidity" SG_ 1189 C_RLRclFwdSw_HU 0;
BA_REL_ "GenSigTimeoutTime" BU_SG_REL_ GW_APSU SG_ 1189 C_RLRclFwdSw_HU 1500;
BA_REL_ "GenSigTimeoutTime" BU_SG_REL_ GW_RLPSU SG_ 1189 C_RLRclFwdSw_HU 1500;
BA_REL_ "GenSigTimeoutTime" BU_SG_REL_ GW_RRPSU SG_ 1189 C_RLRclFwdSw_HU 1500;
BA_ "Version" SG_ 1189 C_RLRclFwdSw_HU "22.06.01";
BA_ "GenSigSendType" SG_ 1189 C_RLFldSw_HU 4;
BA_ "UserSigValidity" SG_ 1189 C_RLFldSw_HU 0;
BA_REL_ "GenSigTimeoutTime" BU_SG_REL_ GW_RLPSU SG_ 1189 C_RLFldSw_HU 1500;
BA_ "Version" SG_ 1189 C_RLFldSw_HU "22.06.01";
BA_ "GenSigSendType" SG_ 1189 C_RRRclBwdSw_HU 4;
BA_ "UserSigValidity" SG_ 1189 C_RRRclBwdSw_HU 0;
BA_REL_ "GenSigTimeoutTime" BU_SG_REL_ GW_APSU SG_ 1189 C_RRRclBwdSw_HU 1500;
BA_REL_ "GenSigTimeoutTime" BU_SG_REL_ GW_RRPSU SG_ 1189 C_RRRclBwdSw_HU 1500;
BA_ "Version" SG_ 1189 C_RRRclBwdSw_HU "22.06.01";
BA_ "GenSigSendType" SG_ 1189 C_RRRclFwdSw_HU 4;
BA_ "UserSigValidity" SG_ 1189 C_RRRclFwdSw_HU 0;
BA_REL_ "GenSigTimeoutTime" BU_SG_REL_ GW_APSU SG_ 1189 C_RRRclFwdSw_HU 1500;
BA_REL_ "GenSigTimeoutTime" BU_SG_REL_ GW_RRPSU SG_ 1189 C_RRRclFwdSw_HU 1500;
BA_ "Version" SG_ 1189 C_RRRclFwdSw_HU "22.06.01";
BA_ "GenSigSendType" SG_ 1189 C_TLHrestFldSw_HU 4;
BA_ "UserSigValidity" SG_ 1189 C_TLHrestFldSw_HU 0;
BA_REL_ "GenSigTimeoutTime" BU_SG_REL_ PFSU SG_ 1189 C_TLHrestFldSw_HU 1500;
BA_ "Version" SG_ 1189 C_TLHrestFldSw_HU "22.06.01";
BA_ "GenSigSendType" SG_ 1189 C_TRHrestFldSw_HU 4;
BA_ "UserSigValidity" SG_ 1189 C_TRHrestFldSw_HU 0;
BA_REL_ "GenSigTimeoutTime" BU_SG_REL_ PFSU SG_ 1189 C_TRHrestFldSw_HU 1500;
BA_ "Version" SG_ 1189 C_TRHrestFldSw_HU "22.06.01";
BA_ "GenSigSendType" SG_ 1189 C_TLFldSw_HU 4;
BA_ "UserSigValidity" SG_ 1189 C_TLFldSw_HU 0;
BA_REL_ "GenSigTimeoutTime" BU_SG_REL_ PFSU SG_ 1189 C_TLFldSw_HU 1500;
BA_ "Version" SG_ 1189 C_TLFldSw_HU "22.06.01";
BA_ "GenSigSendType" SG_ 1189 C_TRFldSw_HU 4;
BA_ "UserSigValidity" SG_ 1189 C_TRFldSw_HU 0;
BA_REL_ "GenSigTimeoutTime" BU_SG_REL_ PFSU SG_ 1189 C_TRFldSw_HU 1500;
BA_ "Version" SG_ 1189 C_TRFldSw_HU "22.06.01";
BA_ "GenSigSendType" SG_ 1189 C_RRFldSw_HU 4;
BA_ "UserSigValidity" SG_ 1189 C_RRFldSw_HU 0;
BA_REL_ "GenSigTimeoutTime" BU_SG_REL_ GW_RRPSU SG_ 1189 C_RRFldSw_HU 1500;
BA_ "Version" SG_ 1189 C_RRFldSw_HU "22.06.01";
BA_ "GenSigSendType" SG_ 1189 C_RLTiltDownSw_HU 4;
BA_ "UserSigValidity" SG_ 1189 C_RLTiltDownSw_HU 0;
BA_REL_ "GenSigTimeoutTime" BU_SG_REL_ GW_APSU SG_ 1189 C_RLTiltDownSw_HU 1500;
BA_REL_ "GenSigTimeoutTime" BU_SG_REL_ GW_RLPSU SG_ 1189 C_RLTiltDownSw_HU 1500;
BA_REL_ "GenSigTimeoutTime" BU_SG_REL_ GW_RRPSU SG_ 1189 C_RLTiltDownSw_HU 1500;
BA_ "Version" SG_ 1189 C_RLTiltDownSw_HU "22.06.01";
BA_ "GenMsgCycleTime" BO_ 1185 0;
BA_ "GenSigSendType" SG_ 1185 C_AstWindowCmdAVN 4;
BA_ "GenSigStartValue" SG_ 1185 C_AstWindowCmdAVN 15;
BA_ "UserSigValidity" SG_ 1185 C_AstWindowCmdAVN 0;
BA_ "Version" SG_ 1185 C_AstWindowCmdAVN "19.11.05";
BA_ "Description" SG_ 1185 C_RrDefoggerCmdAVN "18.08.09_";
BA_ "GenSigSendType" SG_ 1185 C_RrDefoggerCmdAVN 4;
BA_ "GenSigStartValue" SG_ 1185 C_RrDefoggerCmdAVN 3;
BA_ "UserSigValidity" SG_ 1185 C_RrDefoggerCmdAVN 3;
BA_ "Version" SG_ 1185 C_RrDefoggerCmdAVN "18.09.02";
BA_ "Description" SG_ 1185 C_RrBlindCmdAVN "Rear sunroof control signal(blind)";
BA_ "GenSigSendType" SG_ 1185 C_RrBlindCmdAVN 4;
BA_ "GenSigStartValue" SG_ 1185 C_RrBlindCmdAVN 3;
BA_ "UserSigValidity" SG_ 1185 C_RrBlindCmdAVN 3;
BA_REL_ "GenSigTimeoutTime" BU_SG_REL_ RCM SG_ 1185 C_RrBlindCmdAVN 0;
BA_ "Version" SG_ 1185 C_RrBlindCmdAVN "22.02.04";
BA_ "Description" SG_ 1185 C_RrGlassCmdAVN "Rear sunroof control signal(glass)";
BA_ "GenSigSendType" SG_ 1185 C_RrGlassCmdAVN 4;
BA_ "GenSigStartValue" SG_ 1185 C_RrGlassCmdAVN 3;
BA_ "UserSigValidity" SG_ 1185 C_RrGlassCmdAVN 3;
BA_REL_ "GenSigTimeoutTime" BU_SG_REL_ RCM SG_ 1185 C_RrGlassCmdAVN 0;
BA_ "Version" SG_ 1185 C_RrGlassCmdAVN "22.02.04";
BA_ "GenSigSendType" SG_ 1185 C_RRWindowCmdAVN 4;
BA_ "GenSigStartValue" SG_ 1185 C_RRWindowCmdAVN 15;
BA_ "UserSigValidity" SG_ 1185 C_RRWindowCmdAVN 0;
BA_ "Version" SG_ 1185 C_RRWindowCmdAVN "19.11.05";
BA_ "GenSigSendType" SG_ 1185 C_RLWindowCmdAVN 4;
BA_ "GenSigStartValue" SG_ 1185 C_RLWindowCmdAVN 15;
BA_ "UserSigValidity" SG_ 1185 C_RLWindowCmdAVN 0;
BA_ "Version" SG_ 1185 C_RLWindowCmdAVN "19.11.05";
BA_ "Description" SG_ 1185 C_BlindCmdAVN "18.08.09_";
BA_ "GenSigSendType" SG_ 1185 C_BlindCmdAVN 4;
BA_ "GenSigStartValue" SG_ 1185 C_BlindCmdAVN 7;
BA_ "UserSigValidity" SG_ 1185 C_BlindCmdAVN 1;
BA_REL_ "GenSigTimeoutTime" BU_SG_REL_ RCM SG_ 1185 C_BlindCmdAVN 0;
BA_ "Version" SG_ 1185 C_BlindCmdAVN "18.09.02";
BA_ "Description" SG_ 1185 C_GlassCmdAVN "18.08.09_";
BA_ "GenSigSendType" SG_ 1185 C_GlassCmdAVN 4;
BA_ "GenSigStartValue" SG_ 1185 C_GlassCmdAVN 7;
BA_ "UserSigValidity" SG_ 1185 C_GlassCmdAVN 1;
BA_REL_ "GenSigTimeoutTime" BU_SG_REL_ RCM SG_ 1185 C_GlassCmdAVN 0;
BA_ "Version" SG_ 1185 C_GlassCmdAVN "18.09.02";
BA_ "GenSigSendType" SG_ 1185 C_DrvWindowCmdAVN 4;
BA_ "GenSigStartValue" SG_ 1185 C_DrvWindowCmdAVN 15;
BA_ "UserSigValidity" SG_ 1185 C_DrvWindowCmdAVN 0;
BA_ "Version" SG_ 1185 C_DrvWindowCmdAVN "19.11.05";
BA_ "Description" SG_ 1185 C_PTGCNTLCmdAVN "18.08.09_";
BA_ "GenSigSendType" SG_ 1185 C_PTGCNTLCmdAVN 4;
BA_ "GenSigStartValue" SG_ 1185 C_PTGCNTLCmdAVN 3;
BA_ "UserSigValidity" SG_ 1185 C_PTGCNTLCmdAVN 3;
BA_ "Version" SG_ 1185 C_PTGCNTLCmdAVN "18.09.02";
BA_ "GenMsgCycleTime" BO_ 1193 0;
BA_ "Description" SG_ 1193 C_PTGMNValueSet "18.08.09_";
BA_ "GenSigSendType" SG_ 1193 C_PTGMNValueSet 4;
BA_ "UserSigValidity" SG_ 1193 C_PTGMNValueSet 3;
BA_ "Version" SG_ 1193 C_PTGMNValueSet "18.09.04";
BA_ "Description" SG_ 1193 CF_AVN_PSMNValueSet "18.08.09_";
BA_ "GenSigSendType" SG_ 1193 CF_AVN_PSMNValueSet 4;
BA_ "UserSigValidity" SG_ 1193 CF_AVN_PSMNValueSet 3;
BA_REL_ "GenSigTimeoutTime" BU_SG_REL_ GW_DPSU SG_ 1193 CF_AVN_PSMNValueSet 0;
BA_ "Version" SG_ 1193 CF_AVN_PSMNValueSet "18.09.04";
BA_ "Description" SG_ 1193 C_HfreeTrunkTgNValueSet "18.08.09_";
BA_ "GenSigSendType" SG_ 1193 C_HfreeTrunkTgNValueSet 4;
BA_ "UserSigValidity" SG_ 1193 C_HfreeTrunkTgNValueSet 3;
BA_ "Version" SG_ 1193 C_HfreeTrunkTgNValueSet "18.09.04";
BA_ "Description" SG_ 1193 CF_AVN_TrfChgSet "18.08.09_";
BA_ "GenSigSendType" SG_ 1193 CF_AVN_TrfChgSet 4;
BA_ "UserSigValidity" SG_ 1193 CF_AVN_TrfChgSet 3;
BA_ "Version" SG_ 1193 CF_AVN_TrfChgSet "18.09.04";
BA_ "Description" SG_ 1193 CF_AVN_SCMNValueSet "18.08.09_";
BA_ "GenSigSendType" SG_ 1193 CF_AVN_SCMNValueSet 4;
BA_ "UserSigValidity" SG_ 1193 CF_AVN_SCMNValueSet 3;
BA_ "Version" SG_ 1193 CF_AVN_SCMNValueSet "18.09.04";
BA_ "Description" SG_ 1193 CF_AVN_ADrUNValueSet "18.08.09_";
BA_ "GenSigSendType" SG_ 1193 CF_AVN_ADrUNValueSet 4;
BA_ "UserSigValidity" SG_ 1193 CF_AVN_ADrUNValueSet 3;
BA_ "Version" SG_ 1193 CF_AVN_ADrUNValueSet "18.09.04";
BA_ "Description" SG_ 1193 CF_AVN_OTTurnNValueSet "18.08.09_";
BA_ "GenSigSendType" SG_ 1193 CF_AVN_OTTurnNValueSet 4;
BA_ "UserSigValidity" SG_ 1193 CF_AVN_OTTurnNValueSet 3;
BA_ "Version" SG_ 1193 CF_AVN_OTTurnNValueSet "18.09.04";
BA_ "Description" SG_ 1193 CF_Gway_WPCNValueSet "18.08.09_";
BA_ "GenSigSendType" SG_ 1193 CF_Gway_WPCNValueSet 4;
BA_ "UserSigValidity" SG_ 1193 CF_Gway_WPCNValueSet 3;
BA_REL_ "GenSigTimeoutTime" BU_SG_REL_ WPC SG_ 1193 CF_Gway_WPCNValueSet 0;
BA_REL_ "GenSigTimeoutTime" BU_SG_REL_ WPC2 SG_ 1193 CF_Gway_WPCNValueSet 0;
BA_ "Version" SG_ 1193 CF_Gway_WPCNValueSet "18.09.04";
BA_ "Description" SG_ 1193 C_AVN_RearWiperNValueSet "18.08.09_";
BA_ "GenSigSendType" SG_ 1193 C_AVN_RearWiperNValueSet 4;
BA_ "UserSigValidity" SG_ 1193 C_AVN_RearWiperNValueSet 3;
BA_ "Version" SG_ 1193 C_AVN_RearWiperNValueSet "18.09.04";
BA_ "Description" SG_ 1193 C_UnlockWelocomeNValueSet "18.08.09_";
BA_ "GenSigSendType" SG_ 1193 C_UnlockWelocomeNValueSet 4;
BA_ "UserSigValidity" SG_ 1193 C_UnlockWelocomeNValueSet 3;
BA_ "Version" SG_ 1193 C_UnlockWelocomeNValueSet "18.09.04";
BA_ "Description" SG_ 1193 C_SmartWelocomeNValueSet "18.08.09_";
BA_ "GenSigSendType" SG_ 1193 C_SmartWelocomeNValueSet 4;
BA_ "UserSigValidity" SG_ 1193 C_SmartWelocomeNValueSet 3;
BA_ "Version" SG_ 1193 C_SmartWelocomeNValueSet "18.09.04";
BA_ "Description" SG_ 1193 CF_AVN_PTGSpeedNValueSet "18.08.09_";
BA_ "GenSigSendType" SG_ 1193 CF_AVN_PTGSpeedNValueSet 4;
BA_ "UserSigValidity" SG_ 1193 CF_AVN_PTGSpeedNValueSet 3;
BA_ "Version" SG_ 1193 CF_AVN_PTGSpeedNValueSet "18.09.04";
BA_ "Description" SG_ 1193 CR_Datc_DRSeatWheel_USM_Set "18.08.09_";
BA_ "GenSigSendType" SG_ 1193 CR_Datc_DRSeatWheel_USM_Set 4;
BA_ "UserSigValidity" SG_ 1193 CR_Datc_DRSeatWheel_USM_Set 3;
BA_ "Version" SG_ 1193 CR_Datc_DRSeatWheel_USM_Set "18.09.04";
BA_ "Description" SG_ 1193 CF_AVN_TTUnlockNValueSet "18.08.09_";
BA_ "GenSigSendType" SG_ 1193 CF_AVN_TTUnlockNValueSet 4;
BA_ "GenSigStartValue" SG_ 1193 CF_AVN_TTUnlockNValueSet 3;
BA_ "UserSigValidity" SG_ 1193 CF_AVN_TTUnlockNValueSet 3;
BA_ "Version" SG_ 1193 CF_AVN_TTUnlockNValueSet "18.09.04";
BA_ "Description" SG_ 1193 CF_Gway_RWPCNValueSet "18.08.09_";
BA_ "GenSigSendType" SG_ 1193 CF_Gway_RWPCNValueSet 4;
BA_ "UserSigValidity" SG_ 1193 CF_Gway_RWPCNValueSet 3;
BA_REL_ "GenSigTimeoutTime" BU_SG_REL_ RWPC SG_ 1193 CF_Gway_RWPCNValueSet 0;
BA_ "Version" SG_ 1193 CF_Gway_RWPCNValueSet "18.09.04";
BA_ "Description" SG_ 1193 CF_Avn_HAPTICWARNINGNValueSet "18.11.09_";
BA_ "GenSigSendType" SG_ 1193 CF_Avn_HAPTICWARNINGNValueSet 4;
BA_ "UserSigValidity" SG_ 1193 CF_Avn_HAPTICWARNINGNValueSet 3;
BA_ "Version" SG_ 1193 CF_Avn_HAPTICWARNINGNValueSet "18.12.01";
BA_ "Description" SG_ 1193 CR_Datc_DRSeatHeat_USM_Set "18.08.09_";
BA_ "GenSigSendType" SG_ 1193 CR_Datc_DRSeatHeat_USM_Set 4;
BA_ "UserSigValidity" SG_ 1193 CR_Datc_DRSeatHeat_USM_Set 3;
BA_ "Version" SG_ 1193 CR_Datc_DRSeatHeat_USM_Set "18.09.04";
BA_ "Description" SG_ 1193 C_WALNValueSet "18.08.09_";
BA_ "GenSigSendType" SG_ 1193 C_WALNValueSet 4;
BA_ "UserSigValidity" SG_ 1193 C_WALNValueSet 3;
BA_ "Version" SG_ 1193 C_WALNValueSet "18.09.04";
BA_ "Description" SG_ 1193 C_ApprUnlockNValue "18.08.09_";
BA_ "GenSigSendType" SG_ 1193 C_ApprUnlockNValue 4;
BA_ "UserSigValidity" SG_ 1193 C_ApprUnlockNValue 3;
BA_ "Version" SG_ 1193 C_ApprUnlockNValue "18.09.04";
BA_ "Description" SG_ 1193 CF_AVN_EscortHLNValueSet "18.08.09_";
BA_ "GenSigSendType" SG_ 1193 CF_AVN_EscortHLNValueSet 4;
BA_ "UserSigValidity" SG_ 1193 CF_AVN_EscortHLNValueSet 3;
BA_ "Version" SG_ 1193 CF_AVN_EscortHLNValueSet "18.09.04";
BA_ "GenMsgCycleTime" BO_ 1195 0;
BA_ "Description" SG_ 1195 CF_AVN_CluWelcomeSnd "16.06.04_";
BA_ "GenSigSendType" SG_ 1195 CF_AVN_CluWelcomeSnd 4;
BA_ "UserSigValidity" SG_ 1195 CF_AVN_CluWelcomeSnd 3;
BA_ "Version" SG_ 1195 CF_AVN_CluWelcomeSnd "18.04.02";
BA_ "Description" SG_ 1195 CF_AVN_CluTransmissionDisp "16.06.04_";
BA_ "GenSigSendType" SG_ 1195 CF_AVN_CluTransmissionDisp 4;
BA_ "UserSigValidity" SG_ 1195 CF_AVN_CluTransmissionDisp 3;
BA_ "Version" SG_ 1195 CF_AVN_CluTransmissionDisp "18.04.02";
BA_ "Description" SG_ 1195 CF_AVN_CluWiperLight "16.06.04_";
BA_ "GenSigSendType" SG_ 1195 CF_AVN_CluWiperLight 4;
BA_ "UserSigValidity" SG_ 1195 CF_AVN_CluWiperLight 3;
BA_ "Version" SG_ 1195 CF_AVN_CluWiperLight "18.04.02";
BA_ "Description" SG_ 1195 CF_AVN_CluRoadInfoGuide "16.06.04_";
BA_ "GenSigSendType" SG_ 1195 CF_AVN_CluRoadInfoGuide 4;
BA_ "UserSigValidity" SG_ 1195 CF_AVN_CluRoadInfoGuide 3;
BA_ "Version" SG_ 1195 CF_AVN_CluRoadInfoGuide "18.04.02";
BA_ "Description" SG_ 1195 CF_AVN_CluUserSettingPeriod "16.06.04_";
BA_ "GenSigSendType" SG_ 1195 CF_AVN_CluUserSettingPeriod 4;
BA_ "GenSigStartValue" SG_ 1195 CF_AVN_CluUserSettingPeriod 127;
BA_ "UserSigValidity" SG_ 1195 CF_AVN_CluUserSettingPeriod 3;
BA_ "Version" SG_ 1195 CF_AVN_CluUserSettingPeriod "19.01.10";
BA_ "Description" SG_ 1195 CF_AVN_CluFuelEconUnit_mi "18.08.08_";
BA_ "GenSigSendType" SG_ 1195 CF_AVN_CluFuelEconUnit_mi 4;
BA_ "UserSigValidity" SG_ 1195 CF_AVN_CluFuelEconUnit_mi 3;
BA_ "Version" SG_ 1195 CF_AVN_CluFuelEconUnit_mi "18.09.04";
BA_ "GenSigSendType" SG_ 1195 CF_AVN_CluFuelEconUnit_km 4;
BA_ "UserSigValidity" SG_ 1195 CF_AVN_CluFuelEconUnit_km 3;
BA_ "Version" SG_ 1195 CF_AVN_CluFuelEconUnit_km "20.08.02";
BA_ "Description" SG_ 1195 CF_AVN_CluUserSettingDistance "16.06.04_";
BA_ "GenSigSendType" SG_ 1195 CF_AVN_CluUserSettingDistance 4;
BA_ "GenSigStartValue" SG_ 1195 CF_AVN_CluUserSettingDistance 131071;
BA_ "UserSigValidity" SG_ 1195 CF_AVN_CluUserSettingDistance 3;
BA_ "Version" SG_ 1195 CF_AVN_CluUserSettingDistance "19.01.10";
BA_ "Description" SG_ 1195 CF_AVN_CluRheostatLvl "18.06.00_";
BA_ "GenSigSendType" SG_ 1195 CF_AVN_CluRheostatLvl 4;
BA_ "GenSigStartValue" SG_ 1195 CF_AVN_CluRheostatLvl 31;
BA_ "UserSigValidity" SG_ 1195 CF_AVN_CluRheostatLvl 3;
BA_ "Version" SG_ 1195 CF_AVN_CluRheostatLvl "18.06.04";
BA_ "Description" SG_ 1195 CF_AVN_EVReset "18.08.08_Request to reset EV Service (0x1 : EV USM Reset)";
BA_ "GenSigSendType" SG_ 1195 CF_AVN_EVReset 4;
BA_ "UserSigValidity" SG_ 1195 CF_AVN_EVReset 7;
BA_ "Version" SG_ 1195 CF_AVN_EVReset "18.09.04";
BA_ "Description" SG_ 1195 CF_AVN_UnitReset "18.08.08_";
BA_ "GenSigSendType" SG_ 1195 CF_AVN_UnitReset 4;
BA_ "UserSigValidity" SG_ 1195 CF_AVN_UnitReset 3;
BA_ "Version" SG_ 1195 CF_AVN_UnitReset "18.09.04";
BA_ "Description" SG_ 1195 CF_AVN_IcyRoadWarn "17.02.05_";
BA_ "GenSigSendType" SG_ 1195 CF_AVN_IcyRoadWarn 4;
BA_ "UserSigValidity" SG_ 1195 CF_AVN_IcyRoadWarn 3;
BA_ "Version" SG_ 1195 CF_AVN_IcyRoadWarn "18.04.02";
BA_ "Description" SG_ 1195 CF_AVN_CluServiceReminderReset "16.11.03_";
BA_ "GenSigSendType" SG_ 1195 CF_AVN_CluServiceReminderReset 4;
BA_ "UserSigValidity" SG_ 1195 CF_AVN_CluServiceReminderReset 3;
BA_ "Version" SG_ 1195 CF_AVN_CluServiceReminderReset "18.04.02";
BA_ "GenSigSendType" SG_ 1195 CF_AVN_CluUSMReset 4;
BA_ "UserSigValidity" SG_ 1195 CF_AVN_CluUSMReset 3;
BA_REL_ "GenSigTimeoutTime" BU_SG_REL_ ALBCU SG_ 1195 CF_AVN_CluUSMReset 0;
BA_REL_ "GenSigTimeoutTime" BU_SG_REL_ ARS SG_ 1195 CF_AVN_CluUSMReset 0;
BA_REL_ "GenSigTimeoutTime" BU_SG_REL_ ASAU SG_ 1195 CF_AVN_CluUSMReset 0;
BA_REL_ "GenSigTimeoutTime" BU_SG_REL_ ATS SG_ 1195 CF_AVN_CluUSMReset 0;
BA_REL_ "GenSigTimeoutTime" BU_SG_REL_ BLTN_CAM SG_ 1195 CF_AVN_CluUSMReset 0;
BA_REL_ "GenSigTimeoutTime" BU_SG_REL_ DSAU SG_ 1195 CF_AVN_CluUSMReset 0;
BA_REL_ "GenSigTimeoutTime" BU_SG_REL_ GW_APSU SG_ 1195 CF_AVN_CluUSMReset 0;
BA_REL_ "GenSigTimeoutTime" BU_SG_REL_ GW_DLBCU SG_ 1195 CF_AVN_CluUSMReset 0;
BA_REL_ "GenSigTimeoutTime" BU_SG_REL_ GW_DPSU SG_ 1195 CF_AVN_CluUSMReset 0;
BA_REL_ "GenSigTimeoutTime" BU_SG_REL_ GW_RLPSU SG_ 1195 CF_AVN_CluUSMReset 0;
BA_REL_ "GenSigTimeoutTime" BU_SG_REL_ GW_RRPSU SG_ 1195 CF_AVN_CluUSMReset 0;
BA_REL_ "GenSigTimeoutTime" BU_SG_REL_ PFSU SG_ 1195 CF_AVN_CluUSMReset 0;
BA_REL_ "GenSigTimeoutTime" BU_SG_REL_ RCM SG_ 1195 CF_AVN_CluUSMReset 0;
BA_REL_ "GenSigTimeoutTime" BU_SG_REL_ RLHV SG_ 1195 CF_AVN_CluUSMReset 0;
BA_REL_ "GenSigTimeoutTime" BU_SG_REL_ RRHV SG_ 1195 CF_AVN_CluUSMReset 0;
BA_REL_ "GenSigTimeoutTime" BU_SG_REL_ RWPC SG_ 1195 CF_AVN_CluUSMReset 0;
BA_REL_ "GenSigTimeoutTime" BU_SG_REL_ SGU SG_ 1195 CF_AVN_CluUSMReset 0;
BA_REL_ "GenSigTimeoutTime" BU_SG_REL_ SHVU_FR SG_ 1195 CF_AVN_CluUSMReset 0;
BA_REL_ "GenSigTimeoutTime" BU_SG_REL_ SHVU_RR SG_ 1195 CF_AVN_CluUSMReset 0;
BA_REL_ "GenSigTimeoutTime" BU_SG_REL_ SLB SG_ 1195 CF_AVN_CluUSMReset 0;
BA_REL_ "GenSigTimeoutTime" BU_SG_REL_ WPC SG_ 1195 CF_AVN_CluUSMReset 0;
BA_REL_ "GenSigTimeoutTime" BU_SG_REL_ WPC2 SG_ 1195 CF_AVN_CluUSMReset 0;
BA_ "Version" SG_ 1195 CF_AVN_CluUSMReset "21.01.08";
BA_ "Description" SG_ 1195 CF_AVN_CluServiceReminderSet "16.06.04_";
BA_ "GenSigSendType" SG_ 1195 CF_AVN_CluServiceReminderSet 4;
BA_ "UserSigValidity" SG_ 1195 CF_AVN_CluServiceReminderSet 3;
BA_ "Version" SG_ 1195 CF_AVN_CluServiceReminderSet "18.04.02";
BA_ "GenMsgCycleTime" BO_ 1196 0;
BA_ "Description" SG_ 1196 C_HCIMSWeightNValueSet "18.08.09_";
BA_ "GenSigSendType" SG_ 1196 C_HCIMSWeightNValueSet 4;
BA_ "UserSigValidity" SG_ 1196 C_HCIMSWeightNValueSet 3;
BA_REL_ "GenSigTimeoutTime" BU_SG_REL_ GW_DPSU SG_ 1196 C_HCIMSWeightNValueSet 0;
BA_ "Version" SG_ 1196 C_HCIMSWeightNValueSet "18.09.04";
BA_ "Description" SG_ 1196 C_HCIMSSitHeightNValueSet "18.08.09_";
BA_ "GenSigSendType" SG_ 1196 C_HCIMSSitHeightNValueSet 4;
BA_ "UserSigValidity" SG_ 1196 C_HCIMSSitHeightNValueSet 3;
BA_REL_ "GenSigTimeoutTime" BU_SG_REL_ GW_DPSU SG_ 1196 C_HCIMSSitHeightNValueSet 0;
BA_ "Version" SG_ 1196 C_HCIMSSitHeightNValueSet "18.09.04";
BA_ "Description" SG_ 1196 CF_AVN_BodySpprtSet "18.11.00_This signal is for the seat body support USM";
BA_ "GenSigSendType" SG_ 1196 CF_AVN_BodySpprtSet 4;
BA_ "GenSigStartValue" SG_ 1196 CF_AVN_BodySpprtSet 3;
BA_ "UserSigValidity" SG_ 1196 CF_AVN_BodySpprtSet 3;
BA_REL_ "GenSigTimeoutTime" BU_SG_REL_ DSAU SG_ 1196 CF_AVN_BodySpprtSet 0;
BA_REL_ "GenSigTimeoutTime" BU_SG_REL_ GW_DLBCU SG_ 1196 CF_AVN_BodySpprtSet 0;
BA_REL_ "GenSigTimeoutTime" BU_SG_REL_ GW_DPSU SG_ 1196 CF_AVN_BodySpprtSet 0;
BA_ "Version" SG_ 1196 CF_AVN_BodySpprtSet "18.11.01";
BA_ "Description" SG_ 1196 CF_AVN_AirSptTimeNValueSet "18.08.09_This signal is for the seat massage function time setting";
BA_ "GenSigSendType" SG_ 1196 CF_AVN_AirSptTimeNValueSet 4;
BA_ "GenSigStartValue" SG_ 1196 CF_AVN_AirSptTimeNValueSet 7;
BA_ "UserSigValidity" SG_ 1196 CF_AVN_AirSptTimeNValueSet 3;
BA_REL_ "GenSigTimeoutTime" BU_SG_REL_ GW_DLBCU SG_ 1196 CF_AVN_AirSptTimeNValueSet 0;
BA_ "Version" SG_ 1196 CF_AVN_AirSptTimeNValueSet "18.09.04";
BA_ "Description" SG_ 1196 CF_AVN_AirSptStrNValue "18.08.09_This signal is for the seat massage intensity USM";
BA_ "GenSigSendType" SG_ 1196 CF_AVN_AirSptStrNValue 4;
BA_ "GenSigStartValue" SG_ 1196 CF_AVN_AirSptStrNValue 3;
BA_ "UserSigValidity" SG_ 1196 CF_AVN_AirSptStrNValue 3;
BA_REL_ "GenSigTimeoutTime" BU_SG_REL_ GW_DLBCU SG_ 1196 CF_AVN_AirSptStrNValue 0;
BA_ "Version" SG_ 1196 CF_AVN_AirSptStrNValue "18.09.04";
BA_ "Description" SG_ 1196 CF_AVN_SeatDrvModNValueSet "18.08.09_This signal is for the auto seat-drivemode user setting menu";
BA_ "GenSigSendType" SG_ 1196 CF_AVN_SeatDrvModNValueSet 4;
BA_ "GenSigStartValue" SG_ 1196 CF_AVN_SeatDrvModNValueSet 3;
BA_ "UserSigValidity" SG_ 1196 CF_AVN_SeatDrvModNValueSet 3;
BA_REL_ "GenSigTimeoutTime" BU_SG_REL_ DSAU SG_ 1196 CF_AVN_SeatDrvModNValueSet 0;
BA_REL_ "GenSigTimeoutTime" BU_SG_REL_ GW_DLBCU SG_ 1196 CF_AVN_SeatDrvModNValueSet 0;
BA_REL_ "GenSigTimeoutTime" BU_SG_REL_ GW_DPSU SG_ 1196 CF_AVN_SeatDrvModNValueSet 0;
BA_ "Version" SG_ 1196 CF_AVN_SeatDrvModNValueSet "18.09.04";
BA_ "Description" SG_ 1196 C_HCIMSHeightNvalueSet "18.08.09_";
BA_ "GenSigSendType" SG_ 1196 C_HCIMSHeightNvalueSet 4;
BA_ "UserSigValidity" SG_ 1196 C_HCIMSHeightNvalueSet 3;
BA_REL_ "GenSigTimeoutTime" BU_SG_REL_ GW_DPSU SG_ 1196 C_HCIMSHeightNvalueSet 0;
BA_ "Version" SG_ 1196 C_HCIMSHeightNvalueSet "18.09.04";
BA_ "Description" SG_ 1196 C_SmrtSldngDrNValueSet "USM request for Smart Sliding Door";
BA_ "GenSigSendType" SG_ 1196 C_SmrtSldngDrNValueSet 4;
BA_ "UserSigValidity" SG_ 1196 C_SmrtSldngDrNValueSet 3;
BA_ "Version" SG_ 1196 C_SmrtSldngDrNValueSet "19.01.10";
BA_ "Description" SG_ 1196 CF_AVN_TurboPressureUnit "USM Request for Turbo Boost Pressure Unit";
BA_ "GenSigSendType" SG_ 1196 CF_AVN_TurboPressureUnit 4;
BA_ "UserSigValidity" SG_ 1196 CF_AVN_TurboPressureUnit 3;
BA_ "Version" SG_ 1196 CF_AVN_TurboPressureUnit "19.06.02";
BA_ "Description" SG_ 1196 CF_AVN_CluTorqueUnit "USM Request for Torque Unit Setting";
BA_ "GenSigSendType" SG_ 1196 CF_AVN_CluTorqueUnit 4;
BA_ "UserSigValidity" SG_ 1196 CF_AVN_CluTorqueUnit 3;
BA_ "Version" SG_ 1196 CF_AVN_CluTorqueUnit "19.06.02";
BA_ "Description" SG_ 1196 CF_AVN_HCIMSButtonCommand "18.08.09_";
BA_ "GenSigSendType" SG_ 1196 CF_AVN_HCIMSButtonCommand 4;
BA_ "UserSigValidity" SG_ 1196 CF_AVN_HCIMSButtonCommand 3;
BA_REL_ "GenSigTimeoutTime" BU_SG_REL_ GW_DPSU SG_ 1196 CF_AVN_HCIMSButtonCommand 0;
BA_ "Version" SG_ 1196 CF_AVN_HCIMSButtonCommand "18.09.04";
BA_ "GenMsgSendType" BO_ 2164277252 0;
BA_ "GenMsgCycleTime" BO_ 2164277252 50;
BA_ "GenMsgCycleTimeFast" BO_ 2164277252 0;
BA_ "GenMsgNrOfRepetition" BO_ 2164277252 0;
BA_ "VFrameFormat" BO_ 2164277252 1;
BA_ "Description" SG_ 2164277252 TCU_NetrlCtrlSta "This signal indicates the status of Neutral Control.";
BA_ "UserSigValidity" SG_ 2164277252 TCU_NetrlCtrlSta 3;
BA_ "RoutingFactor" SG_ 2164277252 TCU_NetrlCtrlSta 5;
BA_ "Version" SG_ 2164277252 TCU_NetrlCtrlSta "17.11.00";
BA_ "Description" SG_ 2164277252 TCU_ShftPtrnSta "It is an ID of current shift pattern which is being used by TCU.

The ID is assigned for each TCU.";
BA_ "UserSigValidity" SG_ 2164277252 TCU_ShftPtrnSta 3;
BA_ "RoutingFactor" SG_ 2164277252 TCU_ShftPtrnSta 5;
BA_ "Version" SG_ 2164277252 TCU_ShftPtrnSta "17.11.00";
BA_ "Description" SG_ 2164277252 TCU_EPBReq "This is EPB Request signal for prevent P-D Shift shock on the hill";
BA_ "UserSigValidity" SG_ 2164277252 TCU_EPBReq 3;
BA_ "RoutingFactor" SG_ 2164277252 TCU_EPBReq 5;
BA_ "Version" SG_ 2164277252 TCU_EPBReq "19.03.09";
BA_ "Description" SG_ 2164277252 IMT_EOLstate "If this signal is set, Cluster should display gear info using alphabet 'E' regardless the signal 'TCU_GearSlctDis'";
BA_ "UserSigValidity" SG_ 2164277252 IMT_EOLstate 3;
BA_ "RoutingFactor" SG_ 2164277252 IMT_EOLstate 5;
BA_ "Version" SG_ 2164277252 IMT_EOLstate "19.02.06";
BA_ "Description" SG_ 2164277252 IMT_DisCmd "This signal is used for cluster to change gear display type. 

Always Display / Not Display / Blinking";
BA_ "UserSigValidity" SG_ 2164277252 IMT_DisCmd 3;
BA_ "RoutingFactor" SG_ 2164277252 IMT_DisCmd 5;
BA_ "Version" SG_ 2164277252 IMT_DisCmd "19.02.06";
BA_ "Description" SG_ 2164277252 IMT_CltchPdlPos "Clutch Position Sensor value for 3 pedal IMT system.

This value is not supported by 2 pedal IMT system.



0% means pedal off 

99.21875% (0xFE) means pedal fully pressed

99.609375 (0xFF) means  error";
BA_ "UserSigValidity" SG_ 2164277252 IMT_CltchPdlPos 3;
BA_ "RoutingFactor" SG_ 2164277252 IMT_CltchPdlPos 5;
BA_ "Version" SG_ 2164277252 IMT_CltchPdlPos "19.02.06";
BA_ "Description" SG_ 2164277252 DCT_RegenInhbt "The regen inhibit request from TCU.

ECU is received regen inhibit flag from TCU, then ECU is limited the regen state.";
BA_ "UserSigValidity" SG_ 2164277252 DCT_RegenInhbt 3;
BA_ "RoutingFactor" SG_ 2164277252 DCT_RegenInhbt 5;
BA_ "Version" SG_ 2164277252 DCT_RegenInhbt "18.08.02";
BA_ "Description" SG_ 2164277252 DCT_EngIdleReq "Engine Idle Request from TCU";
BA_ "UserSigValidity" SG_ 2164277252 DCT_EngIdleReq 3;
BA_ "RoutingFactor" SG_ 2164277252 DCT_EngIdleReq 5;
BA_ "Version" SG_ 2164277252 DCT_EngIdleReq "18.08.02";
BA_ "Description" SG_ 2164277252 DCT_CltchState "Status of DCT clutches. This signal gives information about the frictional connection between the engine and the drive train.";
BA_ "UserSigValidity" SG_ 2164277252 DCT_CltchState 3;
BA_ "RoutingFactor" SG_ 2164277252 DCT_CltchState 5;
BA_ "Version" SG_ 2164277252 DCT_CltchState "18.08.02";
BA_ "Description" SG_ 2164277252 DCT_FuelCutReq "Fuel Cut request bit signal to let EMS perform ¡®Fuel Cut torque intervention¡¯ during shift";
BA_ "UserSigValidity" SG_ 2164277252 DCT_FuelCutReq 3;
BA_ "RoutingFactor" SG_ 2164277252 DCT_FuelCutReq 5;
BA_ "Version" SG_ 2164277252 DCT_FuelCutReq "18.08.02";
BA_ "Description" SG_ 2164277252 DCT_TqIncReq "An Identifier of a DCT TCU controller for increasing torque intervention. 

This bit is to prevent the triggering of unintended DCT TCU interventions.



In the case of a torque increase, following conditions must be fulfilled.

DCT_TqIncReq = 1 and TCU_EngTqIncReqVal > 00H.";
BA_ "UserSigValidity" SG_ 2164277252 DCT_TqIncReq 3;
BA_ "RoutingFactor" SG_ 2164277252 DCT_TqIncReq 5;
BA_ "Version" SG_ 2164277252 DCT_TqIncReq "18.08.02";
BA_ "Description" SG_ 2164277252 DCT_CrpTqReq "During creep mode (engine in idle, brake pedal not pressed, gear engaged) clutch torque will be applied. In order to support the engine¡¯s idle controller DCT_CrpTqReq gives the information how much clutch torque will be applied within the next 50 ms.";
BA_ "GenSigStartValue" SG_ 2164277252 DCT_CrpTqReq 512;
BA_ "UserSigValidity" SG_ 2164277252 DCT_CrpTqReq 3;
BA_ "RoutingFactor" SG_ 2164277252 DCT_CrpTqReq 5;
BA_ "Version" SG_ 2164277252 DCT_CrpTqReq "18.08.02";
BA_ "Description" SG_ 2164277252 DCT_ShftTqReq "To ensure a torque increasing during gear shift within short time, ECU needs to build up a torque reserve determined by the pre-control torque. 

Open throttle valve (more air) and automatic ignition angle reduction (within limited range based on engine characteristic) to ensure constant torque level.

The DCT TCU informs a pre-control torque via the signal DCT_ShftTqReq to the EMS.



If MSB is 1, this signal is - value. else, this signal is +value.

0~10bit is used for absolute value.";
BA_ "UserSigValidity" SG_ 2164277252 DCT_ShftTqReq 3;
BA_ "RoutingFactor" SG_ 2164277252 DCT_ShftTqReq 5;
BA_ "Version" SG_ 2164277252 DCT_ShftTqReq "20.03.05";
BA_ "Description" SG_ 2164277252 TCU_VgisInhbtReq "TCU requests ECU to inhibit the VGIS fuction from changing its status.";
BA_ "UserSigValidity" SG_ 2164277252 TCU_VgisInhbtReq 3;
BA_ "RoutingFactor" SG_ 2164277252 TCU_VgisInhbtReq 5;
BA_ "Version" SG_ 2164277252 TCU_VgisInhbtReq "17.11.00";
BA_ "Description" SG_ 2164277252 TCU_EngTqIncReqVal "The TCU requests the engine torque increase via this signal to the EMS.



If MSB is 1, this signal is - value.

else, this signal is +value.

0~10bit is used for absolute value.";
BA_ "UserSigValidity" SG_ 2164277252 TCU_EngTqIncReqVal 3;
BA_ "RoutingFactor" SG_ 2164277252 TCU_EngTqIncReqVal 5;
BA_ "Version" SG_ 2164277252 TCU_EngTqIncReqVal "20.03.05";
BA_ "GenMsgSendType" BO_ 2189467649 0;
BA_ "GenMsgCycleTime" BO_ 2189467649 50;
BA_ "GenMsgCycleTimeFast" BO_ 2189467649 0;
BA_ "GenMsgNrOfRepetition" BO_ 2189467649 0;
BA_ "VFrameFormat" BO_ 2189467649 1;
BA_ "Description" SG_ 2189467649 WHL_Crc1Val "The data area for CRC calculation is based on the data length (DLC) of the message DB.

The CRC shall be calculated over the entire data block (excluding the CRC bytes) including the user data, alive counter and Data ID



- CRC Polynomial (0x1021) , Initial Value : 0xFFFF, XOR value : 0x0000, Data ID : Message ID + 0xF800 

- The initial value is for CRC calculation and the message should be sent with the calculated result value. 

- The mathematical expression to 16 bit CRC polynomial is given here. G(x) = x16 + x12 + x5 + 1



<For CRC calculation of CAN-FD Msg for HS CAN domain ECUs>



- HS-CAN Messages that routed from CAN-FD domain are using 29 bit Extended CAN ID and splitted into 8 Byte Messages.

(from 1 to 4 Msgs, depending on source CAN-FD Msg¡¯s DLC)

- For splitted CAN-FD Msgs¡¯ CRC calculation, HS CAN ECUs should use source CAN-FD Msg¡¯s original STD ID. 

- The original STD ID can be read from Ext ID¡¯s 4~6th Byte.

Eg. STD 0x6AA : EXT SPLT 0x1A8[6AA]01 / 0x1A8[6AA]02 / 0x1A8[6AA]03 / 0x1A8[6AA]04 

(2~4th splitited Msgs can be omitted depending on source CAN-FD Msg¡¯s DLC)

- Aslo, HS-CAN ECUs should use merged data block (from whole splitted Msg) for CRC calculation.";
BA_ "GenSigStartValue" SG_ 2189467649 WHL_Crc1Val 65535;
BA_ "UserSigValidity" SG_ 2189467649 WHL_Crc1Val 3;
BA_ "RoutingFactor" SG_ 2189467649 WHL_Crc1Val 5;
BA_ "Version" SG_ 2189467649 WHL_Crc1Val "21.09.03";
BA_ "Description" SG_ 2189467649 WHL_AlvCnt1Val "For the first transmission request for a data element the counter shall be initialized with 0 and shall be incremented by 1 for every subsequent send request. 

When the counter reaches the maximum value(0xFF), then it shall restart with 0 for the next send request";
BA_ "UserSigValidity" SG_ 2189467649 WHL_AlvCnt1Val 3;
BA_ "RoutingFactor" SG_ 2189467649 WHL_AlvCnt1Val 5;
BA_ "Version" SG_ 2189467649 WHL_AlvCnt1Val "21.09.03";
BA_ "Description" SG_ 2189467649 WHL_PlsFLVal "This signal indicates accumulated pulse counter of ABS^ESC wheel speed sensor (FL^FR^RL^RR)

Receiver unit uses this signal for calculation of vehicle movement distance.

Requested resolution of this signal is 0.5 pulses and refer to below (wheel sensor signal).";
BA_ "UserSigValidity" SG_ 2189467649 WHL_PlsFLVal 3;
BA_ "RoutingFactor" SG_ 2189467649 WHL_PlsFLVal 5;
BA_ "Version" SG_ 2189467649 WHL_PlsFLVal "17.12.00";
BA_ "Description" SG_ 2189467649 WHL_PlsFRVal "This signal indicates accumulated pulse counter of ABS^ESC wheel speed sensor (FL^FR^RL^RR)

Receiver unit uses this signal for calculation of vehicle movement distance.

Requested resolution of this signal is 0.5 pulses and refer to below (wheel sensor signal).";
BA_ "UserSigValidity" SG_ 2189467649 WHL_PlsFRVal 3;
BA_ "RoutingFactor" SG_ 2189467649 WHL_PlsFRVal 5;
BA_ "Version" SG_ 2189467649 WHL_PlsFRVal "17.12.00";
BA_ "Description" SG_ 2189467649 WHL_PlsRLVal "This signal indicates accumulated pulse counter of ABS^ESC wheel speed sensor (FL^FR^RL^RR)

Receiver unit uses this signal for calculation of vehicle movement distance.

Requested resolution of this signal is 0.5 pulses and refer to below (wheel sensor signal).";
BA_ "UserSigValidity" SG_ 2189467649 WHL_PlsRLVal 3;
BA_ "RoutingFactor" SG_ 2189467649 WHL_PlsRLVal 5;
BA_ "Version" SG_ 2189467649 WHL_PlsRLVal "17.12.00";
BA_ "Description" SG_ 2189467649 WHL_PlsRRVal "This signal indicates accumulated pulse counter of ABS^ESC wheel speed sensor (FL^FR^RL^RR)

Receiver unit uses this signal for calculation of vehicle movement distance.

Requested resolution of this signal is 0.5 pulses and refer to below (wheel sensor signal).";
BA_ "UserSigValidity" SG_ 2189467649 WHL_PlsRRVal 3;
BA_ "RoutingFactor" SG_ 2189467649 WHL_PlsRRVal 5;
BA_ "Version" SG_ 2189467649 WHL_PlsRRVal "17.12.00";
BA_ "Description" SG_ 2189467649 WHL_DirFLVal "This signal is used to check the moving direction of WHL_PUL_FL signal.";
BA_ "UserSigValidity" SG_ 2189467649 WHL_DirFLVal 3;
BA_ "RoutingFactor" SG_ 2189467649 WHL_DirFLVal 5;
BA_ "Version" SG_ 2189467649 WHL_DirFLVal "17.12.00";
BA_ "Description" SG_ 2189467649 WHL_DirFRVal "This signal is used to check the moving direction of WHL_PUL_FR signal.";
BA_ "UserSigValidity" SG_ 2189467649 WHL_DirFRVal 3;
BA_ "RoutingFactor" SG_ 2189467649 WHL_DirFRVal 5;
BA_ "Version" SG_ 2189467649 WHL_DirFRVal "17.12.00";
BA_ "Description" SG_ 2189467649 WHL_DirRLVal "This signal is used to check the moving direction of WHL_PUL_RL signal.";
BA_ "UserSigValidity" SG_ 2189467649 WHL_DirRLVal 3;
BA_ "RoutingFactor" SG_ 2189467649 WHL_DirRLVal 5;
BA_ "Version" SG_ 2189467649 WHL_DirRLVal "17.12.00";
BA_ "Description" SG_ 2189467649 WHL_DirRRVal "This signal is used to check the moving direction of WHL_PUL_RR signal.";
BA_ "UserSigValidity" SG_ 2189467649 WHL_DirRRVal 3;
BA_ "RoutingFactor" SG_ 2189467649 WHL_DirRRVal 5;
BA_ "Version" SG_ 2189467649 WHL_DirRRVal "17.12.00";
BA_ "GenMsgSendType" BO_ 2189467650 0;
BA_ "GenMsgCycleTime" BO_ 2189467650 50;
BA_ "GenMsgCycleTimeFast" BO_ 2189467650 0;
BA_ "GenMsgNrOfRepetition" BO_ 2189467650 0;
BA_ "VFrameFormat" BO_ 2189467650 1;
BA_ "Description" SG_ 2189467650 WHL_SpdFLVal "This signal provides the wheel velocity of each wheel and have 14 bits length and a resolution of 0.03125 km^h.(This resolution is higher than that of signal in TCS5).

In case of failure of one wheel speed sensor, the value 3FFFH is used as error identifier.";
BA_ "UserSigValidity" SG_ 2189467650 WHL_SpdFLVal 3;
BA_ "RoutingFactor" SG_ 2189467650 WHL_SpdFLVal 5;
BA_ "Version" SG_ 2189467650 WHL_SpdFLVal "17.12.00";
BA_ "Description" SG_ 2189467650 WHL_SpdFRVal "This signal provides the wheel velocity of each wheel and have 14 bits length and a resolution of 0.03125 km^h.(This resolution is higher than that of signal in TCS5).

In case of failure of one wheel speed sensor, the value 3FFFH is used as error identifier.";
BA_ "UserSigValidity" SG_ 2189467650 WHL_SpdFRVal 3;
BA_ "RoutingFactor" SG_ 2189467650 WHL_SpdFRVal 5;
BA_ "Version" SG_ 2189467650 WHL_SpdFRVal "17.12.00";
BA_ "Description" SG_ 2189467650 WHL_SpdRLVal "This signal provides the wheel velocity of each wheel and have 14 bits length and a resolution of 0.03125 km^h.(This resolution is higher than that of signal in TCS5).

In case of failure of one wheel speed sensor, the value 3FFFH is used as error identifier.";
BA_ "UserSigValidity" SG_ 2189467650 WHL_SpdRLVal 3;
BA_ "RoutingFactor" SG_ 2189467650 WHL_SpdRLVal 5;
BA_ "Version" SG_ 2189467650 WHL_SpdRLVal "17.12.00";
BA_ "Description" SG_ 2189467650 WHL_SpdRRVal "This signal provides the wheel velocity of each wheel and have 14 bits length and a resolution of 0.03125 km^h.(This resolution is higher than that of signal in TCS5).

In case of failure of one wheel speed sensor, the value 3FFFH is used as error identifier.";
BA_ "UserSigValidity" SG_ 2189467650 WHL_SpdRRVal 3;
BA_ "RoutingFactor" SG_ 2189467650 WHL_SpdRRVal 5;
BA_ "Version" SG_ 2189467650 WHL_SpdRRVal "17.12.00";
BA_ "GenMsgSendType" BO_ 2189467651 0;
BA_ "GenMsgCycleTime" BO_ 2189467651 50;
BA_ "GenMsgCycleTimeFast" BO_ 2189467651 0;
BA_ "GenMsgNrOfRepetition" BO_ 2189467651 0;
BA_ "VFrameFormat" BO_ 2189467651 1;
BA_ "Description" SG_ 2189467651 WHL_SpdCalParmtr "ÀÌ ½ÅÈ£´Â ABS/ESC ³»ºÎ¿¡¼­ ÈÙ ÆÞ½º °ªÀ» ÈÙ ½ºÇÇµå·Î º¯È¯ÇÏ´Âµ¥ »ç¿ëÇÏ´Â ESC ³»ºÎ ÆÄ¶ó¹ÌÅÍ¸¦ ÀÇ¹ÌÇÔ.

º» ½ÅÈ£´Â ½ÇÁ¦ Å¸ÀÌ¾î µ¿¹Ý°æ°ú ´Ù¸¦ ¼ö ÀÖÀ¸¸ç, ABS/ESCÀÇ Á¦¾î¸¦ À§ÇÑ Â÷¼Ó ÃßÁ¤À» À§ÇØ °³¹ß °úÁ¤ Áß¿¡ ÀÓÀÇ·Î º¯°æÀÌ °¡´ÉÇÑ Calibration Value ÀÓ.

½ÅÈ£ »ç¿ëÀ» À§ÇØ¼­´Â »çÀü¿¡ ÇùÀÇ ÈÄ »ç¿ëÇØ¾ßÇÔ.";
BA_ "UserSigValidity" SG_ 2189467651 WHL_SpdCalParmtr 3;
BA_ "RoutingFactor" SG_ 2189467651 WHL_SpdCalParmtr 5;
BA_ "Version" SG_ 2189467651 WHL_SpdCalParmtr "19.05.02";
VAL_ 2328015105 ADAS_CMD_Crc34Val 0 "0x0x0~0xFFFF:CRCValue" 65535 "0x0x0~0xFFFF:CRCValue" ;
VAL_ 2328015105 ADAS_CMD_AlvCnt34Val 0 "0x0x0~0xFF:AlvCntValue" 255 "0x0x0~0xFF:AlvCntValue" ;
VAL_ 2328015105 HDP_RDD_WarnSta 0 "No request" 1 "MRM Warning Request" 2 "MRM Stop" 3 "EM Warning Request" 4 "RESERVED" 5 "RESERVED" 6 "RESERVED" 7 "RESERVED" ;
VAL_ 2328015105 HDP_RDD_HzrdLmpReqSta 0 "Hazard Lamp Inactive Request" 1 "Hazard Lamp Active Request" 2 "Reserved" 3 "Reserved" ;
VAL_ 2328015105 HDP_RDD_ACIActvDispSta 0 "INIT" 1 "INACTIVE" 2 "ACTIVE30(ACTIVE)" 3 "ACTIVE33(Redundancy)" ;
VAL_ 2328015106 HDP_RDD_EMStbltActvReqSta 0 "Release No alert" 1 "Pre-crash full retraction" 2 "Haptic warning" 3 "Reserved" 4 "Reserved" 5 "Reserved" 6 "Reserved" 7 "Reserved" ;
VAL_ 287 APSS_LumbarUpSw 0 "Default" 1 "Off" 2 "On" 3 "Invalid" ;
VAL_ 287 APSS_LumbarMidSw 0 "Default" 1 "Off" 2 "On" 3 "Invalid" ;
VAL_ 287 APSS_LumbarLowSw 0 "Default" 1 "Off" 2 "On" 3 "Invalid" ;
VAL_ 287 APSS_LumbarDefSw 0 "Default" 1 "Off" 2 "On" 3 "Invalid" ;
VAL_ 287 APSS_BolsterInfSw 0 "Default" 1 "Off" 2 "On" 3 "Invalid" ;
VAL_ 287 APSS_BolsterDefSw 0 "Default" 1 "Off" 2 "On" 3 "Invalid" ;
VAL_ 287 APSS_ActiveSw 0 "Default" 1 "Off" 2 "On" 3 "Invaild" ;
VAL_ 287 APSS_CushInfSw 0 "Default" 1 "Off" 2 "On" 3 "Invaild" ;
VAL_ 287 APSS_CushDefSw 0 "Default" 1 "Off" 2 "On" 3 "Invaild" ;
VAL_ 273 ARS_RrCurtainBtn 0 "Default" 1 "Open ON" 2 "Close ON" 3 "Invalid" ;
VAL_ 271 ASAU_AirSptTimeRValueSet 0 "Default" 1 "Short" 2 "Normal" 3 "Long" 4 "Reserved" 5 "Reserved" 6 "Reserved" 7 "Reserved" ;
VAL_ 271 ASAU_AstSmtAirSptRValueSet 0 "Default" 1 "Off" 2 "On" 3 "Invalid" ;
VAL_ 271 ASAU_CushSoftRValueSet 0 "Default" 1 "Off" 2 "Soft" 3 "Mid" 4 "Hard" 5 "Reserved" 6 "Reserved" 7 "Reserved" ;
VAL_ 271 ASAU_BackSoftRValueSet 0 "Default" 1 "Off" 2 "Soft" 3 "Mid" 4 "Hard" 5 "Reserved" 6 "Reserved" 7 "Reserved" ;
VAL_ 271 ASAU_AirSptModeRValueSet 0 "Default" 1 "Mode 1" 2 "Mode 2" 3 "Mode 3" 4 "Mode 4" 5 "Mode 5" 6 "Reserved" 7 "Reserved" ;
VAL_ 271 ASAU_NotFootMsgOperStaWarnPE 0 "Default" 1 "Off (Disable)" 2 "On (Enable)" 3 "Invalid" ;
VAL_ 271 ASAU_RRFootAirSptRValueSet 0 "Default" 1 "Off" 2 "On" 3 "Invalid" ;
VAL_ 271 ASAU_RRFootAirSptHeatRValueSet 0 "Default" 1 "Off" 2 "On" 3 "Invalid" ;
VAL_ 271 ASAU_MoodTrpyRValueSet 0 "Default" 1 "Off" 2 "On" 3 "Invalid" ;
VAL_ 271 ASAU_MoodTrpyCareSta 0 "Default" 1 "Off" 2 "On" 3 "Invalid" ;
VAL_ 271 ASAU_MoodTrpyComfSta 0 "Default" 1 "Off" 2 "On" 3 "Invalid" ;
VAL_ 271 ASAU_AirSptStrRValueSet 0 "Default" 1 "Low" 2 "Mid" 3 "High" 4 "Off" 5 "Reserved" 6 "Reserved" 7 "Reserved" ;
VAL_ 255 BCM_Crc20Val 0 "0x0x0~0xFF:CRCValue" 255 "0x0x0~0xFF:CRCValue" ;
VAL_ 255 Window_BuffetRdctnActvSta 0 "Off" 1 "On" 2 "RESERVED" 3 "Error Indicator" ;
VAL_ 255 BCM_AlvCnt20Val 0 "AlvCntValue" 1 "AlvCntValue" 2 "AlvCntValue" 3 "AlvCntValue" 4 "AlvCntValue" 5 "AlvCntValue" 6 "AlvCntValue" 7 "AlvCntValue" 8 "AlvCntValue" 9 "AlvCntValue" 10 "AlvCntValue" 11 "AlvCntValue" 12 "AlvCntValue" 13 "AlvCntValue" 14 "AlvCntValue" 15 "AlvCntValue" ;
VAL_ 255 BckGls_RrGlsHtdOnCmd 0 "Off" 1 "On" 2 "Not Used" 3 "Error Indicator" ;
VAL_ 255 Wndshld_FrtGlsHtdOnCmd 0 "Off" 1 "On" 2 "Not Used" 3 "Error Indicator" ;
VAL_ 255 Mirror_MirFldOpt 0 "Not Applied" 1 "Applied" 2 "Not Used" 3 "Error Indicator" ;
VAL_ 255 Window_AsstPwrWdwSunroofEnblSta 0 "Disable" 1 "Enable" 2 "Not Used" 3 "Error Indicator" ;
VAL_ 255 Window_RrPwrWdwEnblSta 0 "Off" 1 "On" 2 "Not Used" 3 "Error Indicator" ;
VAL_ 255 Window_RrPwrWdwLkInd 0 "Off" 1 "On" 2 "Not Used" 3 "Error Indicator" ;
VAL_ 255 Window_DrvPwrWdwCmd 0 "NoAction" 1 "ManualUp" 2 "ManualDown" 3 "Error Indicator" ;
VAL_ 255 Window_AsstPwrWdwCmd 0 "NoAction" 1 "ManualUp" 2 "ManualDown" 3 "Error Indicator" ;
VAL_ 255 Window_RrLftPwrWdwCmd 0 "NoAction" 1 "ManualUp" 2 "ManualDown" 3 "Error Indicator" ;
VAL_ 255 Window_RrRtPwrWdwCmd 0 "NoAction" 1 "ManualUp" 2 "ManualDown" 3 "Error Indicator" ;
VAL_ 255 Mirror_FldUnfldCmd 0 "Off" 1 "Fold" 2 "Unfold" 3 "Error Indicator" ;
VAL_ 255 Mirror_FldCtrlSta 0 "Off" 1 "Fldng" 2 "Fld" 3 "Error Indicator" ;
VAL_ 255 Mirror_UnFldCtrlSta 0 "Off" 1 "UnFldng" 2 "UnFld" 3 "Error Indicator" ;
VAL_ 255 Mirror_PosMnlCmd 0 "Off" 1 "Up" 2 "Down" 3 "Left" 4 "Right" 5 "Not Used" 6 "Not Used" 7 "Error Indicator" ;
VAL_ 255 Mirror_SelSwIndCmd 0 "Off" 1 "Left" 2 "Neutral" 3 "Right" 4 "Not Used" 5 "Not Used" 6 "Not Used" 7 "Error Indicator" ;
VAL_ 255 BCM_SafetyWdwOptTyp2 0 "None" 1 "Driver Safety Window" 2 "Front Safety Window" 3 "All Safety Window" 4 "Not Used" 5 "Not Used" 6 "Not Used" 7 "Error Indicator" ;
VAL_ 255 Mirror_LHOSMirPlyBckSta 0 "Stop" 1 "Play 1" 2 "Play 2" 3 "Play 3" 4 "Smart IMS" 5 "Profile 1" 6 "Profile 2" 7 "Guest" 8 "Not Used" 9 "Not Used" 10 "Not Used" 11 "Not Used" 12 "Not Used" 13 "Not Used" 14 "Not Used" 15 "Error Indicator" ;
VAL_ 255 Mirror_RHOSMirPlyBckSta 0 "Stop" 1 "Play 1" 2 "Play 2" 3 "Play 3" 4 "Smart IMS" 5 "Profile 1" 6 "Profile 2" 7 "Guest" 8 "Not Used" 9 "Not Used" 10 "Not Used" 11 "Not Used" 12 "Not Used" 13 "Not Used" 14 "Not Used" 15 "Error Indicator" ;
VAL_ 255 Mirror_SelSwSta 0 "Off" 1 "Left" 2 "Neutral" 3 "Right" 4 "Not Used" 5 "Not Used" 6 "Not Used" 7 "Error Indicator" ;
VAL_ 255 BckGls_RrGlsHtdOpt 0 "Not Applied" 1 "Applied" 2 "Not Used" 3 "Error Indicator" ;
VAL_ 2395189761 DATC_Crc10Val 0 "0x0x0~0xFFFF:CRCValue" 65535 "0x0x0~0xFFFF:CRCValue" ;
VAL_ 2395189761 DATC_AlvCnt10Val 0 "0x0x0~0xFF:AlvCntValue" 255 "0x0x0~0xFF:AlvCntValue" ;
VAL_ 2395189761 DATC_Typ 255 "Error Indicator" ;
VAL_ 2395189761 DATC_Opt1Typ 255 "Error Indicator" ;
VAL_ 2395189761 DATC_Opt3Typ 255 "Error Indicator" ;
VAL_ 2395189761 DATC_Opt2Typ 15 "Error Indicator" ;
VAL_ 2395189761 DATC_StrWhlUSMSta 0 "NOT APPLY" 1 "OFF" 2 "ON" 3 "Error Indicator" ;
VAL_ 2395189761 DATC_StrWhlHtngReq 0 "Default" 1 "Integrated control OFF" 2 "Steering Wheel heat OFF" 3 "Steering Wheel heat 1st ON" 4 "Steering Wheel heat 1st & 2nd ON" 5 "Reserved" 6 "Reserved" 7 "Invalid" ;
VAL_ 2365803009 DATC_Crc16Val 0 "0x0x0~0xFFFF:CRCValue" 65535 "0x0x0~0xFFFF:CRCValue" ;
VAL_ 2365803009 DATC_AlvCnt16Val 0 "0x0x0~0xFF:AlvCntValue" 255 "0x0x0~0xFF:AlvCntValue" ;
VAL_ 2365803009 DATC_SwVer1 0 "0x0x00~0x7E:ASCII value" 126 "0x0x00~0x7E:ASCII value" 127 "Invalid" ;
VAL_ 2365803009 DATC_SwVer2 0 "0x0x00~0x7E:ASCII value" 126 "0x0x00~0x7E:ASCII value" 127 "Invalid" ;
VAL_ 2365803009 DATC_SwVer3 0 "0x0x00~0x7E:ASCII value" 126 "0x0x00~0x7E:ASCII value" 127 "Invalid" ;
VAL_ 2365803009 DATC_Typ2 0 "0x0x00~0xFF: applied options (See Description)" 255 "0x0x00~0xFF: applied options (See Description)" ;
VAL_ 2365803010 DATC_SwVer4 0 "0x0x00~0x7E:ASCII value" 126 "0x0x00~0x7E:ASCII value" 127 "Invalid" ;
VAL_ 2365803010 DATC_Typ_All_1 0 "0x0x0000~0xFFFF:See Description" 65535 "0x0x0000~0xFFFF:See Description" ;
VAL_ 2365803010 DATC_Typ_All_2 0 "0x0x0000~0xFFFF:See Description" 65535 "0x0x0000~0xFFFF:See Description" ;
VAL_ 2365803010 DATC_SwVer5 0 "0x0x00~0x7E:ASCII value" 126 "0x0x00~0x7E:ASCII value" 127 "Invalid" ;
VAL_ 2365803011 DATC_Typ_All_3 0 "0x0x0000~0xFFFF:See Description" 65535 "0x0x0000~0xFFFF:See Description" ;
VAL_ 2365803011 DATC_Typ_All_4 0 "0x0x0000~0xFFFF:See Description" 65535 "0x0x0000~0xFFFF:See Description" ;
VAL_ 2365803011 DATC_Typ_All_5 0 "0x0x0000~0xFFFF:See Description" 65535 "0x0x0000~0xFFFF:See Description" ;
VAL_ 2365803011 DATC_Typ_All_6 0 "0x0x0000~0xFFFF:See Description" 65535 "0x0x0000~0xFFFF:See Description" ;
VAL_ 2365803012 DATC_Opt_Sys 0 "0x0x00000000~0xFFFFFFFF:See Description" 2147483647 "0x0x00000000~0xFFFFFFFF:See Description" ;
VAL_ 2365803012 DATC_Opt_Func 0 "0x0x00000000~0xFFFFFFFF:See Description" 2147483647 "0x0x00000000~0xFFFFFFFF:See Description" ;
VAL_ 2193667329 EMS_Crc1Val 0 "0x0x0~0xFFFF:CRCValue" 65535 "0x0x0~0xFFFF:CRCValue" ;
VAL_ 2193667329 EMS_AlvCnt1Val 0 "0x0x0~0xFF:AlvCntValue" 255 "0x0x0~0xFF:AlvCntValue" ;
VAL_ 2193667330 ENG_EngSpdErrSta 0 "No error" 1 "Engine speed sensor defective" 2 "Not used" 3 "Error indicator" ;
VAL_ 2193667330 ENG_MafErrSta 0 "No error" 1 "Error on Torque Measurement" 2 "Not used" 3 "Error indicator" ;
VAL_ 2193667330 ENG_EtcLmphModSta 0 "Engine control is available" 1 "ETC Limphome mode by ECU" 2 "Not used" 3 "Error indicator" ;
VAL_ 2193667330 ENG_SpltInjctnSta 0 "Split injection OFF" 1 "Split injection ON" 2 "Not used" 3 "Error indicator" ;
VAL_ 2193667330 ENG_MaxAirconTqVal 255 "Error indicator" ;
VAL_ 2193667330 ENG_AirconPrsrSnsrVal 255 "Error indicator" ;
VAL_ 2193667330 ENG_IsgSta 0 "ISG is not operating Normal engine operating without ISG" 1 "Idle stop is activated Idle is stopped by ECU during driving" 2 "Automatically started by ECU Engine is automatically started by ECU regardless driver¡¯s volition during idle stop because the condition that ISG function to be prohibited is satisfied, for example SOC is too low." 3 "ISG is prohibited Driver prohibits to activate ISG in order to avoid start lag when he met traffic jam for example." 4 "Fault  existing in ISG. Idle stop is prohibited and engine started automatically if it is idle stop condition." 5 "Idle stop is inhibited by system automatically for safety and  convenient condition related with battery SOC, brake vacuum pressure etc. ISG function check for EOL." 6 "Auto start is deactivated system automatically to keep safety, Such as door open, hood open and seat belt unlock." 7 "If driver shift gear N to D range without braking to make auto starting. (Economy ISG Only)" ;
VAL_ 2193667330 ENG_OilLvlSta 0 "OIL LEVEL LAMP Off" 1 "OIL LEVEL LAMP On" 2 "Not used" 3 "Error indicator" ;
VAL_ 2193667331 ENG_TrgtIdleRpmVal 255 "Error indicator" ;
VAL_ 2193667331 ENG_GearShftDnDis 0 "Gear Shiftdown Display Off" 1 "Gear Shiftdown Display On" 2 "Not used" 3 "Error indicator" ;
VAL_ 2193667331 ENG_DsrGearPosDis 0 "No display" 1 "Gear Position 1 display" 2 "Gear Position 2 display" 3 "Gear Position 3 display" 4 "Gear Position 4 display" 5 "Gear Position 5 display" 6 "Gear Position 6 display" 7 "Gear Position 7 display" 8 "Gear Position 8 display" 9 "Gear Position 9 display" 10 "Gear Position 10 display" 15 "Error indicator" ;
VAL_ 2193667331 ENG_SldFuncSta 0 "Speed limiter function is not active" 1 "Speed limiter function is active" 2 "Not used" 3 "Error indicator" ;
VAL_ 2193667331 ENG_SldActnSta 0 "Positive action is not active" 1 "Positive action is active" 2 "Not used" 3 "Error indicator" ;
VAL_ 2193667331 ENG_FuelTnkPrsrSta 0 "Fuel Tank is not in high Pressure" 1 "Fuel Tank is in high Pressure" 2 "Not used" 3 "Error indicator" ;
VAL_ 2193667331 ENG_IsgBzrReq 0 "Request buzzer OFF" 1 "Request buzzer ON" 2 "Not used" 3 "Error indicator" ;
VAL_ 2193667331 ENG_IsgFuelCnsmptDis 0 "Not fuel consumption" 1 "Fuel consumption(=1mL)" 2 "Not used" 3 "Error indicator" ;
VAL_ 2193667331 ENG_FuelCapOpnSta 0 "Fuel cap isn't opened" 1 "Fuel cap is opened" 2 "Not used" 3 "Error indicator" ;
VAL_ 2193667331 ENG_EcoDrvActvSta 0 "Active Eco Drive is not active" 1 "Active Eco Drive is active" 2 "Not used" 3 "Error indicator" ;
VAL_ 2193667331 ENG_EngRunSta 0 "Engine Stop or Starting Phase" 1 "Engine Running" 2 "Not used" 3 "Error indicator" ;
VAL_ 2193667331 ENG_Isg2Sta 0 "Default" 1 "The condition for not-activated battery sensor. (Except EOL condition.)" 2 "In Auto Start status, when rapidly accelerating before complete gear shift. (Economy ISG Only)" 3 "Error indicator" ;
VAL_ 2193667331 ENG_IgnOnSta 0 "KEY OFF, control unit in self-holding phase" 1 "KEY ON" 2 "Not used" 3 "Error indicator" ;
VAL_ 2193667331 ENG_Ack4TcsSta 0 "TCS message not received within the last 500 ms, or a plausibility error in torque intervention is ON" 1 "TCS message received, and no plausibility error" 2 "Not used" 3 "Error indicator" ;
VAL_ 2193667331 ENG_FuelCutOffSta 0 "Engine not in fuel cut off" 1 "Engine in fuel cut off" 2 "Not used" 3 "Error indicator" ;
VAL_ 2193667331 ENG_CrctTqSta 0 "The desired intervention regarding ignition angle retardation and cylinder shut-off is executed. (Default value)" 1 "The desired intervention regarding ignition angle retardation and cylinder shut-off is executed; however, the requested target torque can not be adjusted precisely (torque steps)" 2 "The torque reduction regarding the ignition angle retardation cannot be completely executed. A cylinder shut-off is not possible at this time." 3 "Due to a failure detected the desired torque intervention for TCS regarding the ignition angle and cylinder shut-off is no longer executed." ;
VAL_ 2193667331 ENG_AirCompRlySta 0 "Air conditioner compressor relay OFF" 1 "Air conditioner compressor relay ON" 2 "Not used" 3 "Error indicator" ;
VAL_ 2193667331 ENG_LnchCntrlSta 0 "Off state" 1 "Standby" 2 "Ready" 3 "Lanch" 4 "Error indicator" ;
VAL_ 2193667331 ENG_GearShftUpDis 0 "Gear Shiftup Display Off" 1 "Gear Shiftup Display On" 2 "Not used" 3 "Error indicator" ;
VAL_ 2193667332 ENG_VehSpdHiVal 511 "Error indicator" ;
VAL_ 2193667332 ENG_EngInhbNCC 0 "NCC Inhibition OFF" 1 "NCC Inhibition ON" 2 "Not used" 3 "Error indicator" ;
VAL_ 2193667332 ENG_SldSwSta 0 "Speed limiter function is OFF" 1 "Speed limiter function is Active(Kickdown)" 2 "Speed limiter function is Pause" 3 "Error indicator" ;
VAL_ 2193667332 ENG_SldDrvAlertDisp 0 "Default" 1 "SldDisengaged" 2 "NoSldEngaged" 3 "ErrorIndicator" ;
VAL_ 2193667332 ENG_VehSpdLimVal 511 "Error indicator" ;
VAL_ 2244048129 ESC_Crc3Val 0 "0x0x0~0xFFFF:CRCValue" 65535 "0x0x0~0xFFFF:CRCValue" ;
VAL_ 2244048129 ESC_AlvCnt3Val 0 "0x0x0~0xFF:AlvCntValue" 255 "0x0x0~0xFF:AlvCntValue" ;
VAL_ 2244048129 ESC_VehAccelVal 2047 "Error" ;
VAL_ 2244048129 ESC_AccelBasisVal 2047 "Error" ;
VAL_ 2244048129 PWI_STATE 0 "nomarl" 1 "pad wear" 2 "reserved" 3 "invaild or Error" ;
VAL_ 2244048130 SCC_OptTyp 0 "SCC is not equipped" 1 "SCC is equipped" 2 "Not used" 3 "Not Coded" ;
VAL_ 2244048130 ESC_BrkLtReq 0 "No request" 1 "Activate brake lights" 2 "Not used" 3 "Error Indicator" ;
VAL_ 2244048130 ESC_DclEnblReq 0 "Disable deceleration control" 1 "Enable deceleration control" 2 "Not used" 3 "Error Indicator" ;
VAL_ 2244048130 ESC_DrvOvrdSta 0 "No override" 1 "Override by acceleration pedal" 2 "Override by deceleration" 3 "Error Indicator" ;
VAL_ 2244048130 ESC_DrvBrkSta 0 "Driver is not braking / failure" 1 "Driver is braking" 2 "Not used" 3 "Error Indicator" ;
VAL_ 2244048130 SCC_EnblReq 0 "SCC enabled" 1 "SCC disabled reversible" 2 "SCC disabled irreversible" 3 "SCC disabled irreversible due to communication error" ;
VAL_ 2244048130 ESC_DrvBrkActvSta 0 "Brake pedal not pressed" 1 "Brake pedal pressed" 2 "Not used" 3 "Error Indicator" ;
VAL_ 2244048130 ESC_PrkBrkActvSta 0 "Parking brake is not activated" 1 "Parking brake is activated" 2 "Not used" 3 "Error Indicator" ;
VAL_ 2244048130 ESC_HDP_FltMonSta 0 "No Fault" 1 "Main Controller Fault Detected (ADAS_DRV 2)" 2 "Sub Controller Fault Detected (FR_CMR)" 3 "Main & Sub Controller Fault Detected (ADAS_DRV 2 & FR_CMR)" 4 "Reserved" 5 "Reserved" 6 "Reserved" 7 "Reserved" ;
VAL_ 2244048130 ESC_HDPSpprtSWVer 0 "Not Supported" 1 "SW Version" 2 "SW Version" 3 "SW Version" 4 "SW Version" 5 "SW Version" 6 "SW Version" 7 "SW Version" 8 "SW Version" 9 "SW Version" 10 "SW Version" 11 "SW Version" 12 "SW Version" 13 "SW Version" 14 "SW Version" 15 "SW Version" 16 "SW Version" 17 "SW Version" 18 "SW Version" 19 "SW Version" 20 "SW Version" 21 "SW Version" 22 "SW Version" 23 "SW Version" 24 "SW Version" 25 "SW Version" 26 "SW Version" 27 "SW Version" 28 "SW Version" 29 "SW Version" 30 "SW Version" 31 "SW Version" ;
VAL_ 2244048130 FCA_EquipSta 0 "FCA is not equipped" 1 "FCA is equipped" 2 "Not used" 3 "Not Coded" ;
VAL_ 2244048130 FCA_AvlblSta 0 "Available" 1 "Temporarily not available" 2 "Permanently not available" 3 "FCA Communication Error" ;
VAL_ 2244048130 ESC_FCA_ActvSta 0 "FCA Brake is not in activation" 1 "FCA Pre-Brake" 2 "FCA Full-Brake" 3 "Invalid" ;
VAL_ 2244048130 ESC_DBS_ActvSta 0 "DBS control is inactive" 1 "DBS control is active" 2 "Not used" 3 "Not used" ;
VAL_ 2244048130 SCC_TqReq 0 "No request" 1 "Enable SCC torque request" 2 "Not used" 3 "Error Indicator" ;
VAL_ 2244048130 ESC_HDP_EgSta 0 "Not engaged" 1 "Engaged in main controller by IEB (ESC)" 2 "Engaged in sub controller by IEB (ESC)" 3 "MRM with IEB (ESC) alone" 4 "Engaged in main controller by RCU" 5 "Engaged in sub controller by RCU" 6 "MRM with RCU alone" 7 "Engaged in sub controller by IEB (ESC), but RCU Signa" ;
VAL_ 2244048130 ESC_HDP_EnblReq 0 "No Fault" 1 "Req. longitudinal control normal, Functional Fault" 2 "Req. longitudinal control normal, Partial performance degradation" 3 "Req. longitudinal control abnormal, Brake control possible" 4 "Req. longitudinal control abnormal, Brake control impossible" 5 "Req. longitudinal control normal, Acceleration control Fault (eg. Engine Fault)" 6 "HDP disabled reversible" 7 "Reserved" ;
VAL_ 2244048130 CSC_Sta 0 "Not Control(Default)" 1 "Control" 2 "Reserved" 3 "Error Indicator" ;
VAL_ 2244048130 CSC_WrngSta 0 "Not Control(Default)" 1 "Control(w/ sound)" 2 "Control(w/o sound)" 3 "Error Indicator" ;
VAL_ 2244048130 ESC_BrkdFltStndstill 0 "Undetected" 1 "Detected" 2 "Not used" 3 "Not used" ;
VAL_ 2244048130 SCC_ReqLimSta 0 "No request" 1 "Limited No Limitation" 2 "Acceleration Limited" 3 "Deceleration Limited" ;
VAL_ 2244048130 ESC_StdStillVal 0 "No stand still detected" 1 "stand still detected" 2 "Not used" 3 "Error Indicator" ;
VAL_ 2244048131 ESC_RccaSta 0 "RCCA availble" 1 "RCCA brake started" 2 "RCCA braking is ended" 3 "RCCA braking error" ;
VAL_ 2244048131 ESC_RspaCanFlFlag 0 "ESC received RSPA CAN message successfully" 1 "ESC failed to receive RSPA CAN message successfully" 2 "Not used" 3 "Error Indicator" ;
VAL_ 2244048131 ESC_RspaDclActv 0 "Inactive" 1 "Active" 2 "Not used" 3 "Error Indicator" ;
VAL_ 2244048131 ESC_RspaStandStill 0 "Initial" 1 "ESC stopped the vehicle by RSPA request" 2 "Not used" 3 "Error Indicator" ;
VAL_ 2244048131 ESC_PcaSta 0 "PCA available" 1 "PCA brake started" 2 "PCA brake ended" 3 "PCA disable" ;
VAL_ 2244048131 ESC_LdOpn 0 "Default" 1 "Request_Unlock" 2 "Requesst_Lock" 3 "RESERVED" 4 "RESERVED" 5 "RESERVED" 6 "RESERVED" 7 "RESERVED" ;
VAL_ 2244048131 MCB_ReqBrkAck 0 "Wait Status for Crash" 1 "Received ACU Crash Information" 2 "Not used" 3 "Not used" ;
VAL_ 2244048131 MCB_CtlSta 0 "Not Activation" 1 "Activation" ;
VAL_ 2244048131 MCB_DefSta 0 "Normal state" 1 "Fail" ;
VAL_ 2244048131 ESC_DiffBrkFuncSta 0 "Differential braking available without error" 1 "Differential braking disable" 2 "Differential braking is activated" 3 "Error Indicator" ;
VAL_ 2244048131 ESC_LsdLimMod 0 "Maximum limitation mode" 1 "Minimum limitation mode" ;
VAL_ 2244048131 ESC_LsdOpn 0 "Passive" 1 "Fast Open" 2 "Slow Open" 3 "Torque Limit" 4 "eLSD Fail OPEN" 5 "Reserved" 6 "Reserved" 7 "Error" ;
VAL_ 2244048131 ESC_BcaRPlusSta 0 "BCA-R+ available" 1 "BCA-R+ braking is started" 2 "BCA-R+ braking is ended" 3 "BCA-R+ braking error" ;
VAL_ 2244048131 ESC_RspaSta 0 "Not used" 1 "ESC Initial" 2 "ESC New Start" 3 "ESC Ready" 4 "Not used" 5 "ESC Assist" 6 "ESC Assist Fail" 7 "ESC Abort" 8 "ESC Ready Fail" ;
VAL_ 1189 C_RLTiltUpSw_HU 0 "Default" 1 "Off" 2 "On" 3 "Invalid" ;
VAL_ 1189 C_RRTiltDownSw_HU 0 "Default" 1 "Off" 2 "On" 3 "Invalid" ;
VAL_ 1189 C_RRTiltUpSw_HU 0 "Default" 1 "Off" 2 "On" 3 "Invalid" ;
VAL_ 1189 C_RLRclBwdSw_HU 0 "Default" 1 "Off" 2 "On" 3 "Invalid" ;
VAL_ 1189 C_RLRclFwdSw_HU 0 "Default" 1 "Off" 2 "On" 3 "Invalid" ;
VAL_ 1189 C_RLFldSw_HU 0 "Default" 1 "Off" 2 "On" 3 "Invalid" ;
VAL_ 1189 C_RRRclBwdSw_HU 0 "Default" 1 "Off" 2 "On" 3 "Invalid" ;
VAL_ 1189 C_RRRclFwdSw_HU 0 "Default" 1 "Off" 2 "On" 3 "Invalid" ;
VAL_ 1189 C_TLHrestFldSw_HU 0 "Default" 1 "Off" 2 "On" 3 "Invalid" ;
VAL_ 1189 C_TRHrestFldSw_HU 0 "default" 1 "OFF" 2 "ON" 3 "Invalid" ;
VAL_ 1189 C_TLFldSw_HU 0 "Default" 1 "Off" 2 "On" 3 "Invalid" ;
VAL_ 1189 C_TRFldSw_HU 0 "Default" 1 "Off" 2 "On" 3 "Invalid" ;
VAL_ 1189 C_RRFldSw_HU 0 "Default" 1 "Off" 2 "On" 3 "Invalid" ;
VAL_ 1189 C_RLTiltDownSw_HU 0 "Default" 1 "Off" 2 "On" 3 "Invalid" ;
VAL_ 1185 C_AstWindowCmdAVN 0 "No action" 1 "Manual Down" 2 "Manual Up" 3 "25% Open" 4 "50%Open" 5 "Auto Down" 6 "Auto Up" 7 "15% Open" 8 "Unused" 9 "Unused" 10 "Unused" 11 "Unused" 12 "Unused" 13 "Unused" 14 "Unused" 15 "Invalid" ;
VAL_ 1185 C_RrDefoggerCmdAVN 0 "Off" 1 "On" 2 "Reserved" 3 "Invalid" ;
VAL_ 1185 C_RrBlindCmdAVN 0 "No Action" 1 "Blind Auto Open" 2 "Blind Auto Close" 3 "Invalid" ;
VAL_ 1185 C_RrGlassCmdAVN 0 "No Action" 1 "Glass Auto Open" 2 "Glass Auto Close" 3 "Invalid" ;
VAL_ 1185 C_RRWindowCmdAVN 0 "No action" 1 "Manual Down" 2 "Manual Up" 3 "25% Open" 4 "50% Open" 5 "Auto Down" 6 "Auto Up" 7 "15% Open" 8 "Unused" 9 "Unused" 10 "Unused" 11 "Unused" 12 "Unused" 13 "Unused" 14 "Unused" 15 "Invalid" ;
VAL_ 1185 C_RLWindowCmdAVN 0 "No action" 1 "Manual Down" 2 "Manual Up" 3 "25% Open" 4 "50% Open" 5 "Auto Down" 6 "Auto UP" 7 "15% Open" 8 "Unused" 9 "Unused" 10 "Unused" 11 "Unused" 12 "Unused" 13 "Unused" 14 "Unused" 15 "Invalid" ;
VAL_ 1185 C_BlindCmdAVN 0 "No Action" 1 "R_Blind Auto Open" 2 "R_Blind Auto Close" 3 "Stop" 4 "reserved" 5 "reserved" 6 "reserved" 7 "Invalid" ;
VAL_ 1185 C_GlassCmdAVN 0 "No Action" 1 "Glass Auto Open" 2 "Glass Auto Close" 3 "Glass Auto Tilt Up" 4 "Stop" 5 "reserved" 6 "reserved" 7 "Invalid" ;
VAL_ 1185 C_DrvWindowCmdAVN 0 "No action" 1 "Manual Down" 2 "Manual Up" 3 "25% Open" 4 "50% Open" 5 "Auto Down" 6 "Auto Up" 7 "15% Open" 8 "Unused" 9 "Unused" 10 "Unused" 11 "Unused" 12 "Unused" 13 "Unused" 14 "Unused" 15 "Invalid" ;
VAL_ 1185 C_PTGCNTLCmdAVN 0 "Close" 1 "Open" 2 "Reserved" 3 "Invalid" ;
VAL_ 1193 C_PTGMNValueSet 0 "Default" 1 "Power Mode" 2 "Manual Mode" 3 "Invalid" ;
VAL_ 1193 CF_AVN_PSMNValueSet 0 "Default" 1 "Off(Disable)" 2 "50mm On(Enable)" 3 "75mm On(Enable)" 4 "Reserved" 5 "Reserved" 6 "Reserved" 7 "Invalid" ;
VAL_ 1193 C_HfreeTrunkTgNValueSet 0 "Default" 1 "HandsFree Off" 2 "HandsFree On" 3 "Reserved" 4 "Invalid" 5 "Reserved" 6 "Reserved" 7 "Reserved" ;
VAL_ 1193 CF_AVN_TrfChgSet 0 "Default" 1 "Disable(Off)" 2 "Enable(On)" 3 "Invalid" ;
VAL_ 1193 CF_AVN_SCMNValueSet 0 "Default" 1 "Steering Off" 2 "Steering On" 3 "Invalid" ;
VAL_ 1193 CF_AVN_ADrUNValueSet 0 "Default" 1 "Off" 2 "Key Out On(All Doors)" 3 "Shift Lever On(All Doors)" 4 "Override" 5 "Invalid" 6 "Key Out On(Driver Door)" 7 "Shift Lever On(Driver Door)" ;
VAL_ 1193 CF_AVN_OTTurnNValueSet 0 "Default" 1 "One Touch Turn Off" 2 "3 Flashing" 3 "5 Flashing" 4 "7 Flashing" 5 "Invalid" 6 "Reserved" 7 "Reserved" ;
VAL_ 1193 CF_Gway_WPCNValueSet 0 "Default" 1 "Off(Disable)" 2 "On(Enable)" 3 "Invalid" ;
VAL_ 1193 C_AVN_RearWiperNValueSet 0 "Default" 1 "Rear Wiper(Reverse) Off" 2 "Rear Wiper(Reverse) On" 3 "Invalid" ;
VAL_ 1193 C_UnlockWelocomeNValueSet 0 "Default" 1 "Off" 2 "On" 3 "Invalid" ;
VAL_ 1193 C_SmartWelocomeNValueSet 0 "Default" 1 "Off" 2 "On" 3 "Invalid" ;
VAL_ 1193 CF_AVN_PTGSpeedNValueSet 0 "Default" 1 "Fast" 2 "Slow" 3 "Invalid" ;
VAL_ 1193 CR_Datc_DRSeatWheel_USM_Set 0 "Default" 1 "Off" 2 "On" 3 "Invalid" ;
VAL_ 1193 CF_AVN_TTUnlockNValueSet 0 "Default" 1 "Off" 2 "On" 3 "Invalid" ;
VAL_ 1193 CF_Gway_RWPCNValueSet 0 "Default" 1 "Off" 2 "On" 3 "Invalid" ;
VAL_ 1193 CF_Avn_HAPTICWARNINGNValueSet 0 "Default" 1 "Weak" 2 "Medium" 3 "Strong" 4 "Reserved" 5 "Reserved" 6 "Off" 7 "Invalid" ;
VAL_ 1193 CR_Datc_DRSeatHeat_USM_Set 0 "Default" 1 "Off" 2 "On" 3 "Invalid" ;
VAL_ 1193 C_WALNValueSet 0 "Default" 1 "Off" 2 "On" 3 "Invalid" ;
VAL_ 1193 C_ApprUnlockNValue 0 "Defualt" 1 "Approach Unlock OFF" 2 "Approach Unlock ON" 3 "Invalid" ;
VAL_ 1193 CF_AVN_EscortHLNValueSet 0 "Default" 1 "Escort Off" 2 "Escort On" 3 "Invalid" ;
VAL_ 1195 CF_AVN_CluWelcomeSnd 0 "Default" 1 "Off" 2 "On" 3 "Invalid" ;
VAL_ 1195 CF_AVN_CluTransmissionDisp 0 "Default" 1 "Off" 2 "On" 3 "Invalid" ;
VAL_ 1195 CF_AVN_CluWiperLight 0 "Default" 1 "Off" 2 "On" 3 "Invalid" ;
VAL_ 1195 CF_AVN_CluRoadInfoGuide 0 "Default" 1 "Off" 2 "On" 3 "Invalid" ;
VAL_ 1195 CF_AVN_CluUserSettingPeriod 0 "0~99month" 1 "0~99month" 2 "0~99month" 3 "0~99month" 4 "0~99month" 5 "0~99month" 6 "0~99month" 7 "0~99month" 8 "0~99month" 9 "0~99month" 10 "0~99month" 11 "0~99month" 12 "0~99month" 13 "0~99month" 14 "0~99month" 15 "0~99month" 16 "0~99month" 17 "0~99month" 18 "0~99month" 19 "0~99month" 20 "0~99month" 21 "0~99month" 22 "0~99month" 23 "0~99month" 24 "0~99month" 25 "0~99month" 26 "0~99month" 27 "0~99month" 28 "0~99month" 29 "0~99month" 30 "0~99month" 31 "0~99month" 32 "0~99month" 33 "0~99month" 34 "0~99month" 35 "0~99month" 36 "0~99month" 37 "0~99month" 38 "0~99month" 39 "0~99month" 40 "0~99month" 41 "0~99month" 42 "0~99month" 43 "0~99month" 44 "0~99month" 45 "0~99month" 46 "0~99month" 47 "0~99month" 48 "0~99month" 49 "0~99month" 50 "0~99month" 51 "0~99month" 52 "0~99month" 53 "0~99month" 54 "0~99month" 55 "0~99month" 56 "0~99month" 57 "0~99month" 58 "0~99month" 59 "0~99month" 60 "0~99month" 61 "0~99month" 62 "0~99month" 63 "0~99month" 64 "0~99month" 65 "0~99month" 66 "0~99month" 67 "0~99month" 68 "0~99month" 69 "0~99month" 70 "0~99month" 71 "0~99month" 72 "0~99month" 73 "0~99month" 74 "0~99month" 75 "0~99month" 76 "0~99month" 77 "0~99month" 78 "0~99month" 79 "0~99month" 80 "0~99month" 81 "0~99month" 82 "0~99month" 83 "0~99month" 84 "0~99month" 85 "0~99month" 86 "0~99month" 87 "0~99month" 88 "0~99month" 89 "0~99month" 90 "0~99month" 91 "0~99month" 92 "0~99month" 93 "0~99month" 94 "0~99month" 95 "0~99month" 96 "0~99month" 97 "0~99month" 98 "0~99month" 99 "0~99month" 100 "Reserved" 101 "Reserved" 102 "Reserved" 103 "Reserved" 104 "Reserved" 105 "Reserved" 106 "Reserved" 107 "Reserved" 108 "Reserved" 109 "Reserved" 110 "Reserved" 111 "Reserved" 112 "Reserved" 113 "Reserved" 114 "Reserved" 115 "Reserved" 116 "Reserved" 117 "Reserved" 118 "Reserved" 119 "Reserved" 120 "Reserved" 121 "Reserved" 122 "Reserved" 123 "Reserved" 124 "Reserved" 125 "Reserved" 126 "Reserved" 127 "Invalid" ;
VAL_ 1195 CF_AVN_CluFuelEconUnit_mi 0 "Default" 1 "US gallon" 2 "UK gallon" 3 "Reserved" ;
VAL_ 1195 CF_AVN_CluFuelEconUnit_km 0 "Default" 1 "km/L, km/kg, km/kWh" 2 "L/100km, kg/100km, kWh/100km" 3 "Reserved" ;
VAL_ 1195 CF_AVN_CluUserSettingDistance 0 "0x0x0~0x1869F:0~9999km_mi" 99999 "0x0x0~0x1869F:0~9999km_mi" 131071 "Invalid" ;
VAL_ 1195 CF_AVN_CluRheostatLvl 0 "Reserved" 1 "Step 1" 2 "Step 2" 3 "Step 3" 4 "Step 4" 5 "Step 5" 6 "Step 6" 7 "Step 7" 8 "Step 8" 9 "Step 9" 10 "Step 10" 11 "Step 11" 12 "Step 12" 13 "Step 13" 14 "Step 14" 15 "Step 15" 16 "Step 16" 17 "Step 17" 18 "Step 18" 19 "Step 19" 20 "Step 20(Reset Value)" 21 "Step 21(Detent)" 22 "Reserved" 23 "Reserved" 24 "Reserved" 25 "Reserved" 26 "Reserved" 27 "Reserved" 28 "Reserved" 29 "Reserved" 30 "Reserved" 31 "Invalid" ;
VAL_ 1195 CF_AVN_EVReset 0 "Default" 1 "USM Reset" 2 "Reserved" 3 "Invalid" ;
VAL_ 1195 CF_AVN_UnitReset 0 "Default" 1 "Unit Reset" 2 "Reserved" 3 "Invalid" ;
VAL_ 1195 CF_AVN_IcyRoadWarn 0 "Default" 1 "Off" 2 "On" 3 "Invalid" ;
VAL_ 1195 CF_AVN_CluServiceReminderReset 0 "Default" 1 "Service Reminder Reset" 2 "Reserved" 3 "Invalid" ;
VAL_ 1195 CF_AVN_CluUSMReset 0 "Default" 1 "USM Reset" 2 "Reserved" 3 "Invalid" ;
VAL_ 1195 CF_AVN_CluServiceReminderSet 0 "Default" 1 "Off" 2 "On" 3 "Invalid" ;
VAL_ 1196 C_HCIMSWeightNValueSet 0 "Default" 1 "Under 49.4kg" 2 "49.5~59.4kg" 3 "59.5~69.4kg" 4 "69.5~79.4kg" 5 "79.5~89.4kg" 6 "89.5~99.4kg" 7 "99.5~109.4kg" 8 "109.5~119.4kg" 9 "More than 119.5kg" 10 "Reserved" 11 "Reserved" 12 "Reserved" 13 "Reserved" 14 "Reserved" 15 "Invalid" ;
VAL_ 1196 C_HCIMSSitHeightNValueSet 0 "Default" 1 "Tall" 2 "Middle" 3 "Short" 4 "Reserved" 5 "Reserved" 6 "Reserved" 7 "Reserved" 8 "Reserved" 9 "Reserved" 10 "Reserved" 11 "Reserved" 12 "Reserved" 13 "Reserved" 14 "Reserved" 15 "Invalid" ;
VAL_ 1196 CF_AVN_BodySpprtSet 0 "Default" 1 "Off" 2 "On" 3 "Invalid" ;
VAL_ 1196 CF_AVN_AirSptTimeNValueSet 0 "Default" 1 "Short" 2 "Normal" 3 "Long" 4 "Reserved" 5 "Reserved" 6 "Reserved" 7 "Invalid" ;
VAL_ 1196 CF_AVN_AirSptStrNValue 0 "Default" 1 "Normal" 2 "Intense" 3 "Invalid" ;
VAL_ 1196 CF_AVN_SeatDrvModNValueSet 0 "Default" 1 "Off" 2 "On" 3 "Invalid" ;
VAL_ 1196 C_HCIMSHeightNvalueSet 0 "Default" 1 "Less than 147.5cm" 2 "147.5~152.4cm" 3 "152.5~157.4cm" 4 "157.5~162.4cm" 5 "162.5~167.4cm" 6 "167.5~172.4cm" 7 "172.5~177.4cm" 8 "177.5~182.4cm" 9 "182.5~187.4cm" 10 "187.5~192.4cm" 11 "192.5~197.4cm" 12 "more than 197.5cm" 13 "Reserved" 14 "Reserved" 15 "Invalid" ;
VAL_ 1196 C_SmrtSldngDrNValueSet 0 "Default" 1 "Off" 2 "On" 3 "Reserved" 4 "Reserved" 5 "Reserved" 6 "Reserved" 7 "Invalid" ;
VAL_ 1196 CF_AVN_TurboPressureUnit 0 "Default" 1 "Psi" 2 "kPa" 3 "bar" 4 "Reserved" 5 "Reserved" 6 "Reserved" 7 "Invalid" ;
VAL_ 1196 CF_AVN_CluTorqueUnit 0 "Default" 1 "Nm" 2 "lb_ft" 3 "Invalid" ;
VAL_ 1196 CF_AVN_HCIMSButtonCommand 0 "Default" 1 "Health Care IMS Exit" 2 "Detail View" 3 "Move to recommend position" 4 "Current position Analysis" 5 "Move to setting page" 6 "Save view" 7 "IMS1 saved" 8 "IMS2 saved" 9 "Summary view" 10 "Smart IMS On" 11 "Reserved" 12 "Reserved" 13 "Reserved" 14 "Reserved" 15 "Invalid" ;
VAL_ 2164277252 TCU_NetrlCtrlSta 0 "No NC" 1 "NC Entry" 2 "NC Applied" 3 "NC Exit" ;
VAL_ 2164277252 TCU_ShftPtrnSta 0 "Normal (ECO)" 1 "Uphill 1 (Optional)" 2 "Uphill 2 (Optional)" 3 "Reserved" 4 "Downhill 1 (Optional)" 5 "Cruise (Optional)" 6 "Cruise_Uphill 1 (Optional)" 7 "Cruise_Uphill 2 (Optional)" 8 "Active ECO (Optional)" 9 "Sport Drive (Optional)" 15 "None of the above" ;
VAL_ 2164277252 TCU_EPBReq 0 "No Request (default)" 1 "EPB Request" ;
VAL_ 2164277252 IMT_EOLstate 0 "display gear info using 'TCU_GearSlctDis'" 1 "display gear info by alphabet 'E'" ;
VAL_ 2164277252 IMT_DisCmd 0 "Not Display" 1 "Display (Not blinking)" 2 "Display (blinking)" 3 "Reserved" ;
VAL_ 2164277252 DCT_RegenInhbt 0 "No Inhibit" 1 "Regen. Inhibit" 2 "Not Used" 3 "Error Indicator" ;
VAL_ 2164277252 DCT_EngIdleReq 0 "No Request" 1 "Idle Request" 2 "Not Used" 3 "Error Indicator" ;
VAL_ 2164277252 DCT_CltchState 0 "Drivetrain (Both Clutch) Open" 1 "Odd Clutch Slipping" 2 "Even Clutch Slipping" 3 "Clutch Locked" ;
VAL_ 2164277252 DCT_FuelCutReq 0 "No request" 1 "Fuel Cut Request" 2 "Not Used" 3 "Error Indicator" ;
VAL_ 2164277252 DCT_TqIncReq 0 "No Request" 1 "Torque increase Request" 2 "Not Used" 3 "Error Indicator" ;
VAL_ 2164277252 DCT_ShftTqReq 0 "No request" 2047 "Max. Increase" 2048 "reduction to 0 torque" ;
VAL_ 2164277252 TCU_VgisInhbtReq 0 "There¡¯s no request from TCU" 1 "TCU inhibits ECU from changing VGIS status" 2 "Not used" 3 "Error Indicator" ;
VAL_ 2164277252 TCU_EngTqIncReqVal 0 "No request" 2047 "Max. Increase" 2048 "reduction to 0 torque" ;
VAL_ 2189467649 WHL_Crc1Val 0 "0x0x0~0xFFFF:CRCValue" 65535 "0x0x0~0xFFFF:CRCValue" ;
VAL_ 2189467649 WHL_AlvCnt1Val 0 "0x0x0~0xFF:AlvCntValue" 255 "0x0x0~0xFF:AlvCntValue" ;
VAL_ 2189467649 WHL_PlsFLVal 255 "Error" ;
VAL_ 2189467649 WHL_PlsFRVal 255 "Error" ;
VAL_ 2189467649 WHL_PlsRLVal 255 "Error" ;
VAL_ 2189467649 WHL_PlsRRVal 255 "Error" ;
VAL_ 2189467649 WHL_DirFLVal 0 "Unknown (Wheel moving stop state or Not applied wheel sensor for direction)" 1 "Forward direction" 2 "Backward direction" 3 "Error identifier" ;
VAL_ 2189467649 WHL_DirFRVal 0 "Unknown (Wheel moving stop state or Not applied wheel sensor for direction)" 1 "Forward direction" 2 "Backward direction" 3 "Error identifier" ;
VAL_ 2189467649 WHL_DirRLVal 0 "Unknown (Wheel moving stop state or Not applied wheel sensor for direction)" 1 "Forward direction" 2 "Backward direction" 3 "Error identifier" ;
VAL_ 2189467649 WHL_DirRRVal 0 "Unknown (Wheel moving stop state or Not applied wheel sensor for direction)" 1 "Forward direction" 2 "Backward direction" 3 "Error identifier" ;
VAL_ 2189467650 WHL_SpdFLVal 16383 "Error" ;
VAL_ 2189467650 WHL_SpdFRVal 16383 "Error" ;
VAL_ 2189467650 WHL_SpdRLVal 16383 "Error" ;
VAL_ 2189467650 WHL_SpdRRVal 16383 "Error" ;
